VERSION "dbc-export 1 2026.26.6.5"

NS_ :

BS_:

BU_: ADSP APB APP APS APSB BB BMS CC CMP CMPD CP DAS DI DIF DIR DPB EPAS3P EPAS3S EPASTP EPASTS EPBL EPBR ESP EVSE FC GTW HCML HCMR HVP IBST ICR IDB LS OCS1P ODIN PARK PCS PCS2 PLG PM PMF PMR PNCD PTC RADC RCM RCM2 RCM3 RCU SCCM SCM SCS SDCR TAS TCU TCU2 TPMS TRCM UDS UI UIS UMC USM V2G VC VCBATT VCBATT0 VCBATT1 VCBATT2 VCCC VCFRONT VCFRONT1 VCFRONT2 VCLEFT VCRIGHT VCSEAT2L VCSEAT2R VCSEC VEH

BO_ 666 UI_seatControl: 3 UI
 SG_ UI_seatControlIndex M : 0|2@1+ (1,0) [0|3] "" Vector__XXX
 SG_ UI_3RSeatChildLock m0 : 2|2@1+ (1,0) [0|3] "" Vector__XXX
 SG_ UI_2RowLeftSeatTrackBack m0 : 4|1@1+ (1,0) [0|1] "" Vector__XXX
 SG_ UI_2RowLeftSeatTrackForward m0 : 5|1@1+ (1,0) [0|1] "" Vector__XXX
 SG_ UI_2RowRightSeatTrackBack m0 : 6|1@1+ (1,0) [0|1] "" Vector__XXX
 SG_ UI_2RowRightSeatTrackForward m0 : 7|1@1+ (1,0) [0|1] "" Vector__XXX
 SG_ UI_left3RowSeatAdjustmentRequest m0 : 8|3@1+ (1,0) [0|7] "" Vector__XXX
 SG_ UI_right3RowSeatAdjustmentReques m0 : 11|3@1+ (1,0) [0|7] "" Vector__XXX
 SG_ UI_2RLeftSeatFanReq m0 : 14|2@1+ (1,0) [0|3] "" Vector__XXX
 SG_ UI_2RRightSeatFanReq m0 : 16|2@1+ (1,0) [0|3] "" Vector__XXX
 SG_ UI_leftThirdRowSeatRequestFromRe m0 : 18|1@1+ (1,0) [0|1] "" Vector__XXX
 SG_ UI_rightThirdRowSeatRequestFromR m0 : 19|1@1+ (1,0) [0|1] "" Vector__XXX
 SG_ UI_seatChoreographyStopRequest m0 : 20|1@1+ (1,0) [0|1] "" Vector__XXX

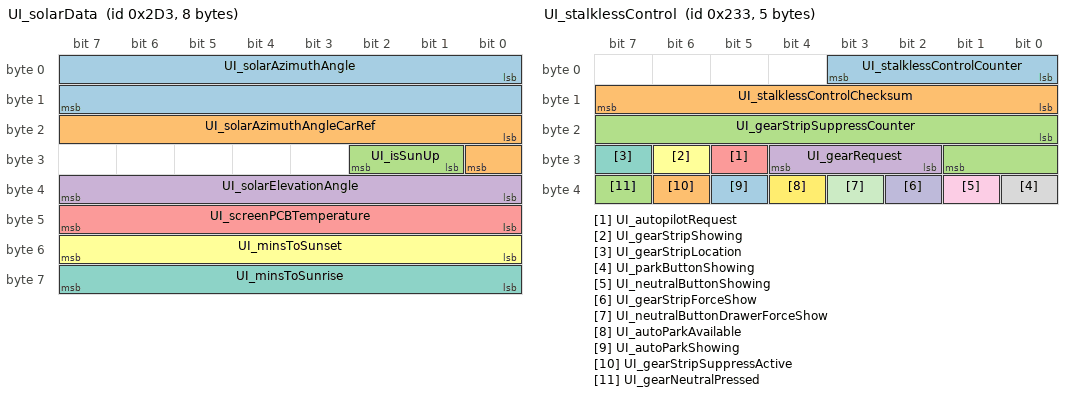
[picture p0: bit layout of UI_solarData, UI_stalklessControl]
BO_ 723 UI_solarData: 8 UI
 SG_ UI_solarAzimuthAngle : 0|16@1- (1,0) [-32768|32767] "degrees" Vector__XXX
 SG_ UI_solarAzimuthAngleCarRef : 16|9@1- (1,0) [-256|254] "degrees" Vector__XXX
 SG_ UI_isSunUp : 25|2@1+ (1,0) [0|2] "" Vector__XXX
 SG_ UI_solarElevationAngle : 32|8@1- (1,0) [-128|126] "degrees" Vector__XXX
 SG_ UI_screenPCBTemperature : 40|8@1- (0.5,40) [-20|100] "degC" Vector__XXX
 SG_ UI_minsToSunset : 48|8@1+ (10,0) [0|2550] "min" Vector__XXX
 SG_ UI_minsToSunrise : 56|8@1+ (10,0) [0|2550] "min" Vector__XXX

BO_ 563 UI_stalklessControl: 5 UI
 SG_ UI_stalklessControlCounter : 0|4@1+ (1,0) [0|15] "" Vector__XXX
 SG_ UI_stalklessControlChecksum : 8|8@1+ (1,0) [0|255] "" Vector__XXX
 SG_ UI_gearStripSuppressCounter : 16|10@1+ (1,0) [0|1023] "" Vector__XXX
 SG_ UI_gearRequest : 26|3@1+ (1,0) [1|7] "" Vector__XXX
 SG_ UI_autopilotRequest : 29|1@1+ (1,0) [0|1] "" Vector__XXX
 SG_ UI_gearStripShowing : 30|1@1+ (1,0) [0|1] "" Vector__XXX
 SG_ UI_gearStripLocation : 31|1@1+ (1,0) [0|1] "" Vector__XXX
 SG_ UI_parkButtonShowing : 32|1@1+ (1,0) [0|1] "" Vector__XXX
 SG_ UI_neutralButtonShowing : 33|1@1+ (1,0) [0|1] "" Vector__XXX
 SG_ UI_gearStripForceShow : 34|1@1+ (1,0) [0|1] "" Vector__XXX
 SG_ UI_neutralButtonDrawerForceShow : 35|1@1+ (1,0) [0|1] "" Vector__XXX
 SG_ UI_autoParkAvailable : 36|1@1+ (1,0) [0|1] "" Vector__XXX
 SG_ UI_autoParkShowing : 37|1@1+ (1,0) [0|1] "" Vector__XXX
 SG_ UI_gearStripSuppressActive : 38|1@1+ (1,0) [0|1] "" Vector__XXX
 SG_ UI_gearNeutralPressed : 39|1@1+ (1,0) [0|1] "" Vector__XXX

BO_ 851 UI_status: 8 UI
 SG_ UI_touchActive : 0|1@1+ (1,0) [0|1] "" Vector__XXX
 SG_ UI_audioActive : 1|1@1+ (1,0) [0|1] "" Vector__XXX
 SG_ UI_bluetoothActive : 2|1@1+ (1,0) [0|1] "" Vector__XXX
 SG_ UI_cellActive : 3|1@1+ (1,0) [0|1] "" Vector__XXX
 SG_ UI_displayReady : 4|1@1+ (1,0) [0|1] "" Vector__XXX
 SG_ UI_displayOn : 5|1@1+ (1,0) [0|1] "" Vector__XXX
 SG_ UI_wifiActive : 6|1@1+ (1,0) [0|1] "" Vector__XXX
 SG_ UI_wifiConnected : 7|1@1+ (1,0) [0|1] "" Vector__XXX
 SG_ UI_systemActive : 8|1@1+ (1,0) [0|1] "" Vector__XXX
 SG_ UI_readyForDrive : 9|1@1+ (1,0) [0|1] "" Vector__XXX
 SG_ UI_cellConnected : 10|1@1+ (1,0) [0|1] "" Vector__XXX
 SG_ UI_vpnActive : 11|1@1+ (1,0) [0|1] "" Vector__XXX
 SG_ UI_autopilotTrial : 12|2@1+ (1,0) [0|3] "" Vector__XXX
 SG_ UI_factoryReset : 14|2@1+ (1,0) [1|3] "" Vector__XXX
 SG_ UI_gpsActive : 16|1@1+ (1,0) [0|1] "" Vector__XXX
 SG_ UI_screenshotActive : 17|1@1+ (1,0) [0|1] "" Vector__XXX
 SG_ UI_radioActive : 18|1@1+ (1,0) [0|1] "" Vector__XXX
 SG_ UI_cellNetworkTechnology : 19|4@1+ (1,0) [0|14] "" Vector__XXX
 SG_ UI_cellReceiverPower : 24|8@1+ (1,-128) [-128|127] "dB" Vector__XXX
 SG_ UI_falseTouchCounter : 32|8@1+ (1,0) [0|255] "1" Vector__XXX
 SG_ UI_developmentCar : 40|1@1+ (1,0) [0|1] "" Vector__XXX
 SG_ UI_cameraActive : 41|1@1+ (1,0) [0|1] "" Vector__XXX
 SG_ UI_cellSignalBars : 42|3@1+ (1,0) [0|6] "" Vector__XXX
 SG_ UI_trailerModeTelltale : 45|2@1+ (1,0) [0|3] "" Vector__XXX
 SG_ UI_pcbTemperature : 48|8@1- (1,40) [-20|100] "degC" Vector__XXX
 SG_ UI_cpuTemperature : 56|8@1- (1,40) [-20|100] "degC" Vector__XXX

BO_ 991 UI_status2: 8 UI
 SG_ UI_mobileAppStepCount : 0|16@1+ (1,0) [0|65535] "" Vector__XXX
 SG_ UI_userRequestSnapshot : 16|1@1+ (1,0) [0|1] "" Vector__XXX
 SG_ UI_touchDetected : 17|1@1+ (1,0) [0|1] "" Vector__XXX
 SG_ UI_validDeviceForEUSummon : 18|1@1+ (1,0) [0|1] "" Vector__XXX
 SG_ UI_locatedAtHome : 19|1@1+ (1,0) [0|1] "" Vector__XXX
 SG_ UI_locatedAtWork : 20|1@1+ (1,0) [0|1] "" Vector__XXX
 SG_ UI_locatedAtFavorite : 21|1@1+ (1,0) [0|1] "" Vector__XXX
 SG_ UI_displayInDarkMode : 22|1@1+ (1,0) [0|1] "" Vector__XXX
 SG_ UI_userActivity : 23|1@1+ (1,0) [0|1] "" Vector__XXX
 SG_ UI_activeTouchPoints : 24|8@1+ (1,0) [0|255] "1" Vector__XXX
 SG_ UI_linkState : 32|2@1+ (1,0) [0|3] "" Vector__XXX
 SG_ UI_sentryModeState : 34|3@1+ (1,0) [0|7] "" Vector__XXX
 SG_ UI_autopilotSentryRequest : 37|1@1+ (1,0) [0|1] "" Vector__XXX
 SG_ UI_mobileAppConnected : 38|1@1+ (1,0) [0|1] "" Vector__XXX
 SG_ UI_phoneLeftInCabin : 39|1@1+ (1,0) [0|1] "" Vector__XXX
 SG_ UI_autoshiftDRState : 40|3@1+ (1,0) [0|7] "" Vector__XXX
 SG_ UI_wifiBtModuleType : 43|3@1+ (1,0) [0|7] "" Vector__XXX
 SG_ UI_sohHealthStatus : 46|2@1+ (1,0) [0|3] "" Vector__XXX
 SG_ UI_selfParkState : 48|8@1+ (1,0) [0|254] "" Vector__XXX
 SG_ UI_summonDeviceIndex : 56|2@1+ (1,0) [0|3] "" Vector__XXX
 SG_ UI_fullScreenMode : 58|1@1+ (1,0) [0|1] "" Vector__XXX
 SG_ UI_sentryModeCameraDetection : 59|1@1+ (1,0) [0|1] "" Vector__XXX
 SG_ UI_wakeOnIPActive : 60|1@1+ (1,0) [0|1] "" Vector__XXX
 SG_ UI_sapActive : 61|1@1+ (1,0) [0|1] "" Vector__XXX
 SG_ UI_sapClients : 62|1@1+ (1,0) [0|1] "" Vector__XXX
 SG_ UI_connectivityStandbyActive : 63|1@1+ (1,0) [0|1] "" Vector__XXX

BO_ 986 UI_status3: 1 UI
 SG_ UI_wifiRegDomain : 0|7@1+ (1,0) [0|127] "" Vector__XXX
 SG_ UI_wifiTethered : 7|1@1+ (1,0) [0|1] "" Vector__XXX

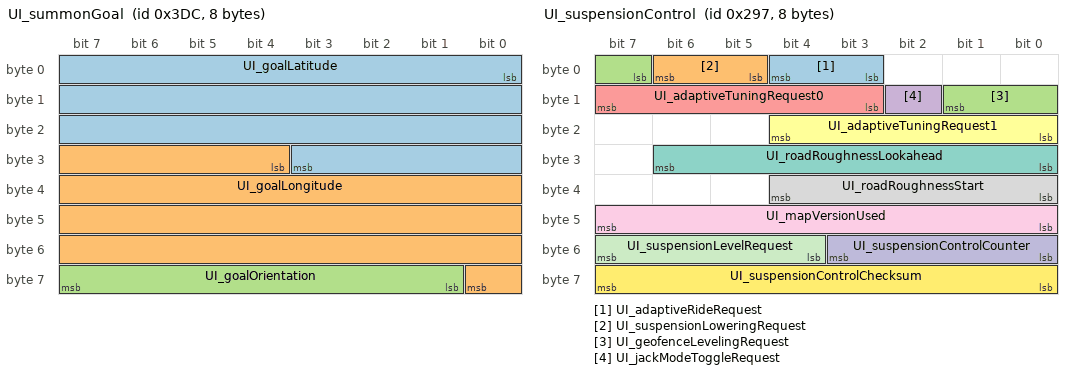
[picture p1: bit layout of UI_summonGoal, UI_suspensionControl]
BO_ 988 UI_summonGoal: 8 UI
 SG_ UI_goalLatitude : 0|28@1- (1.0e-06,0) [-134.217728|134.217727] "deg" Vector__XXX
 SG_ UI_goalLongitude : 28|29@1- (1.0e-06,0) [-268.435456|268.435455] "deg" Vector__XXX
 SG_ UI_goalOrientation : 57|7@1+ (2.8125,0) [0|357.1875] "deg" Vector__XXX

BO_ 663 UI_suspensionControl: 8 UI
 SG_ UI_adaptiveRideRequest : 3|2@1+ (1,0) [0|3] "" Vector__XXX
 SG_ UI_suspensionLoweringRequest : 5|2@1+ (1,0) [0|2] "" Vector__XXX
 SG_ UI_geofenceLevelingRequest : 7|3@1+ (1,0) [0|7] "" Vector__XXX
 SG_ UI_jackModeToggleRequest : 10|1@1+ (1,0) [0|1] "" Vector__XXX
 SG_ UI_adaptiveTuningRequest0 : 11|5@1- (0.1,0) [-1.6|1.5] "-" Vector__XXX
 SG_ UI_adaptiveTuningRequest1 : 16|5@1- (0.1,0) [-1.6|1.5] "-" Vector__XXX
 SG_ UI_roadRoughnessLookahead : 24|7@1+ (0.01,0) [0|1.26] "%" Vector__XXX
 SG_ UI_roadRoughnessStart : 32|5@1+ (10,0) [0|300] "m" Vector__XXX
 SG_ UI_mapVersionUsed : 40|8@1+ (1,0) [0|254] "-" Vector__XXX
 SG_ UI_suspensionControlCounter : 48|4@1+ (1,0) [0|15] "" Vector__XXX
 SG_ UI_suspensionLevelRequest : 52|4@1+ (1,0) [0|15] "" Vector__XXX
 SG_ UI_suspensionControlChecksum : 56|8@1+ (1,0) [0|255] "" Vector__XXX

BO_ 661 UI_systemMonitor: 8 UI
 SG_ UI_systemMonitorIndex M : 0|1@1+ (1,0) [0|1] "" Vector__XXX
 SG_ UI_SystemMemUsage m0 : 8|16@1+ (1,0) [0|65535] "MB" Vector__XXX
 SG_ UI_QtCarMemUsage m0 : 24|16@1+ (1,0) [0|65535] "MB" Vector__XXX
 SG_ UI_QtCarCPUUsage m0 : 40|7@1+ (1,0) [0|127] "%" Vector__XXX
 SG_ UI_emmcStatus m0 : 47|1@1+ (1,0) [0|1] "" Vector__XXX
 SG_ UI_SystemCPUUsage m0 : 48|7@1+ (1,0) [0|127] "%" Vector__XXX
 SG_ UI_HomeHealth m0 : 55|1@1+ (1,0) [0|1] "" Vector__XXX
 SG_ UI_VarHealth m0 : 56|1@1+ (1,0) [0|1] "" Vector__XXX
 SG_ UI_LogHealth m0 : 57|1@1+ (1,0) [0|1] "" Vector__XXX
 SG_ UI_TmpfsHealth m0 : 58|1@1+ (1,0) [0|1] "" Vector__XXX
 SG_ UI_emmcDataWritten m1 : 8|24@1+ (1,0) [0|16777215] "" Vector__XXX
 SG_ UI_emmcTotalErases m1 : 32|16@1+ (1,0) [0|65535] "" Vector__XXX

BO_ 1064 UI_telemetryControl: 8 UI
 SG_ UI_TCR_enable : 0|1@1+ (1,0) [0|1] "" Vector__XXX
 SG_ UI_TCR_moveStateStanding : 1|1@1+ (1,0) [0|1] "" Vector__XXX
 SG_ UI_TCR_moveStateStopped : 2|1@1+ (1,0) [0|1] "" Vector__XXX
 SG_ UI_TCR_moveStateMoving : 3|1@1+ (1,0) [0|1] "" Vector__XXX
 SG_ UI_TCR_moveStateIndeterm : 4|1@1+ (1,0) [0|1] "" Vector__XXX
 SG_ UI_TCR_classConstElem : 5|1@1+ (1,0) [0|1] "" Vector__XXX
 SG_ UI_TCR_classMovingPed : 6|1@1+ (1,0) [0|1] "" Vector__XXX
 SG_ UI_TCR_classMovingTwoWheel : 7|1@1+ (1,0) [0|1] "" Vector__XXX
 SG_ UI_TCR_classMovingFourWheel : 8|1@1+ (1,0) [0|1] "" Vector__XXX
 SG_ UI_TCR_classUnknown : 9|1@1+ (1,0) [0|1] "" Vector__XXX
 SG_ UI_TCR_downSampleFactor : 10|4@1+ (1,0) [0|15] "" Vector__XXX
 SG_ UI_TCR_wExist : 24|5@1+ (1,0) [0|31] "" Vector__XXX
 SG_ UI_TCR_vehSpeed : 32|8@1+ (1,0) [0|255] "" Vector__XXX
 SG_ UI_TCR_minRCS : 40|8@1+ (0.25,-14) [-14|49.75] "dB" Vector__XXX
 SG_ UI_TCR_maxDy : 48|5@1+ (0.5,0) [0|15.5] "m" Vector__XXX
 SG_ UI_TCR_maxObjects : 56|5@1+ (1,0) [0|31] "" Vector__XXX
 SG_ UI_TCR_maxRoadClass : 61|3@1+ (1,0) [0|7] "" Vector__XXX

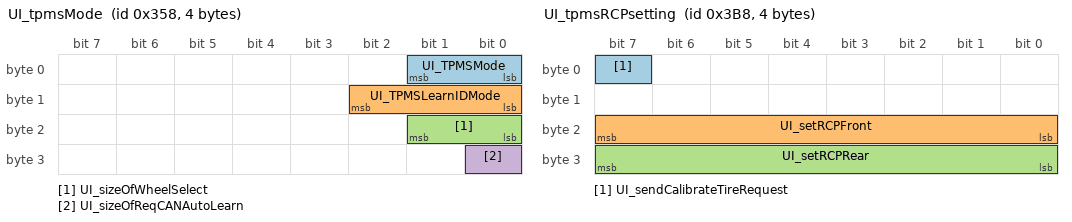
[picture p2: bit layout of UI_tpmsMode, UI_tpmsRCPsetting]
BO_ 856 UI_tpmsMode: 4 UI
 SG_ UI_TPMSMode : 0|2@1+ (1,0) [0|3] "" Vector__XXX
 SG_ UI_TPMSLearnIDMode : 8|3@1+ (1,0) [0|7] "" Vector__XXX
 SG_ UI_sizeOfWheelSelect : 16|2@1+ (1,0) [0|3] "" Vector__XXX
 SG_ UI_sizeOfReqCANAutoLearn : 24|1@1+ (1,0) [0|1] "" Vector__XXX

BO_ 952 UI_tpmsRCPsetting: 4 UI
 SG_ UI_sendCalibrateTireRequest : 7|1@1+ (1,0) [0|1] "" Vector__XXX
 SG_ UI_setRCPFront : 16|8@1+ (0.025,0) [0|6.375] "bar" Vector__XXX
 SG_ UI_setRCPRear : 24|8@1+ (0.025,0) [0|6.375] "bar" Vector__XXX

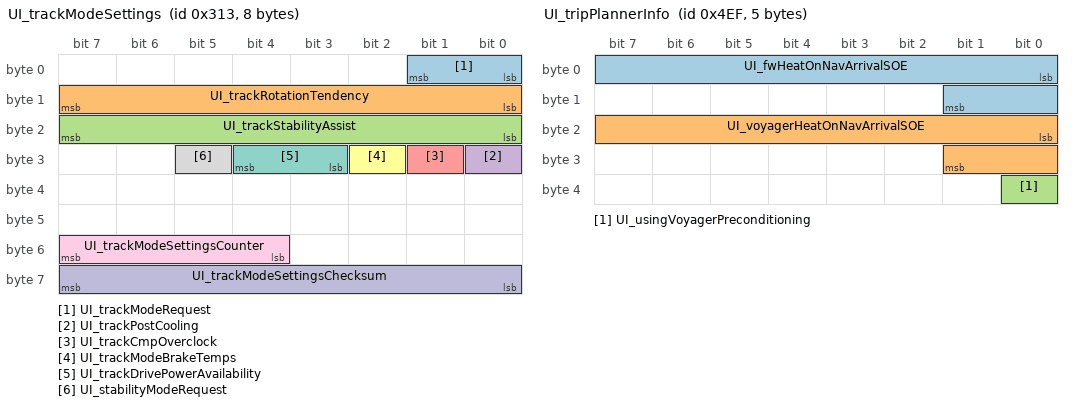
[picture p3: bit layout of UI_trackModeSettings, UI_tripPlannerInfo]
BO_ 787 UI_trackModeSettings: 8 UI
 SG_ UI_trackModeRequest : 0|2@1+ (1,0) [0|3] "" Vector__XXX
 SG_ UI_trackRotationTendency : 8|8@1+ (0.5,0) [0|127.5] "%" Vector__XXX
 SG_ UI_trackStabilityAssist : 16|8@1+ (0.5,0) [0|127.5] "%" Vector__XXX
 SG_ UI_trackPostCooling : 24|1@1+ (1,0) [0|1] "" Vector__XXX
 SG_ UI_trackCmpOverclock : 25|1@1+ (1,0) [0|1] "" Vector__XXX
 SG_ UI_trackModeBrakeTemps : 26|1@1+ (1,0) [0|1] "" Vector__XXX
 SG_ UI_trackDrivePowerAvailability : 27|2@1+ (1,0) [0|3] "" Vector__XXX
 SG_ UI_stabilityModeRequest : 29|1@1+ (1,0) [0|1] "" Vector__XXX
 SG_ UI_trackModeSettingsCounter : 52|4@1+ (1,0) [0|15] "" Vector__XXX
 SG_ UI_trackModeSettingsChecksum : 56|8@1+ (1,0) [0|255] "" Vector__XXX

BO_ 1263 UI_tripPlannerInfo: 5 UI
 SG_ UI_fwHeatOnNavArrivalSOE : 0|10@1+ (0.1,0) [0|100] "%" Vector__XXX
 SG_ UI_voyagerHeatOnNavArrivalSOE : 16|10@1+ (0.1,0) [0|100] "%" Vector__XXX
 SG_ UI_usingVoyagerPreconditioning : 32|1@1+ (1,0) [0|1] "" Vector__XXX

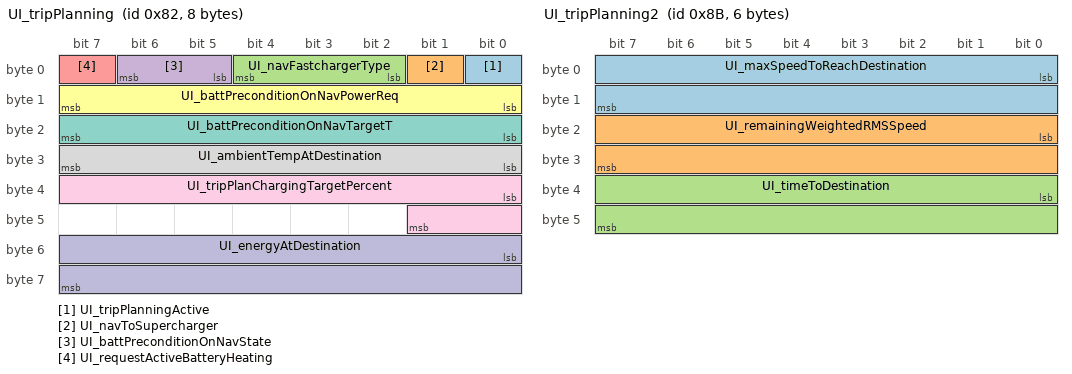
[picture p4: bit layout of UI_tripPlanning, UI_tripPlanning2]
BO_ 130 UI_tripPlanning: 8 UI
 SG_ UI_tripPlanningActive : 0|1@1+ (1,0) [0|1] "" Vector__XXX
 SG_ UI_navToSupercharger : 1|1@1+ (1,0) [0|1] "" Vector__XXX
 SG_ UI_navFastchargerType : 2|3@1+ (1,0) [0|7] "" Vector__XXX
 SG_ UI_battPreconditionOnNavState : 5|2@1+ (1,0) [0|3] "" Vector__XXX
 SG_ UI_requestActiveBatteryHeating : 7|1@1+ (1,0) [0|1] "" Vector__XXX
 SG_ UI_battPreconditionOnNavPowerReq : 8|8@1- (125,0) [-16000|15750] "W" Vector__XXX
 SG_ UI_battPreconditionOnNavTargetT : 16|8@1+ (0.25,0) [0|63.5] "degC" Vector__XXX
 SG_ UI_ambientTempAtDestination : 24|8@1- (0.5,0) [-64|63.5] "degC" Vector__XXX
 SG_ UI_tripPlanChargingTargetPercent : 32|10@1+ (0.1,0) [0|102.2] "%" Vector__XXX
 SG_ UI_energyAtDestination : 48|16@1- (0.01,0) [-327.67|327.67] "kWh" Vector__XXX

BO_ 139 UI_tripPlanning2: 6 UI
 SG_ UI_maxSpeedToReachDestination : 0|16@1+ (0.01,0) [0|655.34] "m/s" Vector__XXX
 SG_ UI_remainingWeightedRMSSpeed : 16|16@1+ (0.01,0) [0|655.34] "m/s" Vector__XXX
 SG_ UI_timeToDestination : 32|16@1+ (1,0) [0|65534] "s" Vector__XXX

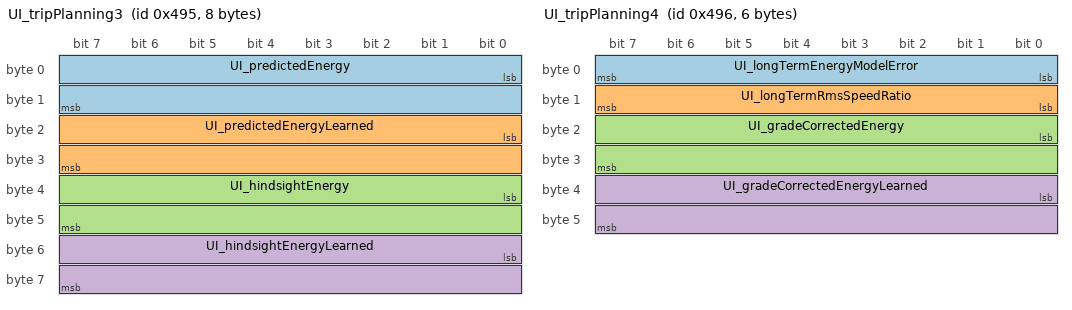
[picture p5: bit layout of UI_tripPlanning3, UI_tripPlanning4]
BO_ 1173 UI_tripPlanning3: 8 UI
 SG_ UI_predictedEnergy : 0|16@1- (0.01,0) [-327.67|327.67] "kWh" Vector__XXX
 SG_ UI_predictedEnergyLearned : 16|16@1- (0.01,0) [-327.68|327.67] "kWh" Vector__XXX
 SG_ UI_hindsightEnergy : 32|16@1- (0.01,0) [-327.67|327.67] "kWh" Vector__XXX
 SG_ UI_hindsightEnergyLearned : 48|16@1- (0.01,0) [-327.68|327.67] "kWh" Vector__XXX

BO_ 1174 UI_tripPlanning4: 6 UI
 SG_ UI_longTermEnergyModelError : 0|8@1- (0.5,0) [-64|63.5] "whpm" Vector__XXX
 SG_ UI_longTermRmsSpeedRatio : 8|8@1+ (0.01,0) [0|2.54] "1" Vector__XXX
 SG_ UI_gradeCorrectedEnergy : 16|16@1- (0.01,0) [-327.68|327.67] "kWh" Vector__XXX
 SG_ UI_gradeCorrectedEnergyLearned : 32|16@1- (0.01,0) [-327.68|327.67] "kWh" Vector__XXX

BO_ 1175 UI_tripPlanning5: 4 UI
 SG_ UI_battPreconditionOnNavTime : 0|16@1+ (1,0) [0|65534] "s" Vector__XXX
 SG_ UI_maxBattPreconditionOnNavTime : 16|16@1+ (1,0) [0|65534] "s" Vector__XXX

BO_ 850 UI_uiHealthStatus: 6 UI
 SG_ UI_centerDisplayRunning : 0|1@1+ (1,0) [0|1] "" Vector__XXX
 SG_ UI_centerDisplaySM : 1|3@1+ (1,0) [0|7] "" Vector__XXX
 SG_ UI_centerDisplayPowerOn : 4|1@1+ (1,0) [0|1] "" Vector__XXX
 SG_ UI_centerDisplayCrtcOk : 5|1@1+ (1,0) [0|1] "" Vector__XXX
 SG_ UI_centerDisplayHardwareOk : 6|1@1+ (1,0) [0|1] "" Vector__XXX
 SG_ UI_centerDisplayWindowManagerOk : 7|1@1+ (1,0) [0|1] "" Vector__XXX
 SG_ UI_centerDisplayCompositorOk : 8|1@1+ (1,0) [0|1] "" Vector__XXX
 SG_ UI_apVisualizationOk : 9|1@1+ (1,0) [0|1] "" Vector__XXX
 SG_ UI_autonomyCenterDispStatus : 10|2@1+ (1,0) [1|3] "" Vector__XXX
 SG_ UI_autonomyRearDispStatus : 12|2@1+ (1,0) [1|3] "" Vector__XXX
 SG_ UI_autonomyConnectivityStatus : 14|2@1+ (1,0) [1|3] "" Vector__XXX
 SG_ UI_autonomyConnectivtyHWOk : 16|1@1+ (1,0) [0|1] "" Vector__XXX
 SG_ UI_autonomyQtCarStatus : 17|2@1+ (1,0) [1|3] "" Vector__XXX
 SG_ UI_autonomyQtCarRearStatus : 19|2@1+ (1,0) [1|3] "" Vector__XXX
 SG_ UI_autonomyDASServerStatus : 21|2@1+ (1,0) [1|3] "" Vector__XXX
 SG_ UI_rearDisplayRunning : 23|1@1+ (1,0) [0|1] "" Vector__XXX
 SG_ UI_rearDisplayPowerOn : 24|1@1+ (1,0) [0|1] "" Vector__XXX
 SG_ UI_rearDisplaySM : 25|3@1+ (1,0) [0|7] "" Vector__XXX
 SG_ UI_rearDisplayCrtcOk : 28|1@1+ (1,0) [0|1] "" Vector__XXX
 SG_ UI_rearDisplayHardwareOk : 29|1@1+ (1,0) [0|1] "" Vector__XXX
 SG_ UI_rearDisplayWindowManagerOk : 30|1@1+ (1,0) [0|1] "" Vector__XXX
 SG_ UI_rearDisplayCompositorOk : 31|1@1+ (1,0) [0|1] "" Vector__XXX

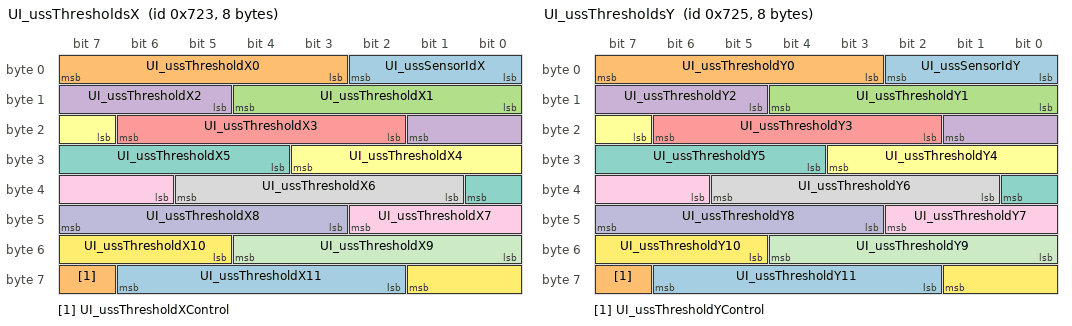
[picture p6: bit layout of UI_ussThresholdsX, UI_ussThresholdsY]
BO_ 1827 UI_ussThresholdsX: 8 UI
 SG_ UI_ussSensorIdX : 0|3@1+ (1,0) [0|7] "" Vector__XXX
 SG_ UI_ussThresholdX0 : 3|5@1+ (1,0) [0|31] "" Vector__XXX
 SG_ UI_ussThresholdX1 : 8|5@1+ (1,0) [0|31] "" Vector__XXX
 SG_ UI_ussThresholdX2 : 13|5@1+ (1,0) [0|31] "" Vector__XXX
 SG_ UI_ussThresholdX3 : 18|5@1+ (1,0) [0|31] "" Vector__XXX
 SG_ UI_ussThresholdX4 : 23|5@1+ (1,0) [0|31] "" Vector__XXX
 SG_ UI_ussThresholdX5 : 28|5@1+ (1,0) [0|31] "" Vector__XXX
 SG_ UI_ussThresholdX6 : 33|5@1+ (1,0) [0|31] "" Vector__XXX
 SG_ UI_ussThresholdX7 : 38|5@1+ (1,0) [0|31] "" Vector__XXX
 SG_ UI_ussThresholdX8 : 43|5@1+ (1,0) [0|31] "" Vector__XXX
 SG_ UI_ussThresholdX9 : 48|5@1+ (1,0) [0|31] "" Vector__XXX
 SG_ UI_ussThresholdX10 : 53|5@1+ (1,0) [0|31] "" Vector__XXX
 SG_ UI_ussThresholdX11 : 58|5@1+ (1,0) [0|31] "" Vector__XXX
 SG_ UI_ussThresholdXControl : 63|1@1+ (1,0) [0|1] "" Vector__XXX

BO_ 1829 UI_ussThresholdsY: 8 UI
 SG_ UI_ussSensorIdY : 0|3@1+ (1,0) [0|7] "" Vector__XXX
 SG_ UI_ussThresholdY0 : 3|5@1+ (1,0) [0|31] "" Vector__XXX
 SG_ UI_ussThresholdY1 : 8|5@1+ (1,0) [0|31] "" Vector__XXX
 SG_ UI_ussThresholdY2 : 13|5@1+ (1,0) [0|31] "" Vector__XXX
 SG_ UI_ussThresholdY3 : 18|5@1+ (1,0) [0|31] "" Vector__XXX
 SG_ UI_ussThresholdY4 : 23|5@1+ (1,0) [0|31] "" Vector__XXX
 SG_ UI_ussThresholdY5 : 28|5@1+ (1,0) [0|31] "" Vector__XXX
 SG_ UI_ussThresholdY6 : 33|5@1+ (1,0) [0|31] "" Vector__XXX
 SG_ UI_ussThresholdY7 : 38|5@1+ (1,0) [0|31] "" Vector__XXX
 SG_ UI_ussThresholdY8 : 43|5@1+ (1,0) [0|31] "" Vector__XXX
 SG_ UI_ussThresholdY9 : 48|5@1+ (1,0) [0|31] "" Vector__XXX
 SG_ UI_ussThresholdY10 : 53|5@1+ (1,0) [0|31] "" Vector__XXX
 SG_ UI_ussThresholdY11 : 58|5@1+ (1,0) [0|31] "" Vector__XXX
 SG_ UI_ussThresholdYControl : 63|1@1+ (1,0) [0|1] "" Vector__XXX

BO_ 627 UI_vehicleControl: 8 UI
 SG_ UI_powerStateRequest : 0|2@1+ (1,0) [0|3] "" Vector__XXX
 SG_ UI_childDoorLockOnRight : 2|1@1+ (1,0) [0|1] "" Vector__XXX
 SG_ UI_frontFogSwitch : 3|1@1+ (1,0) [0|1] "" Vector__XXX
 SG_ UI_summonActive : 4|1@1+ (1,0) [0|1] "" Vector__XXX
 SG_ UI_frunkRequest : 5|1@1+ (1,0) [0|1] "" Vector__XXX
 SG_ UI_wiperMode : 6|2@1+ (1,0) [1|3] "" Vector__XXX
 SG_ UI_steeringBacklightEnabled : 8|1@1+ (1,0) [0|1] "" Vector__XXX
 SG_ UI_steeringButtonMode : 9|3@1+ (1,0) [0|7] "" Vector__XXX
 SG_ UI_walkUpUnlock : 12|1@1+ (1,0) [0|1] "" Vector__XXX
 SG_ UI_walkAwayLock : 13|1@1+ (1,0) [0|1] "" Vector__XXX
 SG_ UI_unlockOnPark : 14|1@1+ (1,0) [0|1] "" Vector__XXX
 SG_ UI_globalUnlockOn : 15|1@1+ (1,0) [0|1] "" Vector__XXX
 SG_ UI_childDoorLockOnLeft : 16|1@1+ (1,0) [0|1] "" Vector__XXX
 SG_ UI_lockRequest : 17|3@1+ (1,0) [0|6] "" Vector__XXX
 SG_ UI_alarmEnabled : 20|1@1+ (1,0) [0|1] "" Vector__XXX
 SG_ UI_intrusionSensorOn : 21|1@1+ (1,0) [0|1] "" Vector__XXX
 SG_ UI_stop12vSupport : 22|1@1+ (1,0) [0|1] "" Vector__XXX
 SG_ UI_rearFogSwitch : 23|1@1+ (1,0) [0|1] "" Vector__XXX
 SG_ UI_mirrorFoldRequest : 24|2@1+ (1,0) [0|2] "" Vector__XXX
 SG_ UI_mirrorHeatRequest : 26|1@1+ (1,0) [0|1] "" Vector__XXX
 SG_ UI_remoteStartRequest : 27|3@1+ (1,0) [0|7] "" Vector__XXX
 SG_ UI_seeYouHomeLightingOn : 30|1@1+ (1,0) [0|1] "" Vector__XXX
 SG_ UI_powerOff : 31|1@1+ (1,0) [0|1] "" Vector__XXX
 SG_ UI_displayBrightnessLevel : 32|8@1+ (0.5,0) [0|127] "%" Vector__XXX
 SG_ UI_ambientLightingEnabled : 40|1@1+ (1,0) [0|1] "" Vector__XXX
 SG_ UI_autoHighBeamEnabled : 41|1@1+ (1,0) [0|1] "" Vector__XXX
 SG_ UI_frontLeftSeatHeatReq : 42|2@1+ (1,0) [0|3] "" Vector__XXX
 SG_ UI_frontRightSeatHeatReq : 44|2@1+ (1,0) [0|3] "" Vector__XXX
 SG_ UI_rearLeftSeatHeatReq : 46|2@1+ (1,0) [0|3] "" Vector__XXX
 SG_ UI_rearCenterSeatHeatReq : 48|2@1+ (1,0) [0|3] "" Vector__XXX
 SG_ UI_rearRightSeatHeatReq : 50|2@1+ (1,0) [0|3] "" Vector__XXX
 SG_ UI_autoFoldMirrorsOn : 52|1@1+ (1,0) [0|1] "" Vector__XXX
 SG_ UI_mirrorDipOnReverse : 53|1@1+ (1,0) [0|1] "" Vector__XXX
 SG_ UI_remoteClosureRequest : 54|2@1+ (1,0) [0|2] "" Vector__XXX
 SG_ UI_wiperRequest : 56|3@1+ (1,0) [1|7] "" Vector__XXX
 SG_ UI_domeLightSwitch : 59|2@1+ (1,0) [0|3] "" Vector__XXX
 SG_ UI_honkHorn : 61|1@1+ (1,0) [0|1] "" Vector__XXX
 SG_ UI_driveStateRequest : 62|1@1+ (1,0) [0|1] "" Vector__XXX
 SG_ UI_rearWindowLockout : 63|1@1+ (1,0) [0|1] "" Vector__XXX

BO_ 947 UI_vehicleControl2: 8 UI
 SG_ UI_gloveboxRequest : 0|1@1+ (1,0) [0|1] "" Vector__XXX
 SG_ UI_trunkRequest : 1|1@1+ (1,0) [0|1] "" Vector__XXX
 SG_ UI_UMCUpdateInhibit : 2|1@1+ (1,0) [0|1] "" Vector__XXX
 SG_ UI_WCUpdateInhibit : 3|1@1+ (1,0) [0|1] "" Vector__XXX
 SG_ UI_soundHornOnLock : 4|1@1+ (1,0) [0|1] "" Vector__XXX
 SG_ UI_locksPanelActive : 5|1@1+ (1,0) [0|1] "" Vector__XXX
 SG_ UI_PINToDriveEnabled : 6|1@1+ (1,0) [0|1] "" Vector__XXX
 SG_ UI_PINToDrivePassed : 7|1@1+ (1,0) [0|1] "" Vector__XXX
 SG_ UI_disableMirrorAutoDim : 8|1@1+ (1,0) [0|1] "" Vector__XXX
 SG_ UI_lightSwitch : 9|3@1+ (1,0) [0|7] "" Vector__XXX
 SG_ UI_readyToAddKey : 12|1@1+ (1,0) [0|1] "" Vector__XXX
 SG_ UI_alarmTriggerRequest : 13|1@1+ (1,0) [0|1] "" Vector__XXX
 SG_ UI_VCSECFeature1 : 14|1@1+ (1,0) [0|1] "" Vector__XXX
 SG_ UI_VCLEFTFeature1 : 15|1@1+ (1,0) [0|1] "" Vector__XXX
 SG_ UI_summonState : 16|2@1+ (1,0) [1|3] "" Vector__XXX
 SG_ UI_displayOnForUser : 18|1@1+ (1,0) [0|1] "" Vector__XXX
 SG_ UI_freeRollModeRequest : 19|1@1+ (1,0) [0|1] "" Vector__XXX
 SG_ UI_BLEPushNotificationRequest : 20|1@1+ (1,0) [0|1] "" Vector__XXX
 SG_ UI_pairKeyQRCodeDisplaying : 21|1@1+ (1,0) [0|1] "" Vector__XXX
 SG_ UI_keepAutopilotAwake : 22|1@1+ (1,0) [0|1] "" Vector__XXX
 SG_ UI_batteryPreconditioningRequest : 23|1@1+ (1,0) [0|1] "" Vector__XXX
 SG_ UI_coastDownMode : 24|1@1+ (1,0) [0|1] "" Vector__XXX
 SG_ UI_autopilotPowerStateRequest : 25|2@1+ (1,0) [0|3] "" Vector__XXX
 SG_ UI_shorted12VCellTestMode : 27|2@1+ (1,0) [0|3] "" Vector__XXX
 SG_ UI_autoRollWindowsOnLockEnable : 29|1@1+ (1,0) [0|1] "" Vector__XXX
 SG_ UI_virtualPitchSensorOverrideOKF : 30|1@1+ (1,0) [0|1] "" Vector__XXX
 SG_ UI_conditionalLoggingEnabledVCSE : 31|1@1+ (1,0) [0|1] "" Vector__XXX
 SG_ UI_WC3UpdateInhibit : 32|1@1+ (1,0) [0|1] "" Vector__XXX
 SG_ UI_steeringWheelHeatReq : 33|1@1+ (1,0) [0|1] "" Vector__XXX
 SG_ UI_disableHorn : 34|1@1+ (1,0) [0|1] "" Vector__XXX
 SG_ UI_frontLeftSeatFanReq : 37|2@1+ (1,0) [0|3] "" Vector__XXX
 SG_ UI_frontRightSeatAutoClimateReq : 39|1@1+ (1,0) [0|1] "" Vector__XXX
 SG_ UI_frontRightSeatFanReq : 40|2@1+ (1,0) [0|3] "" Vector__XXX
 SG_ UI_3RLeftSeatHeatReq : 44|2@1+ (1,0) [0|3] "" Vector__XXX
 SG_ UI_3RRightSeatHeatReq : 46|2@1+ (1,0) [0|3] "" Vector__XXX
 SG_ UI_sleepFeature1 : 51|1@1+ (1,0) [0|1] "" Vector__XXX
 SG_ UI_dcr12VThreshold : 52|4@1+ (1,0) [0|15] "" Vector__XXX
 SG_ UI_frontLeftSeatAutoClimateReq : 56|1@1+ (1,0) [0|1] "" Vector__XXX
 SG_ UI_wiperHeaterReq : 57|1@1+ (1,0) [0|1] "" Vector__XXX
 SG_ UI_tireSeason : 59|1@1+ (1,0) [0|1] "" Vector__XXX
 SG_ UI_saveTireConfigReq : 60|1@1+ (1,0) [0|1] "" Vector__XXX
 SG_ UI_silentAlarm : 61|1@1+ (1,0) [0|1] "" Vector__XXX
 SG_ UI_sleepFeature2 : 63|1@1+ (1,0) [0|1] "" Vector__XXX

BO_ 628 UI_vehicleControl3: 8 UI
 SG_ UI_lightFlashRequest : 0|2@1+ (1,0) [0|3] "" Vector__XXX
 SG_ UI_keylessDrivingEnabled : 2|1@1+ (1,0) [0|1] "" Vector__XXX
 SG_ UI_phoneCallActive : 3|1@1+ (1,0) [0|1] "" Vector__XXX
 SG_ UI_drivingSideVEH : 4|2@1+ (1,0) [0|3] "" Vector__XXX
 SG_ UI_keyPairResponse : 6|2@1+ (1,0) [0|3] "" Vector__XXX
 SG_ UI_lightShowClosuresEnabled : 8|1@1+ (1,0) [0|1] "" Vector__XXX
 SG_ UI_steeringWheelHeatAutoReq : 9|1@1+ (1,0) [0|1] "" Vector__XXX
 SG_ UI_steeringWheelHeatLevelReq : 10|2@1+ (1,0) [0|3] "" Vector__XXX
 SG_ UI_headlightPulseRequest : 12|1@1+ (1,0) [0|1] "" Vector__XXX
 SG_ UI_VCSECFeature2 : 13|1@1+ (1,0) [0|1] "" Vector__XXX
 SG_ UI_VCSECFeature3 : 14|1@1+ (1,0) [0|1] "" Vector__XXX
 SG_ UI_VCSECFeature4 : 15|1@1+ (1,0) [0|1] "" Vector__XXX
 SG_ UI_VCSECFeature5 : 16|1@1+ (1,0) [0|1] "" Vector__XXX
 SG_ UI_shortHornRequest : 17|1@1+ (1,0) [0|1] "" Vector__XXX
 SG_ UI_packTempLoggingRequest : 18|1@1+ (1,0) [0|1] "" Vector__XXX
 SG_ UI_UMC3UpdateInhibit : 22|1@1+ (1,0) [0|1] "" Vector__XXX
 SG_ UI_handsFreeTrunk : 23|1@1+ (1,0) [0|1] "" Vector__XXX
 SG_ UI_displayRedShiftActive : 24|1@1+ (1,0) [0|1] "" Vector__XXX
 SG_ UI_handsFreeFrunk : 25|1@1+ (1,0) [0|1] "" Vector__XXX
 SG_ UI_fasciaCameraWashRequest : 26|1@1+ (1,0) [0|1] "" Vector__XXX
 SG_ UI_autoClosuresExcludeHome : 27|1@1+ (1,0) [0|1] "" Vector__XXX
 SG_ UI_leftRearSeatAdjustmentRequest : 28|3@1+ (1,0) [0|7] "" Vector__XXX
 SG_ UI_rightRearSeatAdjustmentReques : 32|3@1+ (1,0) [0|7] "" Vector__XXX
 SG_ UI_blindSpotIndicatorLightReques : 35|1@1+ (1,0) [0|1] "" Vector__XXX
 SG_ UI_etcBluetoothControl : 36|2@1+ (1,0) [0|3] "" Vector__XXX
 SG_ UI_keepOnAccessoryPortsReq : 38|1@1+ (1,0) [0|1] "" Vector__XXX
 SG_ UI_fasciaCameraShown : 39|1@1+ (1,0) [0|1] "" Vector__XXX
 SG_ UI_rearSeatChildLock : 40|2@1+ (1,0) [0|3] "" Vector__XXX
 SG_ UI_windowPercentageRequest : 42|6@1- (5,0) [-100|100] "%" Vector__XXX
 SG_ UI_windowRequestedFL : 48|1@1+ (1,0) [0|1] "" Vector__XXX
 SG_ UI_windowRequestedFR : 49|1@1+ (1,0) [0|1] "" Vector__XXX
 SG_ UI_windowRequestedRL : 50|1@1+ (1,0) [0|1] "" Vector__XXX
 SG_ UI_windowRequestedRR : 51|1@1+ (1,0) [0|1] "" Vector__XXX
 SG_ UI_windowRequest : 52|3@1+ (1,0) [0|7] "" Vector__XXX
 SG_ UI_closeTrunkRequest : 55|1@1+ (1,0) [0|1] "" Vector__XXX
 SG_ UI_childPresenceDetectionDisable : 56|1@1+ (1,0) [0|1] "" Vector__XXX
 SG_ UI_V2LAUpdateInhibit : 57|1@1+ (1,0) [0|1] "" Vector__XXX
 SG_ UI_userPresenceDetectionEnabled : 58|1@1+ (1,0) [0|1] "" Vector__XXX
 SG_ UI_derivedLoadshedFeature : 59|1@1+ (1,0) [0|1] "" Vector__XXX
 SG_ UI_rearSeatFoldConfirmed : 60|1@1+ (1,0) [0|1] "" Vector__XXX
 SG_ UI_leftRearSeatRequestFromRearDi : 61|1@1+ (1,0) [0|1] "" Vector__XXX
 SG_ UI_selfParkStandingBy : 62|1@1+ (1,0) [0|1] "" Vector__XXX
 SG_ UI_rightRearSeatRequestFromRearD : 63|1@1+ (1,0) [0|1] "" Vector__XXX

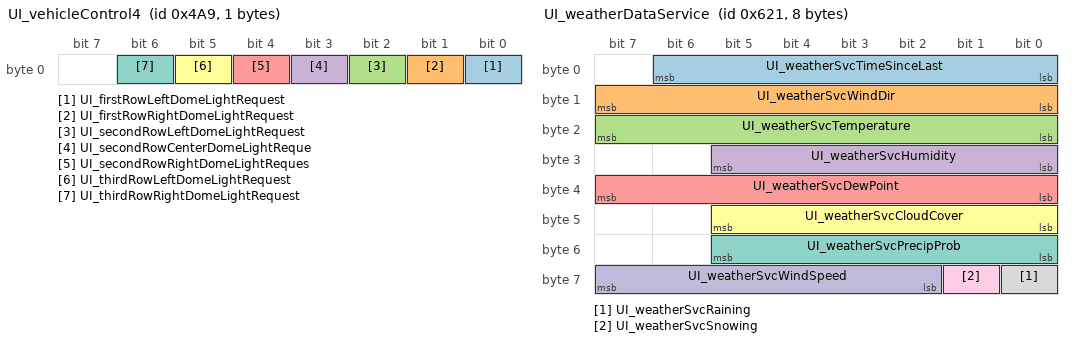
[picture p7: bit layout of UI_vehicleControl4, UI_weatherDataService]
BO_ 1193 UI_vehicleControl4: 1 UI
 SG_ UI_firstRowLeftDomeLightRequest : 0|1@1+ (1,0) [0|1] "" Vector__XXX
 SG_ UI_firstRowRightDomeLightRequest : 1|1@1+ (1,0) [0|1] "" Vector__XXX
 SG_ UI_secondRowLeftDomeLightRequest : 2|1@1+ (1,0) [0|1] "" Vector__XXX
 SG_ UI_secondRowCenterDomeLightReque : 3|1@1+ (1,0) [0|1] "" Vector__XXX
 SG_ UI_secondRowRightDomeLightReques : 4|1@1+ (1,0) [0|1] "" Vector__XXX
 SG_ UI_thirdRowLeftDomeLightRequest : 5|1@1+ (1,0) [0|1] "" Vector__XXX
 SG_ UI_thirdRowRightDomeLightRequest : 6|1@1+ (1,0) [0|1] "" Vector__XXX

BO_ 853 UI_vehicleControlThermal: 7 UI
 SG_ UI_coolantFlowRequest : 0|5@1+ (1,0) [0|25] "LPM" Vector__XXX
 SG_ UI_inletActiveCoolTarget : 5|7@1+ (1,0) [0|127] "degC" Vector__XXX
 SG_ UI_disableHVPTThermalLoads : 12|1@1+ (1,0) [0|1] "" Vector__XXX
 SG_ UI_enableCompLiquidPumpOut : 13|1@1+ (1,0) [0|1] "" Vector__XXX
 SG_ UI_enableCOP1HighSHOperation : 14|1@1+ (1,0) [0|1] "" Vector__XXX
 SG_ UI_enableIncreasedEvapRampRate : 15|1@1+ (1,0) [0|1] "" Vector__XXX
 SG_ UI_enableCOP1BatteryHeating : 16|1@1+ (1,0) [0|1] "" Vector__XXX
 SG_ UI_enableCOP1CabinHeatingBattery : 17|1@1+ (1,0) [0|1] "" Vector__XXX
 SG_ UI_enableLouverAutoDetection : 18|1@1+ (1,0) [0|1] "" Vector__XXX
 SG_ UI_enableUserFacingLowFlowDelive : 19|1@1+ (1,0) [0|1] "" Vector__XXX
 SG_ UI_disableHvacCameraOnlyDefog : 20|1@1+ (1,0) [0|1] "" Vector__XXX
 SG_ UI_enableEXVFastCalibration : 21|1@1+ (1,0) [0|1] "" Vector__XXX
 SG_ UI_enableThermalDriverlessSelfTe : 22|1@1+ (1,0) [0|1] "" Vector__XXX
 SG_ UI_enableCoolantDasTarget : 23|1@1+ (1,0) [0|1] "" Vector__XXX
 SG_ UI_geofencedLiftgateHeight : 24|8@1+ (1,0) [0|254] "cm" Vector__XXX
 SG_ UI_convenienceFeatureLimit : 32|7@1+ (1,0) [0|127] "%" Vector__XXX
 SG_ UI_allowConvenienceFeatures : 39|1@1+ (1,0) [0|1] "" Vector__XXX
 SG_ UI_enableConservativeBatteryHeat : 40|1@1+ (1,0) [0|1] "" Vector__XXX
 SG_ UI_enableDefaultApTempTarget : 41|1@1+ (1,0) [0|1] "" Vector__XXX
 SG_ UI_enableHVACCompressorWasteHeat : 42|1@1+ (1,0) [0|1] "" Vector__XXX
 SG_ UI_disablePhoneChargingPads : 43|1@1+ (1,0) [0|1] "" Vector__XXX
 SG_ UI_isAtTeslaFacility : 45|1@1+ (1,0) [0|1] "" Vector__XXX
 SG_ UI_enableThermalPowerBudget : 46|1@1+ (1,0) [0|1] "" Vector__XXX
 SG_ UI_enableHVACAPFanHeaterControl : 48|1@1+ (1,0) [0|1] "" Vector__XXX
 SG_ UI_enableAutopilotAirPurge : 49|1@1+ (1,0) [0|1] "" Vector__XXX
 SG_ UI_enableForcedAirCameraHeater : 50|1@1+ (1,0) [0|1] "" Vector__XXX
 SG_ UI_enableHvacCOPOnUndeliveredVeh : 51|1@1+ (1,0) [0|1] "" Vector__XXX

BO_ 644 UI_vehicleModes: 8 UI
 SG_ UI_factoryMode : 0|1@1+ (1,0) [0|1] "" Vector__XXX
 SG_ UI_transportMode : 1|1@1+ (1,0) [0|1] "" Vector__XXX
 SG_ UI_showroomMode : 2|1@1+ (1,0) [0|1] "" Vector__XXX
 SG_ UI_serviceMode : 3|1@1+ (1,0) [0|1] "" Vector__XXX
 SG_ UI_isDelivered : 4|1@1+ (1,0) [0|1] "" Vector__XXX
 SG_ UI_hasEverBeenDelivered : 5|1@1+ (1,0) [0|1] "" Vector__XXX
 SG_ UI_homelinkV2Command0 : 8|8@1+ (1,0) [0|255] "" Vector__XXX
 SG_ UI_homelinkV2Command1 : 16|8@1+ (1,0) [0|255] "" Vector__XXX
 SG_ UI_homelinkV2Command2 : 24|8@1+ (1,0) [0|255] "" Vector__XXX
 SG_ UI_carWashMode : 32|1@1+ (1,0) [0|1] "" Vector__XXX
 SG_ UI_valetMode : 33|1@1+ (1,0) [0|1] "" Vector__XXX
 SG_ UI_gameMode : 34|1@1+ (1,0) [0|1] "" Vector__XXX
 SG_ UI_diagnosticsAllowed : 35|1@1+ (1,0) [0|1] "" Vector__XXX
 SG_ UI_serviceModePlus : 36|1@1+ (1,0) [0|1] "" Vector__XXX
 SG_ UI_premiumAmpPowerOff : 37|1@1+ (1,0) [0|1] "" Vector__XXX
 SG_ UI_signedCmdHardLocked : 38|1@1+ (1,0) [0|1] "" Vector__XXX
 SG_ UI_signedCmdServiceMode : 39|1@1+ (1,0) [0|1] "" Vector__XXX
 SG_ UI_closureEasterEggStatus : 40|2@1+ (1,0) [0|3] "" Vector__XXX
 SG_ UI_lightShowType : 42|3@1+ (1,0) [0|7] "" Vector__XXX
 SG_ UI_sohTestRequest : 45|1@1+ (1,0) [0|1] "" Vector__XXX
 SG_ UI_upkeepMode : 46|1@1+ (1,0) [0|1] "" Vector__XXX
 SG_ UI_vehicleModesCounter : 52|4@1+ (1,0) [0|15] "" Vector__XXX
 SG_ UI_vehicleModesChecksum : 56|8@1+ (1,0) [0|255] "" Vector__XXX

BO_ 595 UI_ventPanelControlRequest: 8 UI
 SG_ UI_ventPanelControlRequestIndex M : 0|1@1+ (1,0) [0|1] "" Vector__XXX
 SG_ UI_ventPanelLeftPositionX m0 : 8|8@1+ (0.5,0) [0|100] "%" Vector__XXX
 SG_ UI_ventPanelLeftPositionY m0 : 16|8@1+ (0.5,0) [0|100] "%" Vector__XXX
 SG_ UI_ventPanelLeftLateralSplit m0 : 24|8@1+ (0.5,0) [0|100] "%" Vector__XXX
 SG_ UI_ventPanelRightPositionX m0 : 32|8@1+ (0.5,0) [0|100] "%" Vector__XXX
 SG_ UI_ventPanelRightPositionY m0 : 40|8@1+ (0.5,0) [0|100] "%" Vector__XXX
 SG_ UI_ventPanelRightLateralSplit m0 : 48|8@1+ (0.5,0) [0|100] "%" Vector__XXX
 SG_ UI_ventPanelLeftLateralMode m0 : 56|2@1+ (1,0) [0|3] "" Vector__XXX
 SG_ UI_ventPanelRightLateralMode m0 : 58|2@1+ (1,0) [0|3] "" Vector__XXX
 SG_ UI_hvacReqActiveVents m0 : 60|2@1+ (1,0) [0|3] "" Vector__XXX
 SG_ UI_vent2RLeftPositionX m1 : 8|8@1+ (0.5,0) [0|100] "%" Vector__XXX
 SG_ UI_vent2RLeftPositionY m1 : 16|8@1+ (0.5,0) [0|100] "%" Vector__XXX
 SG_ UI_vent2RRightPositionX m1 : 24|8@1+ (0.5,0) [0|100] "%" Vector__XXX
 SG_ UI_vent2RRightPositionY m1 : 32|8@1+ (0.5,0) [0|100] "%" Vector__XXX
 SG_ UI_hvacReqThirdRowState m1 : 40|2@1+ (1,0) [0|3] "" Vector__XXX

BO_ 1569 UI_weatherDataService: 8 UI
 SG_ UI_weatherSvcTimeSinceLast : 0|7@1+ (1,0) [0|126] "minutes" Vector__XXX
 SG_ UI_weatherSvcWindDir : 8|8@1+ (1.5,0) [0|381] "deg" Vector__XXX
 SG_ UI_weatherSvcTemperature : 16|8@1+ (0.5,-40) [-40|87] "degC" Vector__XXX
 SG_ UI_weatherSvcHumidity : 24|6@1+ (1.62,0) [0|100.44] "%" Vector__XXX
 SG_ UI_weatherSvcDewPoint : 32|8@1+ (0.5,-60) [-60|67] "degC" Vector__XXX
 SG_ UI_weatherSvcCloudCover : 40|6@1+ (1.62,0) [0|100.44] "%" Vector__XXX
 SG_ UI_weatherSvcPrecipProb : 48|6@1+ (1.62,0) [0|100.44] "%" Vector__XXX
 SG_ UI_weatherSvcRaining : 56|1@1+ (1,0) [0|1] "" Vector__XXX
 SG_ UI_weatherSvcSnowing : 57|1@1+ (1,0) [0|1] "" Vector__XXX
 SG_ UI_weatherSvcWindSpeed : 58|6@1+ (2,0) [0|124] "kph" Vector__XXX

BO_ 1969 UI_weatherDataServiceForecast: 8 UI
 SG_ UI_weatherSvcForecastMuxIndex M : 0|3@1+ (1,0) [0|7] "" Vector__XXX
 SG_ UI_weatherSvcForecastTempC_hour1 m0 : 8|8@1+ (0.5,-40) [-40|87] "C" Vector__XXX
 SG_ UI_weatherSvcForecastTempC_hour2 m0 : 16|8@1+ (0.5,-40) [-40|87] "C" Vector__XXX
 SG_ UI_weatherSvcForecastTempC_hour3 m0 : 24|8@1+ (0.5,-40) [-40|87] "C" Vector__XXX
 SG_ UI_weatherSvcForecastTempC_hour4 m0 : 32|8@1+ (0.5,-40) [-40|87] "C" Vector__XXX
 SG_ UI_weatherSvcForecastTempC_hour5 m0 : 40|8@1+ (0.5,-40) [-40|87] "C" Vector__XXX
 SG_ UI_weatherSvcForecastTempC_hour6 m0 : 48|8@1+ (0.5,-40) [-40|87] "C" Vector__XXX
 SG_ UI_weatherSvcForecastTempC_hour7 m0 : 56|8@1+ (0.5,-40) [-40|87] "C" Vector__XXX
 SG_ UI_weatherSvcForecastTempC_hour8 m1 : 8|8@1+ (0.5,-40) [-40|87] "C" Vector__XXX
 SG_ UI_weatherSvcForecastTempC_hour9 m1 : 16|8@1+ (0.5,-40) [-40|87] "C" Vector__XXX
 SG_ UI_weatherSvcForecastTempC__0001 m1 : 24|8@1+ (0.5,-40) [-40|87] "C" Vector__XXX
 SG_ UI_weatherSvcForecastTempC__0002 m1 : 32|8@1+ (0.5,-40) [-40|87] "C" Vector__XXX
 SG_ UI_weatherSvcForecastHumidity_ho m1 : 40|6@1+ (1.62,0) [0|100.44] "%" Vector__XXX
 SG_ UI_weatherSvcForecastHumidi_0003 m1 : 48|6@1+ (1.62,0) [0|100.44] "%" Vector__XXX
 SG_ UI_weatherSvcForecastHumidi_0004 m1 : 56|6@1+ (1.62,0) [0|100.44] "%" Vector__XXX
 SG_ UI_weatherSvcForecastHumidi_0005 m2 : 8|6@1+ (1.62,0) [0|100.44] "%" Vector__XXX
 SG_ UI_weatherSvcForecastHumidi_0006 m2 : 16|6@1+ (1.62,0) [0|100.44] "%" Vector__XXX
 SG_ UI_weatherSvcForecastHumidi_0007 m2 : 24|6@1+ (1.62,0) [0|100.44] "%" Vector__XXX
 SG_ UI_weatherSvcForecastHumidi_0008 m2 : 32|6@1+ (1.62,0) [0|100.44] "%" Vector__XXX
 SG_ UI_weatherSvcForecastHumidi_0009 m2 : 40|6@1+ (1.62,0) [0|100.44] "%" Vector__XXX
 SG_ UI_weatherSvcForecastHumidi_0010 m2 : 48|6@1+ (1.62,0) [0|100.44] "%" Vector__XXX
 SG_ UI_weatherSvcForecastHumidi_0001 m2 : 56|6@1+ (1.62,0) [0|100.44] "%" Vector__XXX
 SG_ UI_weatherSvcForecastHumidi_0002 m3 : 8|6@1+ (1.62,0) [0|100.44] "%" Vector__XXX
 SG_ UI_weatherSvcForecastWindSpeedKp m3 : 16|6@1+ (2,0) [0|124] "kph" Vector__XXX
 SG_ UI_weatherSvcForecastWindSp_0003 m3 : 24|6@1+ (2,0) [0|124] "kph" Vector__XXX
 SG_ UI_weatherSvcForecastWindSp_0004 m3 : 32|6@1+ (2,0) [0|124] "kph" Vector__XXX
 SG_ UI_weatherSvcForecastWindSp_0005 m3 : 40|6@1+ (2,0) [0|124] "kph" Vector__XXX
 SG_ UI_weatherSvcForecastWindSp_0006 m3 : 48|6@1+ (2,0) [0|124] "kph" Vector__XXX
 SG_ UI_weatherSvcForecastWindSp_0007 m3 : 56|6@1+ (2,0) [0|124] "kph" Vector__XXX
 SG_ UI_weatherSvcForecastWindSp_0008 m4 : 8|6@1+ (2,0) [0|124] "kph" Vector__XXX
 SG_ UI_weatherSvcForecastWindSp_0009 m4 : 16|6@1+ (2,0) [0|124] "kph" Vector__XXX
 SG_ UI_weatherSvcForecastWindSp_0010 m4 : 24|6@1+ (2,0) [0|124] "kph" Vector__XXX
 SG_ UI_weatherSvcForecastWindSp_0001 m4 : 32|6@1+ (2,0) [0|124] "kph" Vector__XXX
 SG_ UI_weatherSvcForecastWindSp_0002 m4 : 40|6@1+ (2,0) [0|124] "kph" Vector__XXX

BO_ 1533 UMC_alertLog: 8 UMC
 SG_ UMC_alertID M : 0|15@1+ (1,0) [0|32767] "" Vector__XXX
 SG_ UMC_alertType : 15|1@1+ (1,0) [0|1] "" Vector__XXX
 SG_ UMC_a001_groundImpedance m1 : 32|32@1+ (1,0) [0|4294967295] "Ohm" Vector__XXX
 SG_ UMC_a002_ccidRmsCurrent m2 : 16|12@1+ (0.001,0) [0|4.095] "A" Vector__XXX
 SG_ UMC_a002_ccidRmsCurrentAvg m2 : 28|12@1+ (0.001,0) [0|4.095] "A" Vector__XXX
 SG_ UMC_a002_ccidDCGfciCurrent m2 : 40|10@1- (0.001,0) [-0.512|0.511] "A" Vector__XXX
 SG_ UMC_a002_ccidFaultReason m2 : 50|4@1+ (1,0) [1|15] "" Vector__XXX
 SG_ UMC_a002_ccidFaultBucket m2 : 54|4@1+ (1,0) [0|15] "" Vector__XXX
 SG_ UMC_a003_faultType m3 : 16|8@1+ (1,0) [0|255] "" Vector__XXX
 SG_ UMC_a003_ccidSelfTestDuty m3 : 24|16@1+ (0.0001,50) [50|56.5535] "A" Vector__XXX
 SG_ UMC_a003_ccidSelfTestCurrent m3 : 40|16@1+ (0.0001,0) [0|6.5535] "A" Vector__XXX
 SG_ UMC_a004_lineVoltage m4 : 16|16@1+ (1,0) [0|65535] "Vrms" Vector__XXX
 SG_ UMC_a004_inputVoltage m4 : 32|16@1+ (0.01,0) [0|655.35] "V" Vector__XXX
 SG_ UMC_a004_inputNeutralVoltage m4 : 48|16@1+ (0.01,0) [0|655.35] "V" Vector__XXX
 SG_ UMC_a005_lineVoltage m5 : 16|16@1+ (1,0) [0|65535] "Vrms" Vector__XXX
 SG_ UMC_a005_inputVoltage m5 : 32|16@1+ (0.01,0) [0|655.35] "V" Vector__XXX
 SG_ UMC_a005_inputNeutralVoltage m5 : 48|16@1+ (0.01,0) [0|655.35] "V" Vector__XXX
 SG_ UMC_a006_outputVoltage m6 : 16|16@1+ (1,0) [0|65535] "Vrms" Vector__XXX
 SG_ UMC_a006_faultType m6 : 32|4@1+ (1,0) [0|15] "" Vector__XXX
 SG_ UMC_a006_umcReceptacleVoltage m6 : 36|12@1+ (0.1,0) [0|409.5] "V" Vector__XXX
 SG_ UMC_a006_handleVoltage m6 : 48|12@1+ (0.1,0) [0|409.5] "V" Vector__XXX
 SG_ UMC_a006_line1StuckClosed m6 : 60|1@1+ (1,0) [0|1] "" Vector__XXX
 SG_ UMC_a006_line2StuckClosed m6 : 61|1@1+ (1,0) [0|1] "" Vector__XXX
 SG_ UMC_a007_pcbaTemp m7 : 16|16@1+ (1,0) [0|65535] "degC" Vector__XXX
 SG_ UMC_a008_wallPlugTemp m8 : 16|16@1+ (1,0) [0|65535] "degC" Vector__XXX
 SG_ UMC_a008_SA_region m8 : 32|4@1+ (1,0) [0|15] "" Vector__XXX
 SG_ UMC_a008_SA_current m8 : 40|8@1+ (1,0) [0|255] "A" Vector__XXX
 SG_ UMC_a009_vehConnTemp m9 : 16|16@1+ (1,0) [0|65535] "degC" Vector__XXX
 SG_ UMC_a010_inputTerminalsTemp m10 : 16|16@1+ (1,0) [0|65535] "degC" Vector__XXX
 SG_ UMC_a012_pilotHigh m12 : 16|12@1- (0.01,0) [-20.48|20.47] "V" Vector__XXX
 SG_ UMC_a012_pilotLow m12 : 28|12@1- (0.01,0) [-20.48|20.47] "V" Vector__XXX
 SG_ UMC_a013_SA_region m13 : 16|4@1+ (1,0) [0|15] "" Vector__XXX
 SG_ UMC_a013_SA_current m13 : 24|8@1+ (1,0) [0|255] "A" Vector__XXX
 SG_ UMC_a015_SA_region m15 : 16|4@1+ (1,0) [0|15] "" Vector__XXX
 SG_ UMC_a015_SA_current m15 : 24|8@1+ (1,0) [0|255] "A" Vector__XXX
 SG_ UMC_a016_pcbaTemp m16 : 16|16@1+ (1,0) [0|65535] "degC" Vector__XXX
 SG_ UMC_a017_wallPlugTemp m17 : 16|16@1+ (1,0) [0|65535] "degC" Vector__XXX
 SG_ UMC_a017_SA_region m17 : 32|4@1+ (1,0) [0|15] "" Vector__XXX
 SG_ UMC_a017_SA_current m17 : 40|8@1+ (1,0) [0|255] "A" Vector__XXX
 SG_ UMC_a018_vehConnTemp m18 : 16|16@1+ (1,0) [0|65535] "degC" Vector__XXX
 SG_ UMC_a019_inputTerminalsTemp m19 : 16|16@1+ (1,0) [0|65535] "degC" Vector__XXX
 SG_ UMC_a024_groundImpedance m24 : 32|32@1+ (1,0) [0|4294967295] "Ohm" Vector__XXX
 SG_ UMC_a040_groundImpedance m40 : 32|32@1+ (1,0) [0|4294967295] "Ohm" Vector__XXX

BO_ 824 UMC_alertMatrix1: 8 UMC
 SG_ UMC_a001_gndMonIntrptLineSide : 0|1@1+ (1,0) [0|1] "" Vector__XXX
 SG_ UMC_a002_GFCITripped : 1|1@1+ (1,0) [0|1] "" Vector__XXX
 SG_ UMC_a003_GFCISelfTestFault : 2|1@1+ (1,0) [0|1] "" Vector__XXX
 SG_ UMC_a004_inputOverVoltage : 3|1@1+ (1,0) [0|1] "" Vector__XXX
 SG_ UMC_a005_inputUnderVoltage : 4|1@1+ (1,0) [0|1] "" Vector__XXX
 SG_ UMC_a006_contactorWelded : 5|1@1+ (1,0) [0|1] "" Vector__XXX
 SG_ UMC_a007_pcbaOT : 6|1@1+ (1,0) [0|1] "" Vector__XXX
 SG_ UMC_a008_wallPlugOT : 7|1@1+ (1,0) [0|1] "" Vector__XXX
 SG_ UMC_a009_vehConnOT : 8|1@1+ (1,0) [0|1] "" Vector__XXX
 SG_ UMC_a010_inputOT : 9|1@1+ (1,0) [0|1] "" Vector__XXX
 SG_ UMC_a011_proxDisconnected : 10|1@1+ (1,0) [0|1] "" Vector__XXX
 SG_ UMC_a012_pilotFault : 11|1@1+ (1,0) [0|1] "" Vector__XXX
 SG_ UMC_a013_SA_Temperature : 12|1@1+ (1,0) [0|1] "" Vector__XXX
 SG_ UMC_a014_SA_Genealogy : 13|1@1+ (1,0) [0|1] "" Vector__XXX
 SG_ UMC_a015_SA_Connection : 14|1@1+ (1,0) [0|1] "" Vector__XXX
 SG_ UMC_a016_pcbaOTFoldback : 15|1@1+ (1,0) [0|1] "" Vector__XXX
 SG_ UMC_a017_wallPlugOTFoldback : 16|1@1+ (1,0) [0|1] "" Vector__XXX
 SG_ UMC_a018_vehConnOTFoldback : 17|1@1+ (1,0) [0|1] "" Vector__XXX
 SG_ UMC_a019_inputOTFoldback : 18|1@1+ (1,0) [0|1] "" Vector__XXX
 SG_ UMC_a020_applicationCRC : 19|1@1+ (1,0) [0|1] "" Vector__XXX
 SG_ UMC_a021_dataBus : 20|1@1+ (1,0) [0|1] "" Vector__XXX
 SG_ UMC_a022_criticalRAM : 21|1@1+ (1,0) [0|1] "" Vector__XXX
 SG_ UMC_a023_adcSelfTest : 22|1@1+ (1,0) [0|1] "" Vector__XXX
 SG_ UMC_a024_gndResistanceHigh : 23|1@1+ (1,0) [0|1] "" Vector__XXX
 SG_ UMC_a025_cntrOpenExpectedClose : 24|1@1+ (1,0) [0|1] "" Vector__XXX
 SG_ UMC_a026_vRefOutOfRange : 25|1@1+ (1,0) [0|1] "" Vector__XXX
 SG_ UMC_a027_watchdogExpired : 26|1@1+ (1,0) [0|1] "" Vector__XXX
 SG_ UMC_a028_processorBooted : 27|1@1+ (1,0) [0|1] "" Vector__XXX
 SG_ UMC_a029_acPowerLoss : 28|1@1+ (1,0) [0|1] "" Vector__XXX
 SG_ UMC_a030_acLostPllLock : 29|1@1+ (1,0) [0|1] "" Vector__XXX
 SG_ UMC_a031_relayCoilVIrrational : 30|1@1+ (1,0) [0|1] "" Vector__XXX
 SG_ UMC_a032_chcVitalsRequestFailure : 31|1@1+ (1,0) [0|1] "" Vector__XXX
 SG_ UMC_a033_chcUpdateFault : 32|1@1+ (1,0) [0|1] "" Vector__XXX
 SG_ UMC_a034_v2lSAUnsupported : 33|1@1+ (1,0) [0|1] "" Vector__XXX
 SG_ UMC_a035_v2lHVACDetected : 34|1@1+ (1,0) [0|1] "" Vector__XXX
 SG_ UMC_a037_GFCICalibration : 36|1@1+ (1,0) [0|1] "" Vector__XXX
 SG_ UMC_a038_chcVitalsFault : 37|1@1+ (1,0) [0|1] "" Vector__XXX
 SG_ UMC_a039_inputOverCurrent : 38|1@1+ (1,0) [0|1] "" Vector__XXX
 SG_ UMC_a040_gndDisconnected : 39|1@1+ (1,0) [0|1] "" Vector__XXX
 SG_ UMC_a041_handleTempIrrational : 40|1@1+ (1,0) [0|1] "" Vector__XXX
 SG_ UMC_a042_GFCICalRelayDelta : 41|1@1+ (1,0) [0|1] "" Vector__XXX

BO_ 1285 UMC_smartAdapterInfo: 8 UMC
 SG_ SA_infoIndex M : 0|8@1+ (1,0) [0|255] "" Vector__XXX
 SG_ SA_genealogyVersion m0 : 8|8@1+ (1,0) [0|255] "" Vector__XXX
 SG_ SA_genealogyCrc m0 : 16|32@1+ (1,0) [0|4294967295] "" Vector__XXX
 SG_ SA_region m0 : 48|4@1+ (1,0) [0|15] "" Vector__XXX
 SG_ SA_OverTempThreshold m0 : 56|8@1+ (1,0) [0|255] "" Vector__XXX
 SG_ SA_partNumInt m31 : 8|32@1+ (1,0) [0|4294967295] "" Vector__XXX
 SG_ SA_partNumRev m31 : 40|8@1+ (1,0) [0|255] "" Vector__XXX
 SG_ SA_currentLimit m31 : 48|8@1+ (1,0) [0|255] "" Vector__XXX
 SG_ SA_l1Voltage m31 : 56|8@1+ (1,0) [0|255] "" Vector__XXX

BO_TX_BU_ 666 : UI;
BO_TX_BU_ 723 : UI;
BO_TX_BU_ 563 : UI;
BO_TX_BU_ 851 : UI;
BO_TX_BU_ 991 : UI;
BO_TX_BU_ 986 : UI;
BO_TX_BU_ 988 : UI;
BO_TX_BU_ 663 : UI;
BO_TX_BU_ 661 : UI;
BO_TX_BU_ 1064 : UI;
BO_TX_BU_ 856 : UI;
BO_TX_BU_ 952 : UI;
BO_TX_BU_ 787 : UI;
BO_TX_BU_ 1263 : UI;
BO_TX_BU_ 130 : UI;
BO_TX_BU_ 139 : UI;
BO_TX_BU_ 1173 : UI;
BO_TX_BU_ 1174 : UI;
BO_TX_BU_ 1175 : UI;
BO_TX_BU_ 850 : UI;
BO_TX_BU_ 1827 : UI;
BO_TX_BU_ 1829 : UI;
BO_TX_BU_ 627 : UI;
BO_TX_BU_ 947 : UI;
BO_TX_BU_ 628 : UI;
BO_TX_BU_ 1193 : UI;
BO_TX_BU_ 853 : UI;
BO_TX_BU_ 644 : UI;
BO_TX_BU_ 595 : UI;
BO_TX_BU_ 1569 : UI;
BO_TX_BU_ 1969 : UI;
BO_TX_BU_ 1533 : UMC;
BO_TX_BU_ 824 : UMC;
BO_TX_BU_ 1285 : UMC;
CM_ BO_ 666 "Touchscreen user interface computer message: seat control";
CM_ SG_ 666 UI_seatControlIndex "Touchscreen user interface computer: seat control index";
CM_ SG_ 666 UI_3RSeatChildLock "Reports the state of 3rd row seat fold flat child lock from the UI";
CM_ SG_ 666 UI_2RowLeftSeatTrackBack "Touchscreen user interface computer: 2 row left seat track back";
CM_ SG_ 666 UI_2RowLeftSeatTrackForward "Touchscreen user interface computer: 2 row left seat track forward";
CM_ SG_ 666 UI_2RowRightSeatTrackBack "Touchscreen user interface computer: 2 row right seat track back";
CM_ SG_ 666 UI_2RowRightSeatTrackForward "Touchscreen user interface computer: 2 row right seat track forward";
CM_ SG_ 666 UI_left3RowSeatAdjustmentRequest "Reports request from the touchscreen User Interface (UI) to actuate the left third row seat.";
CM_ SG_ 666 UI_right3RowSeatAdjustmentReques "Reports request from the touchscreen User Interface (UI) to actuate the right third row seat.";
CM_ SG_ 666 UI_2RLeftSeatFanReq "Request for second row left seat ventilation";
CM_ SG_ 666 UI_2RRightSeatFanReq "Request for second row right seat ventilation";
CM_ SG_ 666 UI_leftThirdRowSeatRequestFromRe "Touchscreen user interface computer: left third row seat request from rear display";
CM_ SG_ 666 UI_rightThirdRowSeatRequestFromR "Touchscreen user interface computer: right third row seat request from rear display";
CM_ SG_ 666 UI_seatChoreographyStopRequest "Reports if the UI requests to stop the seat choreography";
CM_ BO_ 723 "Touchscreen user interface computer message: solar data";
CM_ SG_ 723 UI_solarAzimuthAngle "Touchscreen user interface computer: solar azimuth angle; raw 32768 = signal not available (SNA)";
CM_ SG_ 723 UI_solarAzimuthAngleCarRef "Touchscreen user interface computer: solar azimuth angle car ref; raw 255 = signal not available (SNA)";
CM_ SG_ 723 UI_isSunUp "is sun up; raw 3 = signal not available (SNA)";
CM_ SG_ 723 UI_solarElevationAngle "Solar Elevation Angle; raw 127 = signal not available (SNA)";
CM_ SG_ 723 UI_screenPCBTemperature "Temperature of display PCB";
CM_ SG_ 723 UI_minsToSunset "time until to sunset";
CM_ SG_ 723 UI_minsToSunrise "time until to sunrise";
CM_ BO_ 563 "Touchscreen user interface computer message: stalkless control";
CM_ SG_ 563 UI_stalklessControlCounter "Touchscreen user interface computer: stalkless control counter";
CM_ SG_ 563 UI_stalklessControlChecksum "Touchscreen user interface computer: stalkless control checksum";
CM_ SG_ 563 UI_gearStripSuppressCounter "Touchscreen user interface computer: gear strip suppress counter";
CM_ SG_ 563 UI_gearRequest "UI gear request from UI; raw 0 = signal not available (SNA)";
CM_ SG_ 563 UI_autopilotRequest "Touchscreen user interface computer: autopilot request";
CM_ SG_ 563 UI_gearStripShowing "UI communicating to GTW that the gear strip is visible on the screen as part of a handshake";
CM_ SG_ 563 UI_gearStripLocation "Touchscreen user interface computer: gear strip location";
CM_ SG_ 563 UI_parkButtonShowing "Touchscreen user interface computer: park button showing";
CM_ SG_ 563 UI_neutralButtonShowing "Touchscreen user interface computer: neutral button showing";
CM_ SG_ 563 UI_gearStripForceShow "UI request to GTW to show the gear strip";
CM_ SG_ 563 UI_neutralButtonDrawerForceShow "Touchscreen user interface computer: neutral button drawer force show";
CM_ SG_ 563 UI_autoParkAvailable "UI communicating to GTW that the autpark functionality is available";
CM_ SG_ 563 UI_autoParkShowing "Touchscreen user interface computer: auto park showing";
CM_ SG_ 563 UI_gearStripSuppressActive "UI communicating to GTW that the gear strip should not be shown";
CM_ SG_ 563 UI_gearNeutralPressed "Neutral button is being pressed";
CM_ BO_ 851 "Touchscreen user interface computer message: status";
CM_ SG_ 851 UI_touchActive "No touchscreen errors";
CM_ SG_ 851 UI_audioActive "Audio system is ready.";
CM_ SG_ 851 UI_bluetoothActive "Touchscreen user interface computer: bluetooth active";
CM_ SG_ 851 UI_cellActive "Cell is powered";
CM_ SG_ 851 UI_displayReady "UI is ready (GUI_allReady) and display is ok (GUI_displayHardwareOK)";
CM_ SG_ 851 UI_displayOn "UI display on/off status";
CM_ SG_ 851 UI_wifiActive "WiFi active.";
CM_ SG_ 851 UI_wifiConnected "WiFi Connected.";
CM_ SG_ 851 UI_systemActive "Touchscreen user interface computer: system active";
CM_ SG_ 851 UI_readyForDrive "Ready for drive (UI ready or self park request)";
CM_ SG_ 851 UI_cellConnected "Detects if the cell is connected to a network.";
CM_ SG_ 851 UI_vpnActive "VPN connected.";
CM_ SG_ 851 UI_autopilotTrial "Touchscreen user interface computer: autopilot trial";
CM_ SG_ 851 UI_factoryReset "UI request for factory reset; raw 0 = signal not available (SNA)";
CM_ SG_ 851 UI_gpsActive "GPS has valid fix";
CM_ SG_ 851 UI_screenshotActive "Touchscreen user interface computer: screenshot active";
CM_ SG_ 851 UI_radioActive "Touchscreen user interface computer: radio active";
CM_ SG_ 851 UI_cellNetworkTechnology "Describes the type of cellular network to which the car computer is connected: GPRS_2G(114Kbps) < EGDE_2G(368Kbps) < 3G(3Mbps) < HSDPA_3G(14Mbps) < HSPAplus_4Gg(168Mbps) < 4G_LTE(299Mbps); raw 15 = signal not available (SNA)";
CM_ SG_ 851 UI_cellReceiverPower "Touchscreen user interface computer: cell receiver power";
CM_ SG_ 851 UI_falseTouchCounter "Count false touches after display is off.";
CM_ SG_ 851 UI_developmentCar "Touchscreen user interface computer: development car";
CM_ SG_ 851 UI_cameraActive "Touchscreen user interface computer: camera active";
CM_ SG_ 851 UI_cellSignalBars "Number of cellular signal bars displayed on the UI, derived from cellSignalStrength; raw 7 = signal not available (SNA)";
CM_ SG_ 851 UI_trailerModeTelltale "Color of the trailer mode telltale";
CM_ SG_ 851 UI_pcbTemperature "PCB digital temp sensor reading in DegC";
CM_ SG_ 851 UI_cpuTemperature "Apollo Lake SOC temperature in DegC";
CM_ BO_ 991 "Touchscreen user interface computer message: status2";
CM_ SG_ 991 UI_mobileAppStepCount "Touchscreen user interface computer: mobile app step count";
CM_ SG_ 991 UI_userRequestSnapshot "Touchscreen user interface computer: user request snapshot";
CM_ SG_ 991 UI_touchDetected "Touchscreen user interface computer: touch detected";
CM_ SG_ 991 UI_validDeviceForEUSummon "Touchscreen user interface computer: valid device for EU summon";
CM_ SG_ 991 UI_locatedAtHome "Touchscreen user interface computer: located at home";
CM_ SG_ 991 UI_locatedAtWork "Touchscreen user interface computer: located at work";
CM_ SG_ 991 UI_locatedAtFavorite "Touchscreen user interface computer: located at favorite";
CM_ SG_ 991 UI_displayInDarkMode "Touchscreen user interface computer: display in dark mode";
CM_ SG_ 991 UI_userActivity "Indicates user interaction with the center display";
CM_ SG_ 991 UI_activeTouchPoints "Quantity of active touch points on the Center Display";
CM_ SG_ 991 UI_linkState "Connectivity link state";
CM_ SG_ 991 UI_sentryModeState "Touchscreen user interface computer: sentry mode state; raw 6 = signal not available (SNA)";
CM_ SG_ 991 UI_autopilotSentryRequest "whether AP sentry mode should be enabled";
CM_ SG_ 991 UI_mobileAppConnected "Reports if Web Real-Time Communication (WebRTC) connection is connected while summon screen is open on the mobile app.";
CM_ SG_ 991 UI_phoneLeftInCabin "Used for monitoring phone left behind feature";
CM_ SG_ 991 UI_autoshiftDRState "Reports the User Interface (UI) autoshift Drive/Reverse state.";
CM_ SG_ 991 UI_wifiBtModuleType "Reports the type of Wi-Fi and Bluetooth (BT) module.";
CM_ SG_ 991 UI_sohHealthStatus "Touchscreen user interface computer: soh health status";
CM_ SG_ 991 UI_selfParkState "Reports the auto park state changes; raw 255 = signal not available (SNA)";
CM_ SG_ 991 UI_summonDeviceIndex "Reports which device is being used to control summon.";
CM_ SG_ 991 UI_fullScreenMode "Aggregates all situations with which the UI is using the entire screen so stalkless gear controls are not present";
CM_ SG_ 991 UI_sentryModeCameraDetection "Touchscreen user interface computer: sentry mode camera detection";
CM_ SG_ 991 UI_wakeOnIPActive "Touchscreen user interface computer: wake on IP active";
CM_ SG_ 991 UI_sapActive "Touchscreen user interface computer: sap active";
CM_ SG_ 991 UI_sapClients "Touchscreen user interface computer: sap clients";
CM_ SG_ 991 UI_connectivityStandbyActive "Touchscreen user interface computer: connectivity standby active";
CM_ BO_ 986 "Touchscreen user interface computer message: status3";
CM_ SG_ 986 UI_wifiRegDomain "Indicates the Wi-Fi regulatory domain.";
CM_ SG_ 986 UI_wifiTethered "Monitors whether Wi-Fi is connected while driving.";
CM_ BO_ 988 "Touchscreen user interface computer message: summon goal";
CM_ SG_ 988 UI_goalLatitude "Touchscreen user interface computer: goal latitude";
CM_ SG_ 988 UI_goalLongitude "Touchscreen user interface computer: goal longitude";
CM_ SG_ 988 UI_goalOrientation "Touchscreen user interface computer: goal orientation";
CM_ BO_ 663 "Touchscreen user interface computer message: suspension control";
CM_ SG_ 663 UI_adaptiveRideRequest "UI customer adaptive ride request for air suspension.";
CM_ SG_ 663 UI_suspensionLoweringRequest "Touchscreen user interface computer: suspension lowering request; raw 3 = signal not available (SNA)";
CM_ SG_ 663 UI_geofenceLevelingRequest "Geofence level request from customer; raw 5 = signal not available (SNA)";
CM_ SG_ 663 UI_jackModeToggleRequest "Touchscreen user interface computer: jack mode toggle request";
CM_ SG_ 663 UI_adaptiveTuningRequest0 "Touchscreen user interface computer: adaptive tuning request0";
CM_ SG_ 663 UI_adaptiveTuningRequest1 "Touchscreen user interface computer: adaptive tuning request1";
CM_ SG_ 663 UI_roadRoughnessLookahead "Touchscreen user interface computer: road roughness lookahead; raw 127 = signal not available (SNA)";
CM_ SG_ 663 UI_roadRoughnessStart "Touchscreen user interface computer: road roughness start; raw 31 = signal not available (SNA)";
CM_ SG_ 663 UI_mapVersionUsed "Touchscreen user interface computer: map version used; raw 255 = signal not available (SNA)";
CM_ SG_ 663 UI_suspensionControlCounter "Touchscreen user interface computer: suspension control counter";
CM_ SG_ 663 UI_suspensionLevelRequest "Touchscreen user interface computer: suspension level request";
CM_ SG_ 663 UI_suspensionControlChecksum "Touchscreen user interface computer: suspension control checksum";
CM_ BO_ 661 "Touchscreen user interface computer message: system monitor";
CM_ SG_ 661 UI_systemMonitorIndex "Touchscreen user interface computer: system monitor index";
CM_ SG_ 661 UI_SystemMemUsage "Monitors system memory usage";
CM_ SG_ 661 UI_QtCarMemUsage "Monitors memory usage of the primary User Interface application";
CM_ SG_ 661 UI_QtCarCPUUsage "Monitors CPU usage of the primary User Interface application";
CM_ SG_ 661 UI_emmcStatus "Touchscreen user interface computer: emmc status";
CM_ SG_ 661 UI_SystemCPUUsage "Monitors system CPU usage";
CM_ SG_ 661 UI_HomeHealth "Touchscreen user interface computer: home health";
CM_ SG_ 661 UI_VarHealth "Touchscreen user interface computer: var health";
CM_ SG_ 661 UI_LogHealth "Touchscreen user interface computer: log health";
CM_ SG_ 661 UI_TmpfsHealth "Touchscreen user interface computer: tmpfs health";
CM_ SG_ 661 UI_emmcDataWritten "Touchscreen user interface computer: emmc data written";
CM_ SG_ 661 UI_emmcTotalErases "Touchscreen user interface computer: emmc total erases";
CM_ BO_ 1064 "Touchscreen user interface computer message: telemetry control";
CM_ SG_ 1064 UI_TCR_enable "Touchscreen user interface computer: TCR enable";
CM_ SG_ 1064 UI_TCR_moveStateStanding "Touchscreen user interface computer: TCR move state standing";
CM_ SG_ 1064 UI_TCR_moveStateStopped "Touchscreen user interface computer: TCR move state stopped";
CM_ SG_ 1064 UI_TCR_moveStateMoving "Touchscreen user interface computer: TCR move state moving";
CM_ SG_ 1064 UI_TCR_moveStateIndeterm "Touchscreen user interface computer: TCR move state indeterm";
CM_ SG_ 1064 UI_TCR_classConstElem "Touchscreen user interface computer: TCR class const elem";
CM_ SG_ 1064 UI_TCR_classMovingPed "Touchscreen user interface computer: TCR class moving ped";
CM_ SG_ 1064 UI_TCR_classMovingTwoWheel "Touchscreen user interface computer: TCR class moving two wheel";
CM_ SG_ 1064 UI_TCR_classMovingFourWheel "Touchscreen user interface computer: TCR class moving four wheel";
CM_ SG_ 1064 UI_TCR_classUnknown "Touchscreen user interface computer: TCR class unknown";
CM_ SG_ 1064 UI_TCR_downSampleFactor "Touchscreen user interface computer: TCR down sample factor";
CM_ SG_ 1064 UI_TCR_wExist "Touchscreen user interface computer: TCR w exist";
CM_ SG_ 1064 UI_TCR_vehSpeed "Touchscreen user interface computer: TCR veh speed";
CM_ SG_ 1064 UI_TCR_minRCS "Touchscreen user interface computer: TCR min RCS";
CM_ SG_ 1064 UI_TCR_maxDy "Touchscreen user interface computer: TCR max dy";
CM_ SG_ 1064 UI_TCR_maxObjects "Touchscreen user interface computer: TCR max objects";
CM_ SG_ 1064 UI_TCR_maxRoadClass "Touchscreen user interface computer: TCR max road class";
CM_ BO_ 856 "Touchscreen user interface computer message: tpms mode";
CM_ SG_ 856 UI_TPMSMode "Touchscreen user interface computer: TPMS mode";
CM_ SG_ 856 UI_TPMSLearnIDMode "Touchscreen user interface computer: TPMS learn ID mode";
CM_ SG_ 856 UI_sizeOfWheelSelect "Touchscreen user interface computer: size of wheel select";
CM_ SG_ 856 UI_sizeOfReqCANAutoLearn "Touchscreen user interface computer: size of req CAN auto learn";
CM_ BO_ 952 "Touchscreen user interface computer message: tpms RC psetting";
CM_ SG_ 952 UI_sendCalibrateTireRequest "Reports UI requests for PMDI to start the tire pressure calibration routine.";
CM_ SG_ 952 UI_setRCPFront "Touchscreen user interface computer: set RCP front";
CM_ SG_ 952 UI_setRCPRear "Touchscreen user interface computer: set RCP rear";
CM_ BO_ 787 "Touchscreen user interface computer message: track mode settings";
CM_ SG_ 787 UI_trackModeRequest "User selected track mode";
CM_ SG_ 787 UI_trackRotationTendency "Touchscreen user interface computer: track rotation tendency";
CM_ SG_ 787 UI_trackStabilityAssist "Touchscreen user interface computer: track stability assist";
CM_ SG_ 787 UI_trackPostCooling "Touchscreen user interface computer: track post cooling";
CM_ SG_ 787 UI_trackCmpOverclock "Touchscreen user interface computer: track cmp overclock";
CM_ SG_ 787 UI_trackModeBrakeTemps "Touchscreen user interface computer: track mode brake temps";
CM_ SG_ 787 UI_trackDrivePowerAvailability "Reports power deployment strategy for Track Mode. Ranges from endurance limit to maximum power.";
CM_ SG_ 787 UI_stabilityModeRequest "Touchscreen user interface computer: stability mode request";
CM_ SG_ 787 UI_trackModeSettingsCounter "Touchscreen user interface computer: track mode settings counter";
CM_ SG_ 787 UI_trackModeSettingsChecksum "Touchscreen user interface computer: track mode settings checksum";
CM_ BO_ 1263 "Touchscreen user interface computer message: trip planner info";
CM_ SG_ 1263 UI_fwHeatOnNavArrivalSOE "Energy percentages shown in the UI";
CM_ SG_ 1263 UI_voyagerHeatOnNavArrivalSOE "Energy percentages shown in the UI";
CM_ SG_ 1263 UI_usingVoyagerPreconditioning "Touchscreen user interface computer: using voyager preconditioning";
CM_ BO_ 130 "Touchscreen user interface computer message: trip planning";
CM_ SG_ 130 UI_tripPlanningActive "Indicates that there is active route in navigation with a valid energy at destination prediction.";
CM_ SG_ 130 UI_navToSupercharger "Navigation destination is a supercharger";
CM_ SG_ 130 UI_navFastchargerType "when navigation is turned on, this enum identifies the type of fastcharger the car is navigating to based on the rated power from sc_locations";
CM_ SG_ 130 UI_battPreconditionOnNavState "Indicates to battery and thermal systems whether the battery should be actively heated, passively heated, actively cooled, or passively cooled";
CM_ SG_ 130 UI_requestActiveBatteryHeating "Flag to request BMS enable active battery heating";
CM_ SG_ 130 UI_battPreconditionOnNavPowerReq "The preconditioning power that Trip Planner is requesting from the thermal system to use for battery preconditioning (cooling or heating); raw 127 = signal not available (SNA)";
CM_ SG_ 130 UI_battPreconditionOnNavTargetT "The pack temperature that Trip Planner is targeting upon arriving to a fast charger; raw 255 = signal not available (SNA)";
CM_ SG_ 130 UI_ambientTempAtDestination "Touchscreen user interface computer: ambient temp at destination; raw 128 = signal not available (SNA)";
CM_ SG_ 130 UI_tripPlanChargingTargetPercent "Touchscreen user interface computer: trip plan charging target percent; raw 1023 = signal not available (SNA)";
CM_ SG_ 130 UI_energyAtDestination "expected energy at destination in kWh for current navigation route; raw 32768 = signal not available (SNA)";
CM_ BO_ 139 "Touchscreen user interface computer message: trip planning2";
CM_ SG_ 139 UI_maxSpeedToReachDestination "maximum speed to reach destination without significant risk of running out of energy; raw 65535 = signal not available (SNA)";
CM_ SG_ 139 UI_remainingWeightedRMSSpeed "Touchscreen user interface computer: remaining weighted RMS speed; raw 65535 = signal not available (SNA)";
CM_ SG_ 139 UI_timeToDestination "remaining time to reach destination; raw 65535 = signal not available (SNA)";
CM_ BO_ 1173 "Touchscreen user interface computer message: trip planning3";
CM_ SG_ 1173 UI_predictedEnergy "initially predicted energy in kWh for current location along navigation route; raw 32768 = signal not available (SNA)";
CM_ SG_ 1173 UI_predictedEnergyLearned "Touchscreen user interface computer: predicted energy learned; raw 32768 = signal not available (SNA)";
CM_ SG_ 1173 UI_hindsightEnergy "hindsight energy, the model predicted energy based on measured speed and acceleration for the current location along navigation route; raw 32768 = signal not available (SNA)";
CM_ SG_ 1173 UI_hindsightEnergyLearned "Touchscreen user interface computer: hindsight energy learned; raw 32768 = signal not available (SNA)";
CM_ BO_ 1174 "Touchscreen user interface computer message: trip planning4";
CM_ SG_ 1174 UI_longTermEnergyModelError "Touchscreen user interface computer: long term energy model error; raw 128 = signal not available (SNA)";
CM_ SG_ 1174 UI_longTermRmsSpeedRatio "Touchscreen user interface computer: long term rms speed ratio; raw 255 = signal not available (SNA)";
CM_ SG_ 1174 UI_gradeCorrectedEnergy "Touchscreen user interface computer: grade corrected energy; raw 32768 = signal not available (SNA)";
CM_ SG_ 1174 UI_gradeCorrectedEnergyLearned "Touchscreen user interface computer: grade corrected energy learned; raw 32768 = signal not available (SNA)";
CM_ BO_ 1175 "Touchscreen user interface computer message: trip planning5";
CM_ SG_ 1175 UI_battPreconditionOnNavTime "Touchscreen user interface computer: batt precondition on nav time; raw 65535 = signal not available (SNA)";
CM_ SG_ 1175 UI_maxBattPreconditionOnNavTime "Touchscreen user interface computer: max batt precondition on nav time; raw 65535 = signal not available (SNA)";
CM_ BO_ 850 "Touchscreen user interface computer message: ui health status";
CM_ SG_ 850 UI_centerDisplayRunning "is center display running";
CM_ SG_ 850 UI_centerDisplaySM "Touchscreen user interface computer: center display SM";
CM_ SG_ 850 UI_centerDisplayPowerOn "center display power on";
CM_ SG_ 850 UI_centerDisplayCrtcOk "Touchscreen user interface computer: center display crtc ok";
CM_ SG_ 850 UI_centerDisplayHardwareOk "Touchscreen user interface computer: center display hardware ok";
CM_ SG_ 850 UI_centerDisplayWindowManagerOk "Touchscreen user interface computer: center display window manager ok";
CM_ SG_ 850 UI_centerDisplayCompositorOk "Touchscreen user interface computer: center display compositor ok";
CM_ SG_ 850 UI_apVisualizationOk "Touchscreen user interface computer: ap visualization ok";
CM_ SG_ 850 UI_autonomyCenterDispStatus "Touchscreen user interface computer: autonomy center disp status; raw 0 = signal not available (SNA)";
CM_ SG_ 850 UI_autonomyRearDispStatus "Touchscreen user interface computer: autonomy rear disp status; raw 0 = signal not available (SNA)";
CM_ SG_ 850 UI_autonomyConnectivityStatus "Touchscreen user interface computer: autonomy connectivity status; raw 0 = signal not available (SNA)";
CM_ SG_ 850 UI_autonomyConnectivtyHWOk "Touchscreen user interface computer: autonomy connectivty HW ok";
CM_ SG_ 850 UI_autonomyQtCarStatus "Signal reported by Touchscreen user interface computer; raw 0 = signal not available (SNA)";
CM_ SG_ 850 UI_autonomyQtCarRearStatus "Signal reported by Touchscreen user interface computer; raw 0 = signal not available (SNA)";
CM_ SG_ 850 UI_autonomyDASServerStatus "Touchscreen user interface computer: autonomy DAS server status; raw 0 = signal not available (SNA)";
CM_ SG_ 850 UI_rearDisplayRunning "is rear display running";
CM_ SG_ 850 UI_rearDisplayPowerOn "rear display power on";
CM_ SG_ 850 UI_rearDisplaySM "Touchscreen user interface computer: rear display SM";
CM_ SG_ 850 UI_rearDisplayCrtcOk "Touchscreen user interface computer: rear display crtc ok";
CM_ SG_ 850 UI_rearDisplayHardwareOk "Touchscreen user interface computer: rear display hardware ok";
CM_ SG_ 850 UI_rearDisplayWindowManagerOk "Touchscreen user interface computer: rear display window manager ok";
CM_ SG_ 850 UI_rearDisplayCompositorOk "Touchscreen user interface computer: rear display compositor ok";
CM_ BO_ 1827 "Touchscreen user interface computer message: uss thresholds x";
CM_ SG_ 1827 UI_ussSensorIdX "Touchscreen user interface computer: uss sensor id x";
CM_ SG_ 1827 UI_ussThresholdX0 "Touchscreen user interface computer: uss threshold X0";
CM_ SG_ 1827 UI_ussThresholdX1 "Touchscreen user interface computer: uss threshold X1";
CM_ SG_ 1827 UI_ussThresholdX2 "Touchscreen user interface computer: uss threshold X2";
CM_ SG_ 1827 UI_ussThresholdX3 "Touchscreen user interface computer: uss threshold X3";
CM_ SG_ 1827 UI_ussThresholdX4 "Touchscreen user interface computer: uss threshold X4";
CM_ SG_ 1827 UI_ussThresholdX5 "Touchscreen user interface computer: uss threshold X5";
CM_ SG_ 1827 UI_ussThresholdX6 "Touchscreen user interface computer: uss threshold X6";
CM_ SG_ 1827 UI_ussThresholdX7 "Touchscreen user interface computer: uss threshold X7";
CM_ SG_ 1827 UI_ussThresholdX8 "Touchscreen user interface computer: uss threshold X8";
CM_ SG_ 1827 UI_ussThresholdX9 "Touchscreen user interface computer: uss threshold X9";
CM_ SG_ 1827 UI_ussThresholdX10 "Touchscreen user interface computer: uss threshold X10";
CM_ SG_ 1827 UI_ussThresholdX11 "Touchscreen user interface computer: uss threshold X11";
CM_ SG_ 1827 UI_ussThresholdXControl "Touchscreen user interface computer: uss threshold x control";
CM_ BO_ 1829 "Touchscreen user interface computer message: uss thresholds y";
CM_ SG_ 1829 UI_ussSensorIdY "Touchscreen user interface computer: uss sensor id y";
CM_ SG_ 1829 UI_ussThresholdY0 "Touchscreen user interface computer: uss threshold Y0";
CM_ SG_ 1829 UI_ussThresholdY1 "Touchscreen user interface computer: uss threshold Y1";
CM_ SG_ 1829 UI_ussThresholdY2 "Touchscreen user interface computer: uss threshold Y2";
CM_ SG_ 1829 UI_ussThresholdY3 "Touchscreen user interface computer: uss threshold Y3";
CM_ SG_ 1829 UI_ussThresholdY4 "Touchscreen user interface computer: uss threshold Y4";
CM_ SG_ 1829 UI_ussThresholdY5 "Touchscreen user interface computer: uss threshold Y5";
CM_ SG_ 1829 UI_ussThresholdY6 "Touchscreen user interface computer: uss threshold Y6";
CM_ SG_ 1829 UI_ussThresholdY7 "Touchscreen user interface computer: uss threshold Y7";
CM_ SG_ 1829 UI_ussThresholdY8 "Touchscreen user interface computer: uss threshold Y8";
CM_ SG_ 1829 UI_ussThresholdY9 "Touchscreen user interface computer: uss threshold Y9";
CM_ SG_ 1829 UI_ussThresholdY10 "Touchscreen user interface computer: uss threshold Y10";
CM_ SG_ 1829 UI_ussThresholdY11 "Touchscreen user interface computer: uss threshold Y11";
CM_ SG_ 1829 UI_ussThresholdYControl "Touchscreen user interface computer: uss threshold y control";
CM_ BO_ 627 "Touchscreen user interface computer message: vehicle control";
CM_ SG_ 627 UI_powerStateRequest "Request accessory power";
CM_ SG_ 627 UI_childDoorLockOnRight "UI child door lock request status.";
CM_ SG_ 627 UI_frontFogSwitch "Request for front fog lights to be on";
CM_ SG_ 627 UI_summonActive "Summon is active";
CM_ SG_ 627 UI_frunkRequest "Request open frunk";
CM_ SG_ 627 UI_wiperMode "Wiper mode state; raw 0 = signal not available (SNA)";
CM_ SG_ 627 UI_steeringBacklightEnabled "Touchscreen user interface computer: steering backlight enabled";
CM_ SG_ 627 UI_steeringButtonMode "Steering wheel control mode";
CM_ SG_ 627 UI_walkUpUnlock "Walk up unlock request (datavalue defaults to false)";
CM_ SG_ 627 UI_walkAwayLock "Walk away door lock setting.";
CM_ SG_ 627 UI_unlockOnPark "Unlock on park setting";
CM_ SG_ 627 UI_globalUnlockOn "Global Unlock Setting";
CM_ SG_ 627 UI_childDoorLockOnLeft "UI child door lock request status.";
CM_ SG_ 627 UI_lockRequest "Lock or unlock request; raw 7 = signal not available (SNA)";
CM_ SG_ 627 UI_alarmEnabled "UI customer level request to enable alarm.";
CM_ SG_ 627 UI_intrusionSensorOn "Touchscreen user interface computer: intrusion sensor on";
CM_ SG_ 627 UI_stop12vSupport "UI request to stop rails as 12v support";
CM_ SG_ 627 UI_rearFogSwitch "Request for rear fog lights to be on";
CM_ SG_ 627 UI_mirrorFoldRequest "Fold the mirrors; raw 3 = signal not available (SNA)";
CM_ SG_ 627 UI_mirrorHeatRequest "Customer usage of mirror heater and rear defrost";
CM_ SG_ 627 UI_remoteStartRequest "remote start or self park request; raw 4 = signal not available (SNA)";
CM_ SG_ 627 UI_seeYouHomeLightingOn "Headlights after exit";
CM_ SG_ 627 UI_powerOff "power off rails request.";
CM_ SG_ 627 UI_displayBrightnessLevel "UI brightness; raw 255 = signal not available (SNA)";
CM_ SG_ 627 UI_ambientLightingEnabled "Touchscreen user interface computer: ambient lighting enabled";
CM_ SG_ 627 UI_autoHighBeamEnabled "Enable Automatic High/Low Beams";
CM_ SG_ 627 UI_frontLeftSeatHeatReq "Request for front left seat heat";
CM_ SG_ 627 UI_frontRightSeatHeatReq "Request for front left seat heat";
CM_ SG_ 627 UI_rearLeftSeatHeatReq "UI request for second row left seat heater";
CM_ SG_ 627 UI_rearCenterSeatHeatReq "UI request for second row middle seat heater";
CM_ SG_ 627 UI_rearRightSeatHeatReq "UI request for second row right seat heater";
CM_ SG_ 627 UI_autoFoldMirrorsOn "Enable Automatic Mirror Fold/Unfold";
CM_ SG_ 627 UI_mirrorDipOnReverse "Enable Mirror Dip On Reverse";
CM_ SG_ 627 UI_remoteClosureRequest "remote actuate trunk; raw 3 = signal not available (SNA)";
CM_ SG_ 627 UI_wiperRequest "Wiper speed; raw 0 = signal not available (SNA)";
CM_ SG_ 627 UI_domeLightSwitch "Dome light switch";
CM_ SG_ 627 UI_honkHorn "Touchscreen user interface computer: honk horn";
CM_ SG_ 627 UI_driveStateRequest "Touchscreen user interface computer: drive state request";
CM_ SG_ 627 UI_rearWindowLockout "Touchscreen user interface computer: rear window lockout";
CM_ BO_ 947 "Touchscreen user interface computer message: vehicle control2";
CM_ SG_ 947 UI_gloveboxRequest "UI request to open the glovebox";
CM_ SG_ 947 UI_trunkRequest "Rear trunk request";
CM_ SG_ 947 UI_UMCUpdateInhibit "Touchscreen user interface computer: UMC update inhibit";
CM_ SG_ 947 UI_WCUpdateInhibit "Touchscreen user interface computer: WC update inhibit";
CM_ SG_ 947 UI_soundHornOnLock "Touchscreen user interface computer: sound horn on lock";
CM_ SG_ 947 UI_locksPanelActive "Touchscreen user interface computer: locks panel active";
CM_ SG_ 947 UI_PINToDriveEnabled "UI customer level request to pin to drive enabled.";
CM_ SG_ 947 UI_PINToDrivePassed "UI customer level request to enable drive with pin passed.";
CM_ SG_ 947 UI_disableMirrorAutoDim "Request to disable side and rear-view mirror auto dim";
CM_ SG_ 947 UI_lightSwitch "Headlight mode; raw 4 = signal not available (SNA)";
CM_ SG_ 947 UI_readyToAddKey "Ready to add key";
CM_ SG_ 947 UI_alarmTriggerRequest "Alarm activation request from UI";
CM_ SG_ 947 UI_VCSECFeature1 "Touchscreen user interface computer: VCSEC feature1";
CM_ SG_ 947 UI_VCLEFTFeature1 "Touchscreen user interface computer: VCLEFT feature1";
CM_ SG_ 947 UI_summonState "Touchscreen user interface computer: summon state; raw 0 = signal not available (SNA)";
CM_ SG_ 947 UI_displayOnForUser "User is present";
CM_ SG_ 947 UI_freeRollModeRequest "Touchscreen user interface computer: free roll mode request";
CM_ SG_ 947 UI_BLEPushNotificationRequest "Reports that the User Interface (UI) wants to talk to a phone and Vehicle Controller Security (VCSEC) should let all connected phones know.";
CM_ SG_ 947 UI_pairKeyQRCodeDisplaying "Touchscreen user interface computer: pair key QR code displaying";
CM_ SG_ 947 UI_keepAutopilotAwake "Reports the request for Vehicle Controller (VC) to keep autopilot awake.";
CM_ SG_ 947 UI_batteryPreconditioningRequest "Requests battery preconditioning.";
CM_ SG_ 947 UI_coastDownMode "Touchscreen user interface computer: coast down mode";
CM_ SG_ 947 UI_autopilotPowerStateRequest "Requests different power states from autopilot ECU depending on feature usage.";
CM_ SG_ 947 UI_shorted12VCellTestMode "Touchscreen user interface computer: shorted12 v cell test mode";
CM_ SG_ 947 UI_autoRollWindowsOnLockEnable "UI customer level request to enable auto-roll windows on lock";
CM_ SG_ 947 UI_virtualPitchSensorOverrideOKF "Touchscreen user interface computer: virtual pitch sensor override OK for aim";
CM_ SG_ 947 UI_conditionalLoggingEnabledVCSE "Touchscreen user interface computer: conditional logging enabled VCSEC";
CM_ SG_ 947 UI_WC3UpdateInhibit "Touchscreen user interface computer: WC3 update inhibit";
CM_ SG_ 947 UI_steeringWheelHeatReq "Request to enable steering wheel heater";
CM_ SG_ 947 UI_disableHorn "Request to disable horn";
CM_ SG_ 947 UI_frontLeftSeatFanReq "Request for front left seat ventilation";
CM_ SG_ 947 UI_frontRightSeatAutoClimateReq "UI setting to enable auto seat heating and cooling for front right seat";
CM_ SG_ 947 UI_frontRightSeatFanReq "Request for front left seat ventilation";
CM_ SG_ 947 UI_3RLeftSeatHeatReq "UI request for third row left seat heater";
CM_ SG_ 947 UI_3RRightSeatHeatReq "UI request for third row right seat heater";
CM_ SG_ 947 UI_sleepFeature1 "Touchscreen user interface computer: sleep feature1";
CM_ SG_ 947 UI_dcr12VThreshold "Touchscreen user interface computer: dcr12 v threshold";
CM_ SG_ 947 UI_frontLeftSeatAutoClimateReq "UI setting to enable auto seat heating and cooling for front left seat";
CM_ SG_ 947 UI_wiperHeaterReq "UI request to enable the wiper heater";
CM_ SG_ 947 UI_tireSeason "Touchscreen user interface computer: tire season";
CM_ SG_ 947 UI_saveTireConfigReq "Touchscreen user interface computer: save tire config req";
CM_ SG_ 947 UI_silentAlarm "Signal indicating alarms should be silenced";
CM_ SG_ 947 UI_sleepFeature2 "Touchscreen user interface computer: sleep feature2";
CM_ BO_ 628 "Touchscreen user interface computer message: vehicle control3";
CM_ SG_ 628 UI_lightFlashRequest "UI flash lights request";
CM_ SG_ 628 UI_keylessDrivingEnabled "Touchscreen user interface computer: keyless driving enabled";
CM_ SG_ 628 UI_phoneCallActive "On phone call via Bluetooth if active";
CM_ SG_ 628 UI_drivingSideVEH "Touchscreen user interface computer: driving side VEH";
CM_ SG_ 628 UI_keyPairResponse "Touchscreen user interface computer: key pair response";
CM_ SG_ 628 UI_lightShowClosuresEnabled "Closure movements enabled during light show";
CM_ SG_ 628 UI_steeringWheelHeatAutoReq "UI setting to request auto steering wheel heat";
CM_ SG_ 628 UI_steeringWheelHeatLevelReq "Request for steering wheel heat";
CM_ SG_ 628 UI_headlightPulseRequest "Request headlights to pulse";
CM_ SG_ 628 UI_VCSECFeature2 "Touchscreen user interface computer: VCSEC feature2";
CM_ SG_ 628 UI_VCSECFeature3 "Touchscreen user interface computer: VCSEC feature3";
CM_ SG_ 628 UI_VCSECFeature4 "Touchscreen user interface computer: VCSEC feature4";
CM_ SG_ 628 UI_VCSECFeature5 "Touchscreen user interface computer: VCSEC feature5";
CM_ SG_ 628 UI_shortHornRequest "Touchscreen user interface computer: short horn request";
CM_ SG_ 628 UI_packTempLoggingRequest "Touchscreen user interface computer: pack temp logging request";
CM_ SG_ 628 UI_UMC3UpdateInhibit "Touchscreen user interface computer: UMC3 update inhibit";
CM_ SG_ 628 UI_handsFreeTrunk "Touchscreen user interface computer: hands free trunk";
CM_ SG_ 628 UI_displayRedShiftActive "UI's reduce blue light setting is active";
CM_ SG_ 628 UI_handsFreeFrunk "Touchscreen user interface computer: hands free frunk";
CM_ SG_ 628 UI_fasciaCameraWashRequest "User request to activate fascia camera wash";
CM_ SG_ 628 UI_autoClosuresExcludeHome "Touchscreen user interface computer: auto closures exclude home";
CM_ SG_ 628 UI_leftRearSeatAdjustmentRequest "Reports request from UI to actuate the left rear seat";
CM_ SG_ 628 UI_rightRearSeatAdjustmentReques "Reports request from UI to actuate the right rear seat";
CM_ SG_ 628 UI_blindSpotIndicatorLightReques "Request for blind spot indicator light";
CM_ SG_ 628 UI_etcBluetoothControl "Touchscreen user interface computer: etc bluetooth control";
CM_ SG_ 628 UI_keepOnAccessoryPortsReq "User setting to keep 12V outlets, USB ports, and phone chargers powered in CONDITIONING";
CM_ SG_ 628 UI_fasciaCameraShown "Whether the UI is currently showing the fascia camera view";
CM_ SG_ 628 UI_rearSeatChildLock "Reports the state of second row seat fold flat child lock from the UI";
CM_ SG_ 628 UI_windowPercentageRequest "Reports the window percentage value when window request is WINDOW_REQUEST_GOTO_PERCENT.";
CM_ SG_ 628 UI_windowRequestedFL "Reports that the front left window is requested.";
CM_ SG_ 628 UI_windowRequestedFR "Reports that the front right window is requested.";
CM_ SG_ 628 UI_windowRequestedRL "Reports that the rear left window is requested.";
CM_ SG_ 628 UI_windowRequestedRR "Reports that the rear right window is requested.";
CM_ SG_ 628 UI_windowRequest "Window operation request from the mobile app.";
CM_ SG_ 628 UI_closeTrunkRequest "Explicity request for the rear trunk to close";
CM_ SG_ 628 UI_childPresenceDetectionDisable "User request to disable child presence detection behaviors until the next drive cycle";
CM_ SG_ 628 UI_V2LAUpdateInhibit "Touchscreen user interface computer: V2 LA update inhibit";
CM_ SG_ 628 UI_userPresenceDetectionEnabled "Touchscreen user interface computer: user presence detection enabled";
CM_ SG_ 628 UI_derivedLoadshedFeature "Reports whether vehicle controllers should enable derived loadshed feature.";
CM_ SG_ 628 UI_rearSeatFoldConfirmed "Touchscreen user interface computer: rear seat fold confirmed";
CM_ SG_ 628 UI_leftRearSeatRequestFromRearDi "Touchscreen user interface computer: left rear seat request from rear display";
CM_ SG_ 628 UI_selfParkStandingBy "Reports that summon is in standby.";
CM_ SG_ 628 UI_rightRearSeatRequestFromRearD "Touchscreen user interface computer: right rear seat request from rear display";
CM_ BO_ 1193 "Touchscreen user interface computer message: vehicle control4";
CM_ SG_ 1193 UI_firstRowLeftDomeLightRequest "Monitors the dome light switch for first row left side";
CM_ SG_ 1193 UI_firstRowRightDomeLightRequest "Monitors the dome light switch for first row right side";
CM_ SG_ 1193 UI_secondRowLeftDomeLightRequest "Monitors the dome light switch for second row left side";
CM_ SG_ 1193 UI_secondRowCenterDomeLightReque "Monitors the dome light switch for second row center side";
CM_ SG_ 1193 UI_secondRowRightDomeLightReques "Monitors the dome light switch for second row right side";
CM_ SG_ 1193 UI_thirdRowLeftDomeLightRequest "Monitors the dome light switch for third row left side";
CM_ SG_ 1193 UI_thirdRowRightDomeLightRequest "Monitors the dome light switch for third row right side";
CM_ BO_ 853 "Touchscreen user interface computer message: vehicle control thermal";
CM_ SG_ 853 UI_coolantFlowRequest "request for coolant flow to MCU in LPM";
CM_ SG_ 853 UI_inletActiveCoolTarget "request for coolant temperature at Car Computer inlet";
CM_ SG_ 853 UI_disableHVPTThermalLoads "Request thermal system to disable active battery heating";
CM_ SG_ 853 UI_enableCompLiquidPumpOut "Touchscreen user interface computer: enable comp liquid pump out";
CM_ SG_ 853 UI_enableCOP1HighSHOperation "Touchscreen user interface computer: enable COP1 high SH operation";
CM_ SG_ 853 UI_enableIncreasedEvapRampRate "Touchscreen user interface computer: enable increased evap ramp rate";
CM_ SG_ 853 UI_enableCOP1BatteryHeating "Touchscreen user interface computer: enable COP1 battery heating";
CM_ SG_ 853 UI_enableCOP1CabinHeatingBattery "Touchscreen user interface computer: enable COP1 cabin heating battery heating";
CM_ SG_ 853 UI_enableLouverAutoDetection "Touchscreen user interface computer: enable louver auto detection";
CM_ SG_ 853 UI_enableUserFacingLowFlowDelive "Touchscreen user interface computer: enable user facing low flow delivery alert";
CM_ SG_ 853 UI_disableHvacCameraOnlyDefog "Touchscreen user interface computer: disable hvac camera only defog";
CM_ SG_ 853 UI_enableEXVFastCalibration "Touchscreen user interface computer: enable EXV fast calibration";
CM_ SG_ 853 UI_enableThermalDriverlessSelfTe "Touchscreen user interface computer: enable thermal driverless self test";
CM_ SG_ 853 UI_enableCoolantDasTarget "Touchscreen user interface computer: enable coolant das target";
CM_ SG_ 853 UI_geofencedLiftgateHeight "Touchscreen user interface computer: geofenced liftgate height; raw 255 = signal not available (SNA)";
CM_ SG_ 853 UI_convenienceFeatureLimit "UI limit request in SOE (UI Gauge) for convenience features";
CM_ SG_ 853 UI_allowConvenienceFeatures "Whether UI allows convenenience features";
CM_ SG_ 853 UI_enableConservativeBatteryHeat "Touchscreen user interface computer: enable conservative battery heating";
CM_ SG_ 853 UI_enableDefaultApTempTarget "Touchscreen user interface computer: enable default ap temp target";
CM_ SG_ 853 UI_enableHVACCompressorWasteHeat "Touchscreen user interface computer: enable HVAC compressor waste heat";
CM_ SG_ 853 UI_disablePhoneChargingPads "Reports requests from the User Interface (UI) to disable wireless phone charging.";
CM_ SG_ 853 UI_isAtTeslaFacility "Touchscreen user interface computer: is at tesla facility";
CM_ SG_ 853 UI_enableThermalPowerBudget "Touchscreen user interface computer: enable thermal power budget";
CM_ SG_ 853 UI_enableHVACAPFanHeaterControl "Touchscreen user interface computer: enable HVACAP fan heater control";
CM_ SG_ 853 UI_enableAutopilotAirPurge "Touchscreen user interface computer: enable autopilot air purge";
CM_ SG_ 853 UI_enableForcedAirCameraHeater "Touchscreen user interface computer: enable forced air camera heater";
CM_ SG_ 853 UI_enableHvacCOPOnUndeliveredVeh "Touchscreen user interface computer: enable hvac COP on undelivered veh";
CM_ BO_ 644 "Touchscreen user interface computer message: vehicle modes";
CM_ SG_ 644 UI_factoryMode "Touchscreen user interface computer: factory mode";
CM_ SG_ 644 UI_transportMode "Reports UI Transport mode. Distinct from GTW transport mode.";
CM_ SG_ 644 UI_showroomMode "Reports UI showroom mode.";
CM_ SG_ 644 UI_serviceMode "Service diagnostics mode active";
CM_ SG_ 644 UI_isDelivered "Touchscreen user interface computer: is delivered";
CM_ SG_ 644 UI_hasEverBeenDelivered "Touchscreen user interface computer: has ever been delivered";
CM_ SG_ 644 UI_homelinkV2Command0 "Touchscreen user interface computer: homelink V2 command0";
CM_ SG_ 644 UI_homelinkV2Command1 "Touchscreen user interface computer: homelink V2 command1";
CM_ SG_ 644 UI_homelinkV2Command2 "Touchscreen user interface computer: homelink V2 command2";
CM_ SG_ 644 UI_carWashMode "Car Wash Mode";
CM_ SG_ 644 UI_valetMode "Touchscreen user interface computer: valet mode";
CM_ SG_ 644 UI_gameMode "Game mode";
CM_ SG_ 644 UI_diagnosticsAllowed "Touchscreen user interface computer: diagnostics allowed";
CM_ SG_ 644 UI_serviceModePlus "Extended service diagnostics mode active";
CM_ SG_ 644 UI_premiumAmpPowerOff "Premium amplifier power off request";
CM_ SG_ 644 UI_signedCmdHardLocked "Touchscreen user interface computer: signed cmd hard locked";
CM_ SG_ 644 UI_signedCmdServiceMode "Signal reported by Touchscreen user interface computer";
CM_ SG_ 644 UI_closureEasterEggStatus "Touchscreen user interface computer: closure easter egg status";
CM_ SG_ 644 UI_lightShowType "Type of the light show to be run";
CM_ SG_ 644 UI_sohTestRequest "Touchscreen user interface computer: soh test request";
CM_ SG_ 644 UI_upkeepMode "Reports UI Upkeep Mode state.";
CM_ SG_ 644 UI_vehicleModesCounter "Touchscreen user interface computer: vehicle modes counter";
CM_ SG_ 644 UI_vehicleModesChecksum "Touchscreen user interface computer: vehicle modes checksum";
CM_ BO_ 595 "Touchscreen user interface computer message: vent panel control request";
CM_ SG_ 595 UI_ventPanelControlRequestIndex "Touchscreen user interface computer: vent panel control request index";
CM_ SG_ 595 UI_ventPanelLeftPositionX "Airwave left X position.";
CM_ SG_ 595 UI_ventPanelLeftPositionY "Airwave left Y position.";
CM_ SG_ 595 UI_ventPanelLeftLateralSplit "Airwave left split amount.";
CM_ SG_ 595 UI_ventPanelRightPositionX "Airwave right X position.";
CM_ SG_ 595 UI_ventPanelRightPositionY "Airwave right Y position.";
CM_ SG_ 595 UI_ventPanelRightLateralSplit "Airwave right split amount.";
CM_ SG_ 595 UI_ventPanelLeftLateralMode "Airwave left focus or split.";
CM_ SG_ 595 UI_ventPanelRightLateralMode "Airwave right focus or split.";
CM_ SG_ 595 UI_hvacReqActiveVents "Active airwave sides - left/right/both";
CM_ SG_ 595 UI_vent2RLeftPositionX "Airwave left X position.";
CM_ SG_ 595 UI_vent2RLeftPositionY "Airwave left Y position.";
CM_ SG_ 595 UI_vent2RRightPositionX "Airwave left X position.";
CM_ SG_ 595 UI_vent2RRightPositionY "Airwave left Y position.";
CM_ SG_ 595 UI_hvacReqThirdRowState "Detects HVAC third row fan speed request.";
CM_ BO_ 1569 "Touchscreen user interface computer message: weather data service";
CM_ SG_ 1569 UI_weatherSvcTimeSinceLast "Touchscreen user interface computer: weather svc time since last; raw 127 = signal not available (SNA)";
CM_ SG_ 1569 UI_weatherSvcWindDir "Touchscreen user interface computer: weather svc wind dir; raw 255 = signal not available (SNA)";
CM_ SG_ 1569 UI_weatherSvcTemperature "Touchscreen user interface computer: weather svc temperature; raw 255 = signal not available (SNA)";
CM_ SG_ 1569 UI_weatherSvcHumidity "Touchscreen user interface computer: weather svc humidity; raw 63 = signal not available (SNA)";
CM_ SG_ 1569 UI_weatherSvcDewPoint "Touchscreen user interface computer: weather svc dew point; raw 255 = signal not available (SNA)";
CM_ SG_ 1569 UI_weatherSvcCloudCover "Touchscreen user interface computer: weather svc cloud cover; raw 63 = signal not available (SNA)";
CM_ SG_ 1569 UI_weatherSvcPrecipProb "Touchscreen user interface computer: weather svc precip prob; raw 63 = signal not available (SNA)";
CM_ SG_ 1569 UI_weatherSvcRaining "Touchscreen user interface computer: weather svc raining";
CM_ SG_ 1569 UI_weatherSvcSnowing "Touchscreen user interface computer: weather svc snowing";
CM_ SG_ 1569 UI_weatherSvcWindSpeed "Touchscreen user interface computer: weather svc wind speed; raw 63 = signal not available (SNA)";
CM_ BO_ 1969 "Touchscreen user interface computer message: weather data service forecast";
CM_ SG_ 1969 UI_weatherSvcForecastMuxIndex "Touchscreen user interface computer: weather svc forecast mux index";
CM_ SG_ 1969 UI_weatherSvcForecastTempC_hour1 "Touchscreen user interface computer: weather svc forecast temp c hour1; raw 255 = signal not available (SNA)";
CM_ SG_ 1969 UI_weatherSvcForecastTempC_hour2 "Touchscreen user interface computer: weather svc forecast temp c hour2; raw 255 = signal not available (SNA)";
CM_ SG_ 1969 UI_weatherSvcForecastTempC_hour3 "Touchscreen user interface computer: weather svc forecast temp c hour3; raw 255 = signal not available (SNA)";
CM_ SG_ 1969 UI_weatherSvcForecastTempC_hour4 "Touchscreen user interface computer: weather svc forecast temp c hour4; raw 255 = signal not available (SNA)";
CM_ SG_ 1969 UI_weatherSvcForecastTempC_hour5 "Touchscreen user interface computer: weather svc forecast temp c hour5; raw 255 = signal not available (SNA)";
CM_ SG_ 1969 UI_weatherSvcForecastTempC_hour6 "Touchscreen user interface computer: weather svc forecast temp c hour6; raw 255 = signal not available (SNA)";
CM_ SG_ 1969 UI_weatherSvcForecastTempC_hour7 "Touchscreen user interface computer: weather svc forecast temp c hour7; raw 255 = signal not available (SNA)";
CM_ SG_ 1969 UI_weatherSvcForecastTempC_hour8 "Touchscreen user interface computer: weather svc forecast temp c hour8; raw 255 = signal not available (SNA)";
CM_ SG_ 1969 UI_weatherSvcForecastTempC_hour9 "Touchscreen user interface computer: weather svc forecast temp c hour9; raw 255 = signal not available (SNA)";
CM_ SG_ 1969 UI_weatherSvcForecastTempC__0001 "Touchscreen user interface computer: weather svc forecast temp c hour10; raw 255 = signal not available (SNA)";
CM_ SG_ 1969 UI_weatherSvcForecastTempC__0002 "Touchscreen user interface computer: weather svc forecast temp c hour11; raw 255 = signal not available (SNA)";
CM_ SG_ 1969 UI_weatherSvcForecastHumidity_ho "Touchscreen user interface computer: weather svc forecast humidity hour1; raw 63 = signal not available (SNA)";
CM_ SG_ 1969 UI_weatherSvcForecastHumidi_0003 "Touchscreen user interface computer: weather svc forecast humidity hour2; raw 63 = signal not available (SNA)";
CM_ SG_ 1969 UI_weatherSvcForecastHumidi_0004 "Touchscreen user interface computer: weather svc forecast humidity hour3; raw 63 = signal not available (SNA)";
CM_ SG_ 1969 UI_weatherSvcForecastHumidi_0005 "Touchscreen user interface computer: weather svc forecast humidity hour4; raw 63 = signal not available (SNA)";
CM_ SG_ 1969 UI_weatherSvcForecastHumidi_0006 "Touchscreen user interface computer: weather svc forecast humidity hour5; raw 63 = signal not available (SNA)";
CM_ SG_ 1969 UI_weatherSvcForecastHumidi_0007 "Touchscreen user interface computer: weather svc forecast humidity hour6; raw 63 = signal not available (SNA)";
CM_ SG_ 1969 UI_weatherSvcForecastHumidi_0008 "Touchscreen user interface computer: weather svc forecast humidity hour7; raw 63 = signal not available (SNA)";
CM_ SG_ 1969 UI_weatherSvcForecastHumidi_0009 "Touchscreen user interface computer: weather svc forecast humidity hour8; raw 63 = signal not available (SNA)";
CM_ SG_ 1969 UI_weatherSvcForecastHumidi_0010 "Touchscreen user interface computer: weather svc forecast humidity hour9; raw 63 = signal not available (SNA)";
CM_ SG_ 1969 UI_weatherSvcForecastHumidi_0001 "Touchscreen user interface computer: weather svc forecast humidity hour10; raw 63 = signal not available (SNA)";
CM_ SG_ 1969 UI_weatherSvcForecastHumidi_0002 "Touchscreen user interface computer: weather svc forecast humidity hour11; raw 63 = signal not available (SNA)";
CM_ SG_ 1969 UI_weatherSvcForecastWindSpeedKp "Touchscreen user interface computer: weather svc forecast wind speed kph hour1; raw 63 = signal not available (SNA)";
CM_ SG_ 1969 UI_weatherSvcForecastWindSp_0003 "Touchscreen user interface computer: weather svc forecast wind speed kph hour2; raw 63 = signal not available (SNA)";
CM_ SG_ 1969 UI_weatherSvcForecastWindSp_0004 "Touchscreen user interface computer: weather svc forecast wind speed kph hour3; raw 63 = signal not available (SNA)";
CM_ SG_ 1969 UI_weatherSvcForecastWindSp_0005 "Touchscreen user interface computer: weather svc forecast wind speed kph hour4; raw 63 = signal not available (SNA)";
CM_ SG_ 1969 UI_weatherSvcForecastWindSp_0006 "Touchscreen user interface computer: weather svc forecast wind speed kph hour5; raw 63 = signal not available (SNA)";
CM_ SG_ 1969 UI_weatherSvcForecastWindSp_0007 "Touchscreen user interface computer: weather svc forecast wind speed kph hour6; raw 63 = signal not available (SNA)";
CM_ SG_ 1969 UI_weatherSvcForecastWindSp_0008 "Touchscreen user interface computer: weather svc forecast wind speed kph hour7; raw 63 = signal not available (SNA)";
CM_ SG_ 1969 UI_weatherSvcForecastWindSp_0009 "Touchscreen user interface computer: weather svc forecast wind speed kph hour8; raw 63 = signal not available (SNA)";
CM_ SG_ 1969 UI_weatherSvcForecastWindSp_0010 "Touchscreen user interface computer: weather svc forecast wind speed kph hour9; raw 63 = signal not available (SNA)";
CM_ SG_ 1969 UI_weatherSvcForecastWindSp_0001 "Touchscreen user interface computer: weather svc forecast wind speed kph hour10; raw 63 = signal not available (SNA)";
CM_ SG_ 1969 UI_weatherSvcForecastWindSp_0002 "Touchscreen user interface computer: weather svc forecast wind speed kph hour11; raw 63 = signal not available (SNA)";
CM_ BO_ 1533 "UMC ECU message: alert log";
CM_ SG_ 1533 UMC_alertID "UMC ECU: alert ID";
CM_ SG_ 1533 UMC_alertType "UMC ECU: alert type";
CM_ SG_ 1533 UMC_a001_groundImpedance "UMC ECU: a001 ground impedance";
CM_ SG_ 1533 UMC_a002_ccidRmsCurrent "UMC ECU: a002 ccid rms current";
CM_ SG_ 1533 UMC_a002_ccidRmsCurrentAvg "UMC ECU: a002 ccid rms current avg";
CM_ SG_ 1533 UMC_a002_ccidDCGfciCurrent "UMC ECU: a002 ccid DC gfci current";
CM_ SG_ 1533 UMC_a002_ccidFaultReason "UMC ECU: a002 ccid fault reason; raw 0 = signal not available (SNA)";
CM_ SG_ 1533 UMC_a002_ccidFaultBucket "UMC ECU: a002 ccid fault bucket";
CM_ SG_ 1533 UMC_a003_faultType "UMC ECU: a003 fault type";
CM_ SG_ 1533 UMC_a003_ccidSelfTestDuty "UMC ECU: a003 ccid self test duty";
CM_ SG_ 1533 UMC_a003_ccidSelfTestCurrent "UMC ECU: a003 ccid self test current";
CM_ SG_ 1533 UMC_a004_lineVoltage "UMC ECU: a004 line voltage";
CM_ SG_ 1533 UMC_a004_inputVoltage "UMC ECU: a004 input voltage";
CM_ SG_ 1533 UMC_a004_inputNeutralVoltage "UMC ECU: a004 input neutral voltage";
CM_ SG_ 1533 UMC_a005_lineVoltage "UMC ECU: a005 line voltage";
CM_ SG_ 1533 UMC_a005_inputVoltage "UMC ECU: a005 input voltage";
CM_ SG_ 1533 UMC_a005_inputNeutralVoltage "UMC ECU: a005 input neutral voltage";
CM_ SG_ 1533 UMC_a006_outputVoltage "UMC ECU: a006 output voltage";
CM_ SG_ 1533 UMC_a006_faultType "UMC ECU: a006 fault type";
CM_ SG_ 1533 UMC_a006_umcReceptacleVoltage "UMC ECU: a006 umc receptacle voltage";
CM_ SG_ 1533 UMC_a006_handleVoltage "UMC ECU: a006 handle voltage";
CM_ SG_ 1533 UMC_a006_line1StuckClosed "UMC ECU: a006 line1 stuck closed";
CM_ SG_ 1533 UMC_a006_line2StuckClosed "UMC ECU: a006 line2 stuck closed";
CM_ SG_ 1533 UMC_a007_pcbaTemp "UMC ECU: a007 pcba temp";
CM_ SG_ 1533 UMC_a008_wallPlugTemp "UMC ECU: a008 wall plug temp";
CM_ SG_ 1533 UMC_a008_SA_region "UMC ECU: a008 SA region";
CM_ SG_ 1533 UMC_a008_SA_current "UMC ECU: a008 SA current";
CM_ SG_ 1533 UMC_a009_vehConnTemp "UMC ECU: a009 veh conn temp";
CM_ SG_ 1533 UMC_a010_inputTerminalsTemp "UMC ECU: a010 input terminals temp";
CM_ SG_ 1533 UMC_a012_pilotHigh "UMC ECU: a012 pilot high";
CM_ SG_ 1533 UMC_a012_pilotLow "UMC ECU: a012 pilot low";
CM_ SG_ 1533 UMC_a013_SA_region "UMC ECU: a013 SA region";
CM_ SG_ 1533 UMC_a013_SA_current "UMC ECU: a013 SA current";
CM_ SG_ 1533 UMC_a015_SA_region "UMC ECU: a015 SA region";
CM_ SG_ 1533 UMC_a015_SA_current "UMC ECU: a015 SA current";
CM_ SG_ 1533 UMC_a016_pcbaTemp "UMC ECU: a016 pcba temp";
CM_ SG_ 1533 UMC_a017_wallPlugTemp "UMC ECU: a017 wall plug temp";
CM_ SG_ 1533 UMC_a017_SA_region "UMC ECU: a017 SA region";
CM_ SG_ 1533 UMC_a017_SA_current "UMC ECU: a017 SA current";
CM_ SG_ 1533 UMC_a018_vehConnTemp "UMC ECU: a018 veh conn temp";
CM_ SG_ 1533 UMC_a019_inputTerminalsTemp "UMC ECU: a019 input terminals temp";
CM_ SG_ 1533 UMC_a024_groundImpedance "UMC ECU: a024 ground impedance";
CM_ SG_ 1533 UMC_a040_groundImpedance "UMC ECU: a040 ground impedance";
CM_ BO_ 824 "UMC ECU message: alert matrix1";
CM_ SG_ 824 UMC_a001_gndMonIntrptLineSide "UMC ECU: a001 gnd mon intrpt line side";
CM_ SG_ 824 UMC_a002_GFCITripped "UMC ECU: a002 GFCI tripped";
CM_ SG_ 824 UMC_a003_GFCISelfTestFault "UMC ECU: a003 GFCI self test fault";
CM_ SG_ 824 UMC_a004_inputOverVoltage "UMC ECU: a004 input over voltage";
CM_ SG_ 824 UMC_a005_inputUnderVoltage "UMC ECU: a005 input under voltage";
CM_ SG_ 824 UMC_a006_contactorWelded "UMC ECU: a006 contactor welded";
CM_ SG_ 824 UMC_a007_pcbaOT "UMC ECU: a007 pcba OT";
CM_ SG_ 824 UMC_a008_wallPlugOT "UMC ECU: a008 wall plug OT";
CM_ SG_ 824 UMC_a009_vehConnOT "UMC ECU: a009 veh conn OT";
CM_ SG_ 824 UMC_a010_inputOT "UMC ECU: a010 input OT";
CM_ SG_ 824 UMC_a011_proxDisconnected "UMC ECU: a011 prox disconnected";
CM_ SG_ 824 UMC_a012_pilotFault "UMC ECU: a012 pilot fault";
CM_ SG_ 824 UMC_a013_SA_Temperature "UMC ECU: a013 SA temperature";
CM_ SG_ 824 UMC_a014_SA_Genealogy "UMC ECU: a014 SA genealogy";
CM_ SG_ 824 UMC_a015_SA_Connection "UMC ECU: a015 SA connection";
CM_ SG_ 824 UMC_a016_pcbaOTFoldback "UMC ECU: a016 pcba OT foldback";
CM_ SG_ 824 UMC_a017_wallPlugOTFoldback "UMC ECU: a017 wall plug OT foldback";
CM_ SG_ 824 UMC_a018_vehConnOTFoldback "UMC ECU: a018 veh conn OT foldback";
CM_ SG_ 824 UMC_a019_inputOTFoldback "UMC ECU: a019 input OT foldback";
CM_ SG_ 824 UMC_a020_applicationCRC "UMC ECU: a020 application CRC";
CM_ SG_ 824 UMC_a021_dataBus "UMC ECU: a021 data bus";
CM_ SG_ 824 UMC_a022_criticalRAM "UMC ECU: a022 critical RAM";
CM_ SG_ 824 UMC_a023_adcSelfTest "UMC ECU: a023 adc self test";
CM_ SG_ 824 UMC_a024_gndResistanceHigh "UMC ECU: a024 gnd resistance high";
CM_ SG_ 824 UMC_a025_cntrOpenExpectedClose "UMC ECU: a025 cntr open expected close";
CM_ SG_ 824 UMC_a026_vRefOutOfRange "UMC ECU: a026 v ref out of range";
CM_ SG_ 824 UMC_a027_watchdogExpired "UMC ECU: a027 watchdog expired";
CM_ SG_ 824 UMC_a028_processorBooted "UMC ECU: a028 processor booted";
CM_ SG_ 824 UMC_a029_acPowerLoss "UMC ECU: a029 ac power loss";
CM_ SG_ 824 UMC_a030_acLostPllLock "UMC ECU: a030 ac lost pll lock";
CM_ SG_ 824 UMC_a031_relayCoilVIrrational "UMC ECU: a031 relay coil v irrational";
CM_ SG_ 824 UMC_a032_chcVitalsRequestFailure "UMC ECU: a032 chc vitals request failure";
CM_ SG_ 824 UMC_a033_chcUpdateFault "UMC ECU: a033 chc update fault";
CM_ SG_ 824 UMC_a034_v2lSAUnsupported "UMC ECU: a034 v2l SA unsupported";
CM_ SG_ 824 UMC_a035_v2lHVACDetected "UMC ECU: a035 v2l HVAC detected";
CM_ SG_ 824 UMC_a037_GFCICalibration "UMC ECU: a037 GFCI calibration";
CM_ SG_ 824 UMC_a038_chcVitalsFault "UMC ECU: a038 chc vitals fault";
CM_ SG_ 824 UMC_a039_inputOverCurrent "UMC ECU: a039 input over current";
CM_ SG_ 824 UMC_a040_gndDisconnected "UMC ECU: a040 gnd disconnected";
CM_ SG_ 824 UMC_a041_handleTempIrrational "UMC ECU: a041 handle temp irrational";
CM_ SG_ 824 UMC_a042_GFCICalRelayDelta "UMC ECU: a042 GFCI cal relay delta";
CM_ BO_ 1285 "UMC ECU message: smart adapter info";
CM_ SG_ 1285 SA_infoIndex "UMC ECU: info index";
CM_ SG_ 1285 SA_genealogyVersion "UMC ECU: genealogy version";
CM_ SG_ 1285 SA_genealogyCrc "UMC ECU: genealogy crc";
CM_ SG_ 1285 SA_region "Reports the smart adapter region from Electrically Erasable Programmable Read-Only Memory (EEPROM).";
CM_ SG_ 1285 SA_OverTempThreshold "Reports the smart adapter overtemperature threshold from Electrically Erasable Programmable Read-Only Memory (EEPROM).";
CM_ SG_ 1285 SA_partNumInt "Reports the smart adapter part number integer representation.";
CM_ SG_ 1285 SA_partNumRev "Reports the smart adapter part number revision.";
CM_ SG_ 1285 SA_currentLimit "Reports the smart adapter current limit from Electrically Erasable Programmable Read-Only Memory (EEPROM).";
CM_ SG_ 1285 SA_l1Voltage "Reports the smart adapter nominal voltage request from Electrically Erasable Programmable Read-Only Memory (EEPROM).";
BA_DEF_ BO_ "GenMsgCycleTime" INT 0 3600000;
BA_DEF_ BO_ "GenMsgSendType" ENUM "Cyclic","NotUsed","NotUsed","NotUsed","NotUsed","NotUsed","NotUsed","IfActive","NoMsgSendType","NotUsed";
BA_DEF_ BO_ "VFrameFormat" ENUM "StandardCAN","ExtendedCAN","reserved","J1939PG","reserved","reserved","reserved","reserved","reserved","reserved","reserved","reserved","reserved","reserved","StandardCAN_FD","ExtendedCAN_FD";
BA_DEF_ BO_ "CANFD_BRS" ENUM "0","1";
BA_DEF_ SG_ "GenSigSNA" STRING;
BA_DEF_ SG_ "SystemSignalLongSymbol" STRING;
BA_DEF_ SG_ "Confidence" ENUM "validated","plausible","layout-only","contradicted";
BA_DEF_DEF_ "GenMsgCycleTime" 0;
BA_DEF_DEF_ "GenMsgSendType" "NoMsgSendType";
BA_DEF_DEF_ "VFrameFormat" "StandardCAN";
BA_DEF_DEF_ "CANFD_BRS" "1";
BA_DEF_DEF_ "GenSigSNA" "";
BA_DEF_DEF_ "SystemSignalLongSymbol" "";
BA_DEF_DEF_ "Confidence" "layout-only";
BA_ "GenMsgCycleTime" BO_ 666 500;
BA_ "GenMsgSendType" BO_ 666 0;
BA_ "GenMsgCycleTime" BO_ 723 1000;
BA_ "GenMsgSendType" BO_ 723 0;
BA_ "GenMsgCycleTime" BO_ 563 500;
BA_ "GenMsgSendType" BO_ 563 0;
BA_ "GenMsgCycleTime" BO_ 851 500;
BA_ "GenMsgSendType" BO_ 851 0;
BA_ "GenMsgCycleTime" BO_ 991 500;
BA_ "GenMsgSendType" BO_ 991 0;
BA_ "GenMsgCycleTime" BO_ 986 1000;
BA_ "GenMsgSendType" BO_ 986 0;
BA_ "GenMsgCycleTime" BO_ 988 1000;
BA_ "GenMsgSendType" BO_ 988 0;
BA_ "GenMsgCycleTime" BO_ 663 500;
BA_ "GenMsgSendType" BO_ 663 0;
BA_ "GenMsgCycleTime" BO_ 661 15000;
BA_ "GenMsgSendType" BO_ 661 0;
BA_ "GenMsgCycleTime" BO_ 1064 1000;
BA_ "GenMsgSendType" BO_ 1064 0;
BA_ "GenMsgCycleTime" BO_ 952 1000;
BA_ "GenMsgSendType" BO_ 952 0;
BA_ "GenMsgCycleTime" BO_ 787 500;
BA_ "GenMsgSendType" BO_ 787 0;
BA_ "GenMsgCycleTime" BO_ 1263 1000;
BA_ "GenMsgSendType" BO_ 1263 0;
BA_ "GenMsgCycleTime" BO_ 130 1000;
BA_ "GenMsgSendType" BO_ 130 0;
BA_ "GenMsgCycleTime" BO_ 139 1000;
BA_ "GenMsgSendType" BO_ 139 0;
BA_ "GenMsgCycleTime" BO_ 1173 1000;
BA_ "GenMsgSendType" BO_ 1173 0;
BA_ "GenMsgCycleTime" BO_ 1174 1000;
BA_ "GenMsgSendType" BO_ 1174 0;
BA_ "GenMsgCycleTime" BO_ 1175 1000;
BA_ "GenMsgSendType" BO_ 1175 0;
BA_ "GenMsgCycleTime" BO_ 850 500;
BA_ "GenMsgSendType" BO_ 850 0;
BA_ "GenMsgCycleTime" BO_ 627 500;
BA_ "GenMsgSendType" BO_ 627 0;
BA_ "GenMsgCycleTime" BO_ 947 500;
BA_ "GenMsgSendType" BO_ 947 0;
BA_ "GenMsgCycleTime" BO_ 628 500;
BA_ "GenMsgSendType" BO_ 628 0;
BA_ "GenMsgCycleTime" BO_ 1193 500;
BA_ "GenMsgSendType" BO_ 1193 0;
BA_ "GenMsgCycleTime" BO_ 853 1000;
BA_ "GenMsgSendType" BO_ 853 0;
BA_ "GenMsgCycleTime" BO_ 644 500;
BA_ "GenMsgSendType" BO_ 644 0;
BA_ "GenMsgCycleTime" BO_ 595 500;
BA_ "GenMsgSendType" BO_ 595 0;
BA_ "GenMsgCycleTime" BO_ 1569 500;
BA_ "GenMsgSendType" BO_ 1569 0;
BA_ "GenMsgCycleTime" BO_ 1969 10000;
BA_ "GenMsgSendType" BO_ 1969 0;
BA_ "GenMsgCycleTime" BO_ 824 1000;
BA_ "GenMsgSendType" BO_ 824 0;
BA_ "GenMsgCycleTime" BO_ 1285 100;
BA_ "GenMsgSendType" BO_ 1285 0;
BA_ "Confidence" SG_ 666 UI_seatControlIndex 1;
BA_ "Confidence" SG_ 666 UI_3RSeatChildLock 0;
BA_ "Confidence" SG_ 666 UI_left3RowSeatAdjustmentRequest 0;
BA_ "Confidence" SG_ 666 UI_right3RowSeatAdjustmentReques 0;
BA_ "SystemSignalLongSymbol" SG_ 666 UI_right3RowSeatAdjustmentReques "UI_right3RowSeatAdjustmentRequest";
BA_ "Confidence" SG_ 666 UI_2RLeftSeatFanReq 0;
BA_ "Confidence" SG_ 666 UI_2RRightSeatFanReq 0;
BA_ "SystemSignalLongSymbol" SG_ 666 UI_leftThirdRowSeatRequestFromRe "UI_leftThirdRowSeatRequestFromRearDisplay";
BA_ "SystemSignalLongSymbol" SG_ 666 UI_rightThirdRowSeatRequestFromR "UI_rightThirdRowSeatRequestFromRearDisplay";
BA_ "Confidence" SG_ 666 UI_seatChoreographyStopRequest 0;
BA_ "Confidence" SG_ 723 UI_solarAzimuthAngle 1;
BA_ "GenSigSNA" SG_ 723 UI_solarAzimuthAngle "32768";
BA_ "Confidence" SG_ 723 UI_solarAzimuthAngleCarRef 1;
BA_ "GenSigSNA" SG_ 723 UI_solarAzimuthAngleCarRef "255";
BA_ "Confidence" SG_ 723 UI_isSunUp 0;
BA_ "GenSigSNA" SG_ 723 UI_isSunUp "3";
BA_ "Confidence" SG_ 723 UI_solarElevationAngle 0;
BA_ "GenSigSNA" SG_ 723 UI_solarElevationAngle "127";
BA_ "Confidence" SG_ 723 UI_screenPCBTemperature 0;
BA_ "Confidence" SG_ 723 UI_minsToSunset 0;
BA_ "Confidence" SG_ 723 UI_minsToSunrise 0;
BA_ "Confidence" SG_ 563 UI_gearRequest 0;
BA_ "GenSigSNA" SG_ 563 UI_gearRequest "0";
BA_ "Confidence" SG_ 563 UI_autopilotRequest 1;
BA_ "Confidence" SG_ 563 UI_gearStripShowing 0;
BA_ "Confidence" SG_ 563 UI_gearStripLocation 1;
BA_ "Confidence" SG_ 563 UI_gearStripForceShow 0;
BA_ "Confidence" SG_ 563 UI_autoParkAvailable 0;
BA_ "Confidence" SG_ 563 UI_gearStripSuppressActive 0;
BA_ "Confidence" SG_ 563 UI_gearNeutralPressed 0;
BA_ "Confidence" SG_ 851 UI_touchActive 0;
BA_ "Confidence" SG_ 851 UI_audioActive 0;
BA_ "Confidence" SG_ 851 UI_bluetoothActive 1;
BA_ "Confidence" SG_ 851 UI_cellActive 0;
BA_ "Confidence" SG_ 851 UI_displayReady 0;
BA_ "Confidence" SG_ 851 UI_displayOn 0;
BA_ "Confidence" SG_ 851 UI_wifiActive 0;
BA_ "Confidence" SG_ 851 UI_wifiConnected 0;
BA_ "Confidence" SG_ 851 UI_systemActive 1;
BA_ "Confidence" SG_ 851 UI_readyForDrive 0;
BA_ "Confidence" SG_ 851 UI_cellConnected 0;
BA_ "Confidence" SG_ 851 UI_vpnActive 0;
BA_ "Confidence" SG_ 851 UI_autopilotTrial 1;
BA_ "Confidence" SG_ 851 UI_factoryReset 0;
BA_ "GenSigSNA" SG_ 851 UI_factoryReset "0";
BA_ "Confidence" SG_ 851 UI_gpsActive 0;
BA_ "Confidence" SG_ 851 UI_screenshotActive 1;
BA_ "Confidence" SG_ 851 UI_radioActive 1;
BA_ "Confidence" SG_ 851 UI_cellNetworkTechnology 0;
BA_ "GenSigSNA" SG_ 851 UI_cellNetworkTechnology "15";
BA_ "Confidence" SG_ 851 UI_cellReceiverPower 1;
BA_ "Confidence" SG_ 851 UI_falseTouchCounter 0;
BA_ "Confidence" SG_ 851 UI_developmentCar 1;
BA_ "Confidence" SG_ 851 UI_cameraActive 1;
BA_ "Confidence" SG_ 851 UI_cellSignalBars 0;
BA_ "GenSigSNA" SG_ 851 UI_cellSignalBars "7";
BA_ "Confidence" SG_ 851 UI_trailerModeTelltale 0;
BA_ "Confidence" SG_ 851 UI_pcbTemperature 0;
BA_ "Confidence" SG_ 851 UI_cpuTemperature 0;
BA_ "Confidence" SG_ 991 UI_mobileAppStepCount 1;
BA_ "Confidence" SG_ 991 UI_userRequestSnapshot 1;
BA_ "Confidence" SG_ 991 UI_touchDetected 1;
BA_ "Confidence" SG_ 991 UI_validDeviceForEUSummon 1;
BA_ "Confidence" SG_ 991 UI_locatedAtHome 1;
BA_ "Confidence" SG_ 991 UI_locatedAtWork 1;
BA_ "Confidence" SG_ 991 UI_locatedAtFavorite 1;
BA_ "Confidence" SG_ 991 UI_displayInDarkMode 1;
BA_ "Confidence" SG_ 991 UI_userActivity 0;
BA_ "Confidence" SG_ 991 UI_activeTouchPoints 0;
BA_ "Confidence" SG_ 991 UI_linkState 0;
BA_ "Confidence" SG_ 991 UI_sentryModeState 1;
BA_ "GenSigSNA" SG_ 991 UI_sentryModeState "6";
BA_ "Confidence" SG_ 991 UI_autopilotSentryRequest 0;
BA_ "Confidence" SG_ 991 UI_mobileAppConnected 0;
BA_ "Confidence" SG_ 991 UI_phoneLeftInCabin 0;
BA_ "Confidence" SG_ 991 UI_autoshiftDRState 0;
BA_ "Confidence" SG_ 991 UI_wifiBtModuleType 0;
BA_ "Confidence" SG_ 991 UI_sohHealthStatus 1;
BA_ "Confidence" SG_ 991 UI_selfParkState 0;
BA_ "GenSigSNA" SG_ 991 UI_selfParkState "255";
BA_ "Confidence" SG_ 991 UI_summonDeviceIndex 0;
BA_ "Confidence" SG_ 991 UI_fullScreenMode 0;
BA_ "Confidence" SG_ 991 UI_sentryModeCameraDetection 1;
BA_ "Confidence" SG_ 991 UI_wakeOnIPActive 1;
BA_ "Confidence" SG_ 991 UI_sapActive 1;
BA_ "Confidence" SG_ 991 UI_sapClients 1;
BA_ "Confidence" SG_ 991 UI_connectivityStandbyActive 1;
BA_ "Confidence" SG_ 986 UI_wifiRegDomain 0;
BA_ "Confidence" SG_ 986 UI_wifiTethered 0;
BA_ "Confidence" SG_ 988 UI_goalLatitude 1;
BA_ "Confidence" SG_ 988 UI_goalLongitude 1;
BA_ "Confidence" SG_ 988 UI_goalOrientation 1;
BA_ "Confidence" SG_ 663 UI_adaptiveRideRequest 0;
BA_ "Confidence" SG_ 663 UI_suspensionLoweringRequest 1;
BA_ "GenSigSNA" SG_ 663 UI_suspensionLoweringRequest "3";
BA_ "Confidence" SG_ 663 UI_geofenceLevelingRequest 0;
BA_ "GenSigSNA" SG_ 663 UI_geofenceLevelingRequest "5";
BA_ "Confidence" SG_ 663 UI_jackModeToggleRequest 1;
BA_ "Confidence" SG_ 663 UI_adaptiveTuningRequest0 1;
BA_ "Confidence" SG_ 663 UI_adaptiveTuningRequest1 1;
BA_ "Confidence" SG_ 663 UI_roadRoughnessLookahead 1;
BA_ "GenSigSNA" SG_ 663 UI_roadRoughnessLookahead "127";
BA_ "Confidence" SG_ 663 UI_roadRoughnessStart 1;
BA_ "GenSigSNA" SG_ 663 UI_roadRoughnessStart "31";
BA_ "Confidence" SG_ 663 UI_mapVersionUsed 1;
BA_ "GenSigSNA" SG_ 663 UI_mapVersionUsed "255";
BA_ "Confidence" SG_ 663 UI_suspensionLevelRequest 1;
BA_ "Confidence" SG_ 661 UI_systemMonitorIndex 1;
BA_ "Confidence" SG_ 661 UI_SystemMemUsage 0;
BA_ "Confidence" SG_ 661 UI_QtCarMemUsage 0;
BA_ "Confidence" SG_ 661 UI_QtCarCPUUsage 0;
BA_ "Confidence" SG_ 661 UI_SystemCPUUsage 0;
BA_ "Confidence" SG_ 1064 UI_TCR_minRCS 1;
BA_ "Confidence" SG_ 1064 UI_TCR_maxDy 1;
BA_ "Confidence" SG_ 856 UI_TPMSMode 1;
BA_ "Confidence" SG_ 856 UI_TPMSLearnIDMode 1;
BA_ "Confidence" SG_ 856 UI_sizeOfWheelSelect 1;
BA_ "Confidence" SG_ 952 UI_sendCalibrateTireRequest 0;
BA_ "Confidence" SG_ 952 UI_setRCPFront 1;
BA_ "Confidence" SG_ 952 UI_setRCPRear 1;
BA_ "Confidence" SG_ 787 UI_trackModeRequest 0;
BA_ "Confidence" SG_ 787 UI_trackRotationTendency 1;
BA_ "Confidence" SG_ 787 UI_trackStabilityAssist 1;
BA_ "Confidence" SG_ 787 UI_trackPostCooling 1;
BA_ "Confidence" SG_ 787 UI_trackCmpOverclock 1;
BA_ "Confidence" SG_ 787 UI_trackModeBrakeTemps 1;
BA_ "Confidence" SG_ 787 UI_trackDrivePowerAvailability 0;
BA_ "Confidence" SG_ 787 UI_stabilityModeRequest 1;
BA_ "Confidence" SG_ 787 UI_trackModeSettingsCounter 1;
BA_ "Confidence" SG_ 787 UI_trackModeSettingsChecksum 0;
BA_ "Confidence" SG_ 1263 UI_fwHeatOnNavArrivalSOE 0;
BA_ "Confidence" SG_ 1263 UI_voyagerHeatOnNavArrivalSOE 0;
BA_ "Confidence" SG_ 130 UI_tripPlanningActive 0;
BA_ "Confidence" SG_ 130 UI_navToSupercharger 0;
BA_ "Confidence" SG_ 130 UI_navFastchargerType 0;
BA_ "Confidence" SG_ 130 UI_battPreconditionOnNavState 0;
BA_ "Confidence" SG_ 130 UI_requestActiveBatteryHeating 0;
BA_ "Confidence" SG_ 130 UI_battPreconditionOnNavPowerReq 0;
BA_ "GenSigSNA" SG_ 130 UI_battPreconditionOnNavPowerReq "127";
BA_ "Confidence" SG_ 130 UI_battPreconditionOnNavTargetT 0;
BA_ "GenSigSNA" SG_ 130 UI_battPreconditionOnNavTargetT "255";
BA_ "Confidence" SG_ 130 UI_ambientTempAtDestination 1;
BA_ "GenSigSNA" SG_ 130 UI_ambientTempAtDestination "128";
BA_ "Confidence" SG_ 130 UI_tripPlanChargingTargetPercent 1;
BA_ "GenSigSNA" SG_ 130 UI_tripPlanChargingTargetPercent "1023";
BA_ "Confidence" SG_ 130 UI_energyAtDestination 0;
BA_ "GenSigSNA" SG_ 130 UI_energyAtDestination "32768";
BA_ "Confidence" SG_ 139 UI_maxSpeedToReachDestination 0;
BA_ "GenSigSNA" SG_ 139 UI_maxSpeedToReachDestination "65535";
BA_ "Confidence" SG_ 139 UI_remainingWeightedRMSSpeed 1;
BA_ "GenSigSNA" SG_ 139 UI_remainingWeightedRMSSpeed "65535";
BA_ "Confidence" SG_ 139 UI_timeToDestination 0;
BA_ "GenSigSNA" SG_ 139 UI_timeToDestination "65535";
BA_ "Confidence" SG_ 1173 UI_predictedEnergy 0;
BA_ "GenSigSNA" SG_ 1173 UI_predictedEnergy "32768";
BA_ "Confidence" SG_ 1173 UI_predictedEnergyLearned 1;
BA_ "GenSigSNA" SG_ 1173 UI_predictedEnergyLearned "32768";
BA_ "Confidence" SG_ 1173 UI_hindsightEnergy 0;
BA_ "GenSigSNA" SG_ 1173 UI_hindsightEnergy "32768";
BA_ "Confidence" SG_ 1173 UI_hindsightEnergyLearned 1;
BA_ "GenSigSNA" SG_ 1173 UI_hindsightEnergyLearned "32768";
BA_ "Confidence" SG_ 1174 UI_longTermEnergyModelError 1;
BA_ "GenSigSNA" SG_ 1174 UI_longTermEnergyModelError "128";
BA_ "Confidence" SG_ 1174 UI_longTermRmsSpeedRatio 1;
BA_ "GenSigSNA" SG_ 1174 UI_longTermRmsSpeedRatio "255";
BA_ "Confidence" SG_ 1174 UI_gradeCorrectedEnergy 1;
BA_ "GenSigSNA" SG_ 1174 UI_gradeCorrectedEnergy "32768";
BA_ "Confidence" SG_ 1174 UI_gradeCorrectedEnergyLearned 1;
BA_ "GenSigSNA" SG_ 1174 UI_gradeCorrectedEnergyLearned "32768";
BA_ "Confidence" SG_ 1175 UI_battPreconditionOnNavTime 1;
BA_ "GenSigSNA" SG_ 1175 UI_battPreconditionOnNavTime "65535";
BA_ "Confidence" SG_ 1175 UI_maxBattPreconditionOnNavTime 1;
BA_ "GenSigSNA" SG_ 1175 UI_maxBattPreconditionOnNavTime "65535";
BA_ "Confidence" SG_ 850 UI_centerDisplayRunning 0;
BA_ "Confidence" SG_ 850 UI_centerDisplaySM 1;
BA_ "Confidence" SG_ 850 UI_centerDisplayPowerOn 0;
BA_ "Confidence" SG_ 850 UI_autonomyCenterDispStatus 1;
BA_ "GenSigSNA" SG_ 850 UI_autonomyCenterDispStatus "0";
BA_ "Confidence" SG_ 850 UI_autonomyRearDispStatus 1;
BA_ "GenSigSNA" SG_ 850 UI_autonomyRearDispStatus "0";
BA_ "Confidence" SG_ 850 UI_autonomyConnectivityStatus 1;
BA_ "GenSigSNA" SG_ 850 UI_autonomyConnectivityStatus "0";
BA_ "Confidence" SG_ 850 UI_autonomyQtCarStatus 1;
BA_ "GenSigSNA" SG_ 850 UI_autonomyQtCarStatus "0";
BA_ "Confidence" SG_ 850 UI_autonomyQtCarRearStatus 1;
BA_ "GenSigSNA" SG_ 850 UI_autonomyQtCarRearStatus "0";
BA_ "Confidence" SG_ 850 UI_autonomyDASServerStatus 1;
BA_ "GenSigSNA" SG_ 850 UI_autonomyDASServerStatus "0";
BA_ "Confidence" SG_ 850 UI_rearDisplayRunning 0;
BA_ "Confidence" SG_ 850 UI_rearDisplayPowerOn 0;
BA_ "Confidence" SG_ 850 UI_rearDisplaySM 1;
BA_ "Confidence" SG_ 1827 UI_ussSensorIdX 1;
BA_ "Confidence" SG_ 1829 UI_ussSensorIdY 1;
BA_ "Confidence" SG_ 627 UI_powerStateRequest 0;
BA_ "Confidence" SG_ 627 UI_childDoorLockOnRight 0;
BA_ "Confidence" SG_ 627 UI_frontFogSwitch 0;
BA_ "Confidence" SG_ 627 UI_summonActive 0;
BA_ "Confidence" SG_ 627 UI_frunkRequest 0;
BA_ "Confidence" SG_ 627 UI_wiperMode 0;
BA_ "GenSigSNA" SG_ 627 UI_wiperMode "0";
BA_ "Confidence" SG_ 627 UI_steeringBacklightEnabled 1;
BA_ "Confidence" SG_ 627 UI_steeringButtonMode 0;
BA_ "Confidence" SG_ 627 UI_walkUpUnlock 0;
BA_ "Confidence" SG_ 627 UI_walkAwayLock 0;
BA_ "Confidence" SG_ 627 UI_unlockOnPark 0;
BA_ "Confidence" SG_ 627 UI_globalUnlockOn 0;
BA_ "Confidence" SG_ 627 UI_childDoorLockOnLeft 0;
BA_ "Confidence" SG_ 627 UI_lockRequest 0;
BA_ "GenSigSNA" SG_ 627 UI_lockRequest "7";
BA_ "Confidence" SG_ 627 UI_alarmEnabled 0;
BA_ "Confidence" SG_ 627 UI_intrusionSensorOn 1;
BA_ "Confidence" SG_ 627 UI_stop12vSupport 0;
BA_ "Confidence" SG_ 627 UI_rearFogSwitch 0;
BA_ "Confidence" SG_ 627 UI_mirrorFoldRequest 0;
BA_ "GenSigSNA" SG_ 627 UI_mirrorFoldRequest "3";
BA_ "Confidence" SG_ 627 UI_mirrorHeatRequest 0;
BA_ "Confidence" SG_ 627 UI_remoteStartRequest 0;
BA_ "GenSigSNA" SG_ 627 UI_remoteStartRequest "4";
BA_ "Confidence" SG_ 627 UI_seeYouHomeLightingOn 0;
BA_ "Confidence" SG_ 627 UI_powerOff 0;
BA_ "Confidence" SG_ 627 UI_displayBrightnessLevel 0;
BA_ "GenSigSNA" SG_ 627 UI_displayBrightnessLevel "255";
BA_ "Confidence" SG_ 627 UI_ambientLightingEnabled 1;
BA_ "Confidence" SG_ 627 UI_autoHighBeamEnabled 0;
BA_ "Confidence" SG_ 627 UI_frontLeftSeatHeatReq 0;
BA_ "Confidence" SG_ 627 UI_frontRightSeatHeatReq 0;
BA_ "Confidence" SG_ 627 UI_rearLeftSeatHeatReq 0;
BA_ "Confidence" SG_ 627 UI_rearCenterSeatHeatReq 0;
BA_ "Confidence" SG_ 627 UI_rearRightSeatHeatReq 0;
BA_ "Confidence" SG_ 627 UI_autoFoldMirrorsOn 0;
BA_ "Confidence" SG_ 627 UI_mirrorDipOnReverse 0;
BA_ "Confidence" SG_ 627 UI_remoteClosureRequest 0;
BA_ "GenSigSNA" SG_ 627 UI_remoteClosureRequest "3";
BA_ "Confidence" SG_ 627 UI_wiperRequest 0;
BA_ "GenSigSNA" SG_ 627 UI_wiperRequest "0";
BA_ "Confidence" SG_ 627 UI_domeLightSwitch 0;
BA_ "Confidence" SG_ 627 UI_honkHorn 1;
BA_ "Confidence" SG_ 627 UI_driveStateRequest 1;
BA_ "Confidence" SG_ 627 UI_rearWindowLockout 1;
BA_ "Confidence" SG_ 947 UI_gloveboxRequest 0;
BA_ "Confidence" SG_ 947 UI_trunkRequest 0;
BA_ "Confidence" SG_ 947 UI_UMCUpdateInhibit 1;
BA_ "Confidence" SG_ 947 UI_WCUpdateInhibit 1;
BA_ "Confidence" SG_ 947 UI_soundHornOnLock 1;
BA_ "Confidence" SG_ 947 UI_locksPanelActive 1;
BA_ "Confidence" SG_ 947 UI_PINToDriveEnabled 0;
BA_ "Confidence" SG_ 947 UI_PINToDrivePassed 0;
BA_ "Confidence" SG_ 947 UI_disableMirrorAutoDim 0;
BA_ "Confidence" SG_ 947 UI_lightSwitch 0;
BA_ "GenSigSNA" SG_ 947 UI_lightSwitch "4";
BA_ "Confidence" SG_ 947 UI_readyToAddKey 0;
BA_ "Confidence" SG_ 947 UI_alarmTriggerRequest 0;
BA_ "Confidence" SG_ 947 UI_VCSECFeature1 1;
BA_ "Confidence" SG_ 947 UI_VCLEFTFeature1 1;
BA_ "Confidence" SG_ 947 UI_summonState 1;
BA_ "GenSigSNA" SG_ 947 UI_summonState "0";
BA_ "Confidence" SG_ 947 UI_displayOnForUser 0;
BA_ "Confidence" SG_ 947 UI_freeRollModeRequest 1;
BA_ "Confidence" SG_ 947 UI_BLEPushNotificationRequest 0;
BA_ "Confidence" SG_ 947 UI_pairKeyQRCodeDisplaying 1;
BA_ "Confidence" SG_ 947 UI_keepAutopilotAwake 0;
BA_ "Confidence" SG_ 947 UI_batteryPreconditioningRequest 0;
BA_ "Confidence" SG_ 947 UI_coastDownMode 1;
BA_ "Confidence" SG_ 947 UI_autopilotPowerStateRequest 0;
BA_ "Confidence" SG_ 947 UI_shorted12VCellTestMode 1;
BA_ "Confidence" SG_ 947 UI_autoRollWindowsOnLockEnable 0;
BA_ "Confidence" SG_ 947 UI_virtualPitchSensorOverrideOKF 1;
BA_ "SystemSignalLongSymbol" SG_ 947 UI_virtualPitchSensorOverrideOKF "UI_virtualPitchSensorOverrideOKForAim";
BA_ "Confidence" SG_ 947 UI_conditionalLoggingEnabledVCSE 1;
BA_ "SystemSignalLongSymbol" SG_ 947 UI_conditionalLoggingEnabledVCSE "UI_conditionalLoggingEnabledVCSEC";
BA_ "Confidence" SG_ 947 UI_WC3UpdateInhibit 1;
BA_ "Confidence" SG_ 947 UI_steeringWheelHeatReq 0;
BA_ "Confidence" SG_ 947 UI_disableHorn 0;
BA_ "Confidence" SG_ 947 UI_frontLeftSeatFanReq 0;
BA_ "Confidence" SG_ 947 UI_frontRightSeatAutoClimateReq 0;
BA_ "Confidence" SG_ 947 UI_frontRightSeatFanReq 0;
BA_ "Confidence" SG_ 947 UI_3RLeftSeatHeatReq 0;
BA_ "Confidence" SG_ 947 UI_3RRightSeatHeatReq 0;
BA_ "Confidence" SG_ 947 UI_sleepFeature1 1;
BA_ "Confidence" SG_ 947 UI_dcr12VThreshold 1;
BA_ "Confidence" SG_ 947 UI_frontLeftSeatAutoClimateReq 0;
BA_ "Confidence" SG_ 947 UI_wiperHeaterReq 0;
BA_ "Confidence" SG_ 947 UI_tireSeason 1;
BA_ "Confidence" SG_ 947 UI_saveTireConfigReq 1;
BA_ "Confidence" SG_ 947 UI_silentAlarm 0;
BA_ "Confidence" SG_ 947 UI_sleepFeature2 1;
BA_ "Confidence" SG_ 628 UI_lightFlashRequest 0;
BA_ "Confidence" SG_ 628 UI_keylessDrivingEnabled 1;
BA_ "Confidence" SG_ 628 UI_phoneCallActive 0;
BA_ "Confidence" SG_ 628 UI_drivingSideVEH 1;
BA_ "Confidence" SG_ 628 UI_keyPairResponse 1;
BA_ "Confidence" SG_ 628 UI_lightShowClosuresEnabled 0;
BA_ "Confidence" SG_ 628 UI_steeringWheelHeatAutoReq 0;
BA_ "Confidence" SG_ 628 UI_steeringWheelHeatLevelReq 0;
BA_ "Confidence" SG_ 628 UI_headlightPulseRequest 0;
BA_ "Confidence" SG_ 628 UI_VCSECFeature2 1;
BA_ "Confidence" SG_ 628 UI_VCSECFeature3 1;
BA_ "Confidence" SG_ 628 UI_VCSECFeature4 1;
BA_ "Confidence" SG_ 628 UI_VCSECFeature5 1;
BA_ "Confidence" SG_ 628 UI_shortHornRequest 1;
BA_ "Confidence" SG_ 628 UI_packTempLoggingRequest 1;
BA_ "Confidence" SG_ 628 UI_UMC3UpdateInhibit 1;
BA_ "Confidence" SG_ 628 UI_handsFreeTrunk 1;
BA_ "Confidence" SG_ 628 UI_displayRedShiftActive 0;
BA_ "Confidence" SG_ 628 UI_handsFreeFrunk 1;
BA_ "Confidence" SG_ 628 UI_fasciaCameraWashRequest 0;
BA_ "Confidence" SG_ 628 UI_autoClosuresExcludeHome 1;
BA_ "Confidence" SG_ 628 UI_leftRearSeatAdjustmentRequest 0;
BA_ "Confidence" SG_ 628 UI_rightRearSeatAdjustmentReques 0;
BA_ "SystemSignalLongSymbol" SG_ 628 UI_rightRearSeatAdjustmentReques "UI_rightRearSeatAdjustmentRequest";
BA_ "Confidence" SG_ 628 UI_blindSpotIndicatorLightReques 0;
BA_ "SystemSignalLongSymbol" SG_ 628 UI_blindSpotIndicatorLightReques "UI_blindSpotIndicatorLightRequest";
BA_ "Confidence" SG_ 628 UI_etcBluetoothControl 1;
BA_ "Confidence" SG_ 628 UI_keepOnAccessoryPortsReq 0;
BA_ "Confidence" SG_ 628 UI_fasciaCameraShown 0;
BA_ "Confidence" SG_ 628 UI_rearSeatChildLock 0;
BA_ "Confidence" SG_ 628 UI_windowPercentageRequest 0;
BA_ "Confidence" SG_ 628 UI_windowRequestedFL 0;
BA_ "Confidence" SG_ 628 UI_windowRequestedFR 0;
BA_ "Confidence" SG_ 628 UI_windowRequestedRL 0;
BA_ "Confidence" SG_ 628 UI_windowRequestedRR 0;
BA_ "Confidence" SG_ 628 UI_windowRequest 0;
BA_ "Confidence" SG_ 628 UI_closeTrunkRequest 0;
BA_ "Confidence" SG_ 628 UI_childPresenceDetectionDisable 0;
BA_ "SystemSignalLongSymbol" SG_ 628 UI_childPresenceDetectionDisable "UI_childPresenceDetectionDisableRequest";
BA_ "Confidence" SG_ 628 UI_V2LAUpdateInhibit 1;
BA_ "Confidence" SG_ 628 UI_userPresenceDetectionEnabled 1;
BA_ "Confidence" SG_ 628 UI_derivedLoadshedFeature 0;
BA_ "Confidence" SG_ 628 UI_rearSeatFoldConfirmed 1;
BA_ "Confidence" SG_ 628 UI_leftRearSeatRequestFromRearDi 1;
BA_ "SystemSignalLongSymbol" SG_ 628 UI_leftRearSeatRequestFromRearDi "UI_leftRearSeatRequestFromRearDisplay";
BA_ "Confidence" SG_ 628 UI_selfParkStandingBy 0;
BA_ "Confidence" SG_ 628 UI_rightRearSeatRequestFromRearD 1;
BA_ "SystemSignalLongSymbol" SG_ 628 UI_rightRearSeatRequestFromRearD "UI_rightRearSeatRequestFromRearDisplay";
BA_ "Confidence" SG_ 1193 UI_firstRowLeftDomeLightRequest 0;
BA_ "Confidence" SG_ 1193 UI_firstRowRightDomeLightRequest 0;
BA_ "Confidence" SG_ 1193 UI_secondRowLeftDomeLightRequest 0;
BA_ "Confidence" SG_ 1193 UI_secondRowCenterDomeLightReque 0;
BA_ "SystemSignalLongSymbol" SG_ 1193 UI_secondRowCenterDomeLightReque "UI_secondRowCenterDomeLightRequest";
BA_ "Confidence" SG_ 1193 UI_secondRowRightDomeLightReques 0;
BA_ "SystemSignalLongSymbol" SG_ 1193 UI_secondRowRightDomeLightReques "UI_secondRowRightDomeLightRequest";
BA_ "Confidence" SG_ 1193 UI_thirdRowLeftDomeLightRequest 0;
BA_ "Confidence" SG_ 1193 UI_thirdRowRightDomeLightRequest 0;
BA_ "Confidence" SG_ 853 UI_coolantFlowRequest 0;
BA_ "Confidence" SG_ 853 UI_inletActiveCoolTarget 3;
BA_ "Confidence" SG_ 853 UI_disableHVPTThermalLoads 0;
BA_ "Confidence" SG_ 853 UI_enableCompLiquidPumpOut 1;
BA_ "Confidence" SG_ 853 UI_enableCOP1HighSHOperation 1;
BA_ "Confidence" SG_ 853 UI_enableIncreasedEvapRampRate 1;
BA_ "Confidence" SG_ 853 UI_enableCOP1BatteryHeating 1;
BA_ "Confidence" SG_ 853 UI_enableCOP1CabinHeatingBattery 1;
BA_ "SystemSignalLongSymbol" SG_ 853 UI_enableCOP1CabinHeatingBattery "UI_enableCOP1CabinHeatingBatteryHeating";
BA_ "Confidence" SG_ 853 UI_enableLouverAutoDetection 1;
BA_ "Confidence" SG_ 853 UI_enableUserFacingLowFlowDelive 1;
BA_ "SystemSignalLongSymbol" SG_ 853 UI_enableUserFacingLowFlowDelive "UI_enableUserFacingLowFlowDeliveryAlert";
BA_ "Confidence" SG_ 853 UI_disableHvacCameraOnlyDefog 1;
BA_ "Confidence" SG_ 853 UI_enableEXVFastCalibration 1;
BA_ "Confidence" SG_ 853 UI_enableThermalDriverlessSelfTe 1;
BA_ "SystemSignalLongSymbol" SG_ 853 UI_enableThermalDriverlessSelfTe "UI_enableThermalDriverlessSelfTest";
BA_ "Confidence" SG_ 853 UI_enableCoolantDasTarget 1;
BA_ "Confidence" SG_ 853 UI_geofencedLiftgateHeight 1;
BA_ "GenSigSNA" SG_ 853 UI_geofencedLiftgateHeight "255";
BA_ "Confidence" SG_ 853 UI_convenienceFeatureLimit 0;
BA_ "Confidence" SG_ 853 UI_allowConvenienceFeatures 0;
BA_ "Confidence" SG_ 853 UI_enableConservativeBatteryHeat 1;
BA_ "SystemSignalLongSymbol" SG_ 853 UI_enableConservativeBatteryHeat "UI_enableConservativeBatteryHeating";
BA_ "Confidence" SG_ 853 UI_enableDefaultApTempTarget 1;
BA_ "Confidence" SG_ 853 UI_enableHVACCompressorWasteHeat 1;
BA_ "Confidence" SG_ 853 UI_disablePhoneChargingPads 0;
BA_ "Confidence" SG_ 853 UI_isAtTeslaFacility 1;
BA_ "Confidence" SG_ 853 UI_enableThermalPowerBudget 1;
BA_ "Confidence" SG_ 853 UI_enableHVACAPFanHeaterControl 1;
BA_ "Confidence" SG_ 853 UI_enableAutopilotAirPurge 1;
BA_ "Confidence" SG_ 853 UI_enableForcedAirCameraHeater 1;
BA_ "Confidence" SG_ 853 UI_enableHvacCOPOnUndeliveredVeh 1;
BA_ "Confidence" SG_ 644 UI_factoryMode 1;
BA_ "Confidence" SG_ 644 UI_transportMode 0;
BA_ "Confidence" SG_ 644 UI_showroomMode 0;
BA_ "Confidence" SG_ 644 UI_serviceMode 0;
BA_ "Confidence" SG_ 644 UI_isDelivered 1;
BA_ "Confidence" SG_ 644 UI_hasEverBeenDelivered 1;
BA_ "Confidence" SG_ 644 UI_homelinkV2Command0 1;
BA_ "Confidence" SG_ 644 UI_homelinkV2Command1 1;
BA_ "Confidence" SG_ 644 UI_homelinkV2Command2 1;
BA_ "Confidence" SG_ 644 UI_carWashMode 0;
BA_ "Confidence" SG_ 644 UI_valetMode 1;
BA_ "Confidence" SG_ 644 UI_gameMode 0;
BA_ "Confidence" SG_ 644 UI_diagnosticsAllowed 1;
BA_ "Confidence" SG_ 644 UI_serviceModePlus 0;
BA_ "Confidence" SG_ 644 UI_premiumAmpPowerOff 0;
BA_ "Confidence" SG_ 644 UI_signedCmdHardLocked 1;
BA_ "Confidence" SG_ 644 UI_signedCmdServiceMode 1;
BA_ "Confidence" SG_ 644 UI_closureEasterEggStatus 1;
BA_ "Confidence" SG_ 644 UI_lightShowType 0;
BA_ "Confidence" SG_ 644 UI_sohTestRequest 1;
BA_ "Confidence" SG_ 644 UI_upkeepMode 0;
BA_ "Confidence" SG_ 644 UI_vehicleModesCounter 1;
BA_ "Confidence" SG_ 644 UI_vehicleModesChecksum 0;
BA_ "Confidence" SG_ 595 UI_ventPanelControlRequestIndex 1;
BA_ "Confidence" SG_ 595 UI_ventPanelLeftPositionX 0;
BA_ "Confidence" SG_ 595 UI_ventPanelLeftPositionY 0;
BA_ "Confidence" SG_ 595 UI_ventPanelLeftLateralSplit 0;
BA_ "Confidence" SG_ 595 UI_ventPanelRightPositionX 0;
BA_ "Confidence" SG_ 595 UI_ventPanelRightPositionY 0;
BA_ "Confidence" SG_ 595 UI_ventPanelRightLateralSplit 0;
BA_ "Confidence" SG_ 595 UI_ventPanelLeftLateralMode 0;
BA_ "Confidence" SG_ 595 UI_ventPanelRightLateralMode 0;
BA_ "Confidence" SG_ 595 UI_hvacReqActiveVents 0;
BA_ "Confidence" SG_ 595 UI_vent2RLeftPositionX 0;
BA_ "Confidence" SG_ 595 UI_vent2RLeftPositionY 0;
BA_ "Confidence" SG_ 595 UI_vent2RRightPositionX 0;
BA_ "Confidence" SG_ 595 UI_vent2RRightPositionY 0;
BA_ "Confidence" SG_ 595 UI_hvacReqThirdRowState 0;
BA_ "Confidence" SG_ 1569 UI_weatherSvcTimeSinceLast 1;
BA_ "GenSigSNA" SG_ 1569 UI_weatherSvcTimeSinceLast "127";
BA_ "Confidence" SG_ 1569 UI_weatherSvcWindDir 1;
BA_ "GenSigSNA" SG_ 1569 UI_weatherSvcWindDir "255";
BA_ "Confidence" SG_ 1569 UI_weatherSvcTemperature 1;
BA_ "GenSigSNA" SG_ 1569 UI_weatherSvcTemperature "255";
BA_ "Confidence" SG_ 1569 UI_weatherSvcHumidity 1;
BA_ "GenSigSNA" SG_ 1569 UI_weatherSvcHumidity "63";
BA_ "Confidence" SG_ 1569 UI_weatherSvcDewPoint 1;
BA_ "GenSigSNA" SG_ 1569 UI_weatherSvcDewPoint "255";
BA_ "Confidence" SG_ 1569 UI_weatherSvcCloudCover 1;
BA_ "GenSigSNA" SG_ 1569 UI_weatherSvcCloudCover "63";
BA_ "Confidence" SG_ 1569 UI_weatherSvcPrecipProb 1;
BA_ "GenSigSNA" SG_ 1569 UI_weatherSvcPrecipProb "63";
BA_ "Confidence" SG_ 1569 UI_weatherSvcRaining 1;
BA_ "Confidence" SG_ 1569 UI_weatherSvcSnowing 1;
BA_ "Confidence" SG_ 1569 UI_weatherSvcWindSpeed 1;
BA_ "GenSigSNA" SG_ 1569 UI_weatherSvcWindSpeed "63";
BA_ "Confidence" SG_ 1969 UI_weatherSvcForecastMuxIndex 1;
BA_ "Confidence" SG_ 1969 UI_weatherSvcForecastTempC_hour1 1;
BA_ "GenSigSNA" SG_ 1969 UI_weatherSvcForecastTempC_hour1 "255";
BA_ "Confidence" SG_ 1969 UI_weatherSvcForecastTempC_hour2 1;
BA_ "GenSigSNA" SG_ 1969 UI_weatherSvcForecastTempC_hour2 "255";
BA_ "Confidence" SG_ 1969 UI_weatherSvcForecastTempC_hour3 1;
BA_ "GenSigSNA" SG_ 1969 UI_weatherSvcForecastTempC_hour3 "255";
BA_ "Confidence" SG_ 1969 UI_weatherSvcForecastTempC_hour4 1;
BA_ "GenSigSNA" SG_ 1969 UI_weatherSvcForecastTempC_hour4 "255";
BA_ "Confidence" SG_ 1969 UI_weatherSvcForecastTempC_hour5 1;
BA_ "GenSigSNA" SG_ 1969 UI_weatherSvcForecastTempC_hour5 "255";
BA_ "Confidence" SG_ 1969 UI_weatherSvcForecastTempC_hour6 1;
BA_ "GenSigSNA" SG_ 1969 UI_weatherSvcForecastTempC_hour6 "255";
BA_ "Confidence" SG_ 1969 UI_weatherSvcForecastTempC_hour7 1;
BA_ "GenSigSNA" SG_ 1969 UI_weatherSvcForecastTempC_hour7 "255";
BA_ "Confidence" SG_ 1969 UI_weatherSvcForecastTempC_hour8 1;
BA_ "GenSigSNA" SG_ 1969 UI_weatherSvcForecastTempC_hour8 "255";
BA_ "Confidence" SG_ 1969 UI_weatherSvcForecastTempC_hour9 1;
BA_ "GenSigSNA" SG_ 1969 UI_weatherSvcForecastTempC_hour9 "255";
BA_ "Confidence" SG_ 1969 UI_weatherSvcForecastTempC__0001 1;
BA_ "GenSigSNA" SG_ 1969 UI_weatherSvcForecastTempC__0001 "255";
BA_ "SystemSignalLongSymbol" SG_ 1969 UI_weatherSvcForecastTempC__0001 "UI_weatherSvcForecastTempC_hour10";
BA_ "Confidence" SG_ 1969 UI_weatherSvcForecastTempC__0002 1;
BA_ "GenSigSNA" SG_ 1969 UI_weatherSvcForecastTempC__0002 "255";
BA_ "SystemSignalLongSymbol" SG_ 1969 UI_weatherSvcForecastTempC__0002 "UI_weatherSvcForecastTempC_hour11";
BA_ "Confidence" SG_ 1969 UI_weatherSvcForecastHumidity_ho 1;
BA_ "GenSigSNA" SG_ 1969 UI_weatherSvcForecastHumidity_ho "63";
BA_ "SystemSignalLongSymbol" SG_ 1969 UI_weatherSvcForecastHumidity_ho "UI_weatherSvcForecastHumidity_hour1";
BA_ "Confidence" SG_ 1969 UI_weatherSvcForecastHumidi_0003 1;
BA_ "GenSigSNA" SG_ 1969 UI_weatherSvcForecastHumidi_0003 "63";
BA_ "SystemSignalLongSymbol" SG_ 1969 UI_weatherSvcForecastHumidi_0003 "UI_weatherSvcForecastHumidity_hour2";
BA_ "Confidence" SG_ 1969 UI_weatherSvcForecastHumidi_0004 1;
BA_ "GenSigSNA" SG_ 1969 UI_weatherSvcForecastHumidi_0004 "63";
BA_ "SystemSignalLongSymbol" SG_ 1969 UI_weatherSvcForecastHumidi_0004 "UI_weatherSvcForecastHumidity_hour3";
BA_ "Confidence" SG_ 1969 UI_weatherSvcForecastHumidi_0005 1;
BA_ "GenSigSNA" SG_ 1969 UI_weatherSvcForecastHumidi_0005 "63";
BA_ "SystemSignalLongSymbol" SG_ 1969 UI_weatherSvcForecastHumidi_0005 "UI_weatherSvcForecastHumidity_hour4";
BA_ "Confidence" SG_ 1969 UI_weatherSvcForecastHumidi_0006 1;
BA_ "GenSigSNA" SG_ 1969 UI_weatherSvcForecastHumidi_0006 "63";
BA_ "SystemSignalLongSymbol" SG_ 1969 UI_weatherSvcForecastHumidi_0006 "UI_weatherSvcForecastHumidity_hour5";
BA_ "Confidence" SG_ 1969 UI_weatherSvcForecastHumidi_0007 1;
BA_ "GenSigSNA" SG_ 1969 UI_weatherSvcForecastHumidi_0007 "63";
BA_ "SystemSignalLongSymbol" SG_ 1969 UI_weatherSvcForecastHumidi_0007 "UI_weatherSvcForecastHumidity_hour6";
BA_ "Confidence" SG_ 1969 UI_weatherSvcForecastHumidi_0008 1;
BA_ "GenSigSNA" SG_ 1969 UI_weatherSvcForecastHumidi_0008 "63";
BA_ "SystemSignalLongSymbol" SG_ 1969 UI_weatherSvcForecastHumidi_0008 "UI_weatherSvcForecastHumidity_hour7";
BA_ "Confidence" SG_ 1969 UI_weatherSvcForecastHumidi_0009 1;
BA_ "GenSigSNA" SG_ 1969 UI_weatherSvcForecastHumidi_0009 "63";
BA_ "SystemSignalLongSymbol" SG_ 1969 UI_weatherSvcForecastHumidi_0009 "UI_weatherSvcForecastHumidity_hour8";
BA_ "Confidence" SG_ 1969 UI_weatherSvcForecastHumidi_0010 1;
BA_ "GenSigSNA" SG_ 1969 UI_weatherSvcForecastHumidi_0010 "63";
BA_ "SystemSignalLongSymbol" SG_ 1969 UI_weatherSvcForecastHumidi_0010 "UI_weatherSvcForecastHumidity_hour9";
BA_ "Confidence" SG_ 1969 UI_weatherSvcForecastHumidi_0001 1;
BA_ "GenSigSNA" SG_ 1969 UI_weatherSvcForecastHumidi_0001 "63";
BA_ "SystemSignalLongSymbol" SG_ 1969 UI_weatherSvcForecastHumidi_0001 "UI_weatherSvcForecastHumidity_hour10";
BA_ "Confidence" SG_ 1969 UI_weatherSvcForecastHumidi_0002 1;
BA_ "GenSigSNA" SG_ 1969 UI_weatherSvcForecastHumidi_0002 "63";
BA_ "SystemSignalLongSymbol" SG_ 1969 UI_weatherSvcForecastHumidi_0002 "UI_weatherSvcForecastHumidity_hour11";
BA_ "Confidence" SG_ 1969 UI_weatherSvcForecastWindSpeedKp 1;
BA_ "GenSigSNA" SG_ 1969 UI_weatherSvcForecastWindSpeedKp "63";
BA_ "SystemSignalLongSymbol" SG_ 1969 UI_weatherSvcForecastWindSpeedKp "UI_weatherSvcForecastWindSpeedKph_hour1";
BA_ "Confidence" SG_ 1969 UI_weatherSvcForecastWindSp_0003 1;
BA_ "GenSigSNA" SG_ 1969 UI_weatherSvcForecastWindSp_0003 "63";
BA_ "SystemSignalLongSymbol" SG_ 1969 UI_weatherSvcForecastWindSp_0003 "UI_weatherSvcForecastWindSpeedKph_hour2";
BA_ "Confidence" SG_ 1969 UI_weatherSvcForecastWindSp_0004 1;
BA_ "GenSigSNA" SG_ 1969 UI_weatherSvcForecastWindSp_0004 "63";
BA_ "SystemSignalLongSymbol" SG_ 1969 UI_weatherSvcForecastWindSp_0004 "UI_weatherSvcForecastWindSpeedKph_hour3";
BA_ "Confidence" SG_ 1969 UI_weatherSvcForecastWindSp_0005 1;
BA_ "GenSigSNA" SG_ 1969 UI_weatherSvcForecastWindSp_0005 "63";
BA_ "SystemSignalLongSymbol" SG_ 1969 UI_weatherSvcForecastWindSp_0005 "UI_weatherSvcForecastWindSpeedKph_hour4";
BA_ "Confidence" SG_ 1969 UI_weatherSvcForecastWindSp_0006 1;
BA_ "GenSigSNA" SG_ 1969 UI_weatherSvcForecastWindSp_0006 "63";
BA_ "SystemSignalLongSymbol" SG_ 1969 UI_weatherSvcForecastWindSp_0006 "UI_weatherSvcForecastWindSpeedKph_hour5";
BA_ "Confidence" SG_ 1969 UI_weatherSvcForecastWindSp_0007 1;
BA_ "GenSigSNA" SG_ 1969 UI_weatherSvcForecastWindSp_0007 "63";
BA_ "SystemSignalLongSymbol" SG_ 1969 UI_weatherSvcForecastWindSp_0007 "UI_weatherSvcForecastWindSpeedKph_hour6";
BA_ "Confidence" SG_ 1969 UI_weatherSvcForecastWindSp_0008 1;
BA_ "GenSigSNA" SG_ 1969 UI_weatherSvcForecastWindSp_0008 "63";
BA_ "SystemSignalLongSymbol" SG_ 1969 UI_weatherSvcForecastWindSp_0008 "UI_weatherSvcForecastWindSpeedKph_hour7";
BA_ "Confidence" SG_ 1969 UI_weatherSvcForecastWindSp_0009 1;
BA_ "GenSigSNA" SG_ 1969 UI_weatherSvcForecastWindSp_0009 "63";
BA_ "SystemSignalLongSymbol" SG_ 1969 UI_weatherSvcForecastWindSp_0009 "UI_weatherSvcForecastWindSpeedKph_hour8";
BA_ "Confidence" SG_ 1969 UI_weatherSvcForecastWindSp_0010 1;
BA_ "GenSigSNA" SG_ 1969 UI_weatherSvcForecastWindSp_0010 "63";
BA_ "SystemSignalLongSymbol" SG_ 1969 UI_weatherSvcForecastWindSp_0010 "UI_weatherSvcForecastWindSpeedKph_hour9";
BA_ "Confidence" SG_ 1969 UI_weatherSvcForecastWindSp_0001 1;
BA_ "GenSigSNA" SG_ 1969 UI_weatherSvcForecastWindSp_0001 "63";
BA_ "SystemSignalLongSymbol" SG_ 1969 UI_weatherSvcForecastWindSp_0001 "UI_weatherSvcForecastWindSpeedKph_hour10";
BA_ "Confidence" SG_ 1969 UI_weatherSvcForecastWindSp_0002 1;
BA_ "GenSigSNA" SG_ 1969 UI_weatherSvcForecastWindSp_0002 "63";
BA_ "SystemSignalLongSymbol" SG_ 1969 UI_weatherSvcForecastWindSp_0002 "UI_weatherSvcForecastWindSpeedKph_hour11";
BA_ "Confidence" SG_ 1533 UMC_alertID 1;
BA_ "Confidence" SG_ 1533 UMC_alertType 1;
BA_ "Confidence" SG_ 1533 UMC_a001_groundImpedance 1;
BA_ "Confidence" SG_ 1533 UMC_a002_ccidRmsCurrent 1;
BA_ "Confidence" SG_ 1533 UMC_a002_ccidRmsCurrentAvg 1;
BA_ "Confidence" SG_ 1533 UMC_a002_ccidDCGfciCurrent 1;
BA_ "Confidence" SG_ 1533 UMC_a002_ccidFaultReason 1;
BA_ "GenSigSNA" SG_ 1533 UMC_a002_ccidFaultReason "0";
BA_ "Confidence" SG_ 1533 UMC_a003_faultType 1;
BA_ "Confidence" SG_ 1533 UMC_a003_ccidSelfTestDuty 1;
BA_ "Confidence" SG_ 1533 UMC_a003_ccidSelfTestCurrent 1;
BA_ "Confidence" SG_ 1533 UMC_a004_lineVoltage 1;
BA_ "Confidence" SG_ 1533 UMC_a004_inputVoltage 1;
BA_ "Confidence" SG_ 1533 UMC_a004_inputNeutralVoltage 1;
BA_ "Confidence" SG_ 1533 UMC_a005_lineVoltage 1;
BA_ "Confidence" SG_ 1533 UMC_a005_inputVoltage 1;
BA_ "Confidence" SG_ 1533 UMC_a005_inputNeutralVoltage 1;
BA_ "Confidence" SG_ 1533 UMC_a006_outputVoltage 1;
BA_ "Confidence" SG_ 1533 UMC_a006_faultType 1;
BA_ "Confidence" SG_ 1533 UMC_a006_umcReceptacleVoltage 1;
BA_ "Confidence" SG_ 1533 UMC_a006_handleVoltage 1;
BA_ "Confidence" SG_ 1533 UMC_a007_pcbaTemp 1;
BA_ "Confidence" SG_ 1533 UMC_a008_wallPlugTemp 1;
BA_ "Confidence" SG_ 1533 UMC_a008_SA_current 1;
BA_ "Confidence" SG_ 1533 UMC_a009_vehConnTemp 1;
BA_ "Confidence" SG_ 1533 UMC_a010_inputTerminalsTemp 1;
BA_ "Confidence" SG_ 1533 UMC_a012_pilotHigh 1;
BA_ "Confidence" SG_ 1533 UMC_a012_pilotLow 1;
BA_ "Confidence" SG_ 1533 UMC_a013_SA_current 1;
BA_ "Confidence" SG_ 1533 UMC_a015_SA_current 1;
BA_ "Confidence" SG_ 1533 UMC_a016_pcbaTemp 1;
BA_ "Confidence" SG_ 1533 UMC_a017_wallPlugTemp 1;
BA_ "Confidence" SG_ 1533 UMC_a017_SA_current 1;
BA_ "Confidence" SG_ 1533 UMC_a018_vehConnTemp 1;
BA_ "Confidence" SG_ 1533 UMC_a019_inputTerminalsTemp 1;
BA_ "Confidence" SG_ 1533 UMC_a024_groundImpedance 1;
BA_ "Confidence" SG_ 1533 UMC_a040_groundImpedance 1;
BA_ "Confidence" SG_ 1285 SA_infoIndex 1;
BA_ "Confidence" SG_ 1285 SA_genealogyVersion 0;
BA_ "Confidence" SG_ 1285 SA_genealogyCrc 0;
BA_ "Confidence" SG_ 1285 SA_region 0;
BA_ "Confidence" SG_ 1285 SA_OverTempThreshold 0;
BA_ "Confidence" SG_ 1285 SA_partNumInt 0;
BA_ "Confidence" SG_ 1285 SA_partNumRev 0;
BA_ "Confidence" SG_ 1285 SA_currentLimit 0;
BA_ "Confidence" SG_ 1285 SA_l1Voltage 0;
VAL_ 666 UI_seatControlIndex 3 "3" 2 "2" 1 "1" 0 "0" ;
VAL_ 666 UI_3RSeatChildLock 3 "UI_ADJUSTABLE_FOLD_FLAT_CHILD_LOCK_BOTH" 2 "UI_ADJUSTABLE_FOLD_FLAT_CHILD_LOCK_RIGHT" 1 "UI_ADJUSTABLE_FOLD_FLAT_CHILD_LOCK_LEFT" 0 "UI_ADJUSTABLE_FOLD_FLAT_CHILD_LOCK_NONE" ;
VAL_ 666 UI_left3RowSeatAdjustmentRequest 6 "UI_ADJUSTABLE_FOLD_FLAT_REQUEST_STOP" 5 "UI_ADJUSTABLE_FOLD_FLAT_REQUEST_TOGGLE_FOLD" 4 "UI_ADJUSTABLE_FOLD_FLAT_REQUEST_REARWARD_FAST" 3 "UI_ADJUSTABLE_FOLD_FLAT_REQUEST_REARWARD_COMFORT" 2 "UI_ADJUSTABLE_FOLD_FLAT_REQUEST_FORWARD_FAST" 1 "UI_ADJUSTABLE_FOLD_FLAT_REQUEST_FORWARD_COMFORT" 0 "UI_ADJUSTABLE_FOLD_FLAT_REQUEST_NONE" ;
VAL_ 666 UI_right3RowSeatAdjustmentReques 6 "UI_ADJUSTABLE_FOLD_FLAT_REQUEST_STOP" 5 "UI_ADJUSTABLE_FOLD_FLAT_REQUEST_TOGGLE_FOLD" 4 "UI_ADJUSTABLE_FOLD_FLAT_REQUEST_REARWARD_FAST" 3 "UI_ADJUSTABLE_FOLD_FLAT_REQUEST_REARWARD_COMFORT" 2 "UI_ADJUSTABLE_FOLD_FLAT_REQUEST_FORWARD_FAST" 1 "UI_ADJUSTABLE_FOLD_FLAT_REQUEST_FORWARD_COMFORT" 0 "UI_ADJUSTABLE_FOLD_FLAT_REQUEST_NONE" ;
VAL_ 666 UI_2RLeftSeatFanReq 3 "FAN_REQUEST_LEVEL3" 2 "FAN_REQUEST_LEVEL2" 1 "FAN_REQUEST_LEVEL1" 0 "FAN_REQUEST_OFF" ;
VAL_ 666 UI_2RRightSeatFanReq 3 "FAN_REQUEST_LEVEL3" 2 "FAN_REQUEST_LEVEL2" 1 "FAN_REQUEST_LEVEL1" 0 "FAN_REQUEST_OFF" ;
VAL_ 723 UI_solarAzimuthAngle -32768 "SNA" ;
VAL_ 723 UI_solarAzimuthAngleCarRef 255 "SNA" ;
VAL_ 723 UI_isSunUp 3 "SUN_SNA" 1 "SUN_UP" 0 "SUN_DOWN" ;
VAL_ 723 UI_solarElevationAngle 127 "SNA" ;
VAL_ 563 UI_gearRequest 4 "GEAR_REQUEST_DRIVE" 3 "GEAR_REQUEST_NEUTRAL" 2 "GEAR_REQUEST_REVERSE" 1 "GEAR_REQUEST_PARK" 0 "GEAR_REQUEST_IDLE_SNA" ;
VAL_ 563 UI_autopilotRequest 1 "PRESSED" 0 "IDLE" ;
VAL_ 563 UI_gearStripLocation 1 "RIGHT" 0 "LEFT" ;
VAL_ 851 UI_autopilotTrial 3 "ACTIVE" 2 "STOP" 1 "START" 0 "NONE" ;
VAL_ 851 UI_factoryReset 3 "CUSTOMER" 2 "DIAGNOSTIC" 1 "DEVELOPER" 0 "NONE_SNA" ;
VAL_ 851 UI_cellNetworkTechnology 15 "CELL_NETWORK_SNA" 14 "CELL_NETWORK_NGRAN" 13 "CELL_NETWORK_5GSA" 12 "CELL_NETWORK_5GNSA" 11 "CELL_NETWORK_LTE5GCN" 10 "CELL_NETWORK_WCDMA" 9 "CELL_NETWORK_CDMA" 8 "CELL_NETWORK_GSM" 7 "CELL_NETWORK_LTE" 6 "CELL_NETWORK_HSPA" 5 "CELL_NETWORK_HSUPA" 4 "CELL_NETWORK_HSDPA" 3 "CELL_NETWORK_UMTS" 2 "CELL_NETWORK_EDGE" 1 "CELL_NETWORK_GPRS" 0 "CELL_NETWORK_NONE" ;
VAL_ 851 UI_cellSignalBars 7 "SNA" 5 "FIVE" 4 "FOUR" 3 "THREE" 2 "TWO" 1 "ONE" 0 "ZERO" ;
VAL_ 851 UI_trailerModeTelltale 3 "TRAILER_MODE_TELLTALE_RED" 2 "TRAILER_MODE_TELLTALE_YELLOW" 1 "TRAILER_MODE_TELLTALE_BLUE" 0 "TRAILER_MODE_TELLTALE_OFF" ;
VAL_ 991 UI_userActivity 1 "USER_ACTIVE" 0 "USER_IDLE" ;
VAL_ 991 UI_linkState 2 "LINK_STATE_WIFI" 1 "LINK_STATE_CELL" 0 "LINK_STATE_NONE" ;
VAL_ 991 UI_sentryModeState 6 "SNA" 5 "QUIET" 4 "PANIC" 3 "AWARE" 2 "ARMED" 1 "IDLE" 0 "OFF" ;
VAL_ 991 UI_mobileAppConnected 1 "CONNECTED" 0 "NOT_CONNECTED" ;
VAL_ 991 UI_autoshiftDRState 6 "AUTOSHIFT_DR_STATE_BRAKE_GEAR_SHIFT_CONFIRMED_D" 5 "AUTOSHIFT_DR_STATE_BRAKE_GEAR_SHIFT_CONFIRMED_R" 4 "AUTOSHIFT_DR_STATE_BRAKE_STEERING_AND_BRAKE_CONFIRMED" 3 "AUTOSHIFT_DR_STATE_ONLY_STEERING_CONFIRMED" 2 "AUTOSHIFT_DR_STATE_ONLY_BRAKE_CONFIRMED" 1 "AUTOSHIFT_DR_STATE_PROMPT_SHOWING_UNCONFIRMED" 0 "AUTOSHIFT_DR_STATE_INACTIVE" ;
VAL_ 991 UI_wifiBtModuleType 4 "ELEKTRA" 3 "TCU4G" 2 "BCM4359" 1 "QCA6595" 0 "UNKNOWN" ;
VAL_ 991 UI_sohHealthStatus 3 "OK" 2 "REDUCED" 1 "NO_INTERNET" 0 "UNKNOWN" ;
VAL_ 991 UI_selfParkState 255 "SNA" 52 "SELF_PARK_USER_PAUSED" 51 "SELF_PARK_REMOTE_PRE_ABORT" 50 "SELF_PARK_RESUME" 49 "SELF_PARK_PAUSE" 48 "SELF_PARK_DV_MISMATCH" 47 "SELF_PARK_DI_PANIC" 46 "SELF_PARK_POST_ACTIVE_FAILURE" 45 "SELF_PARK_POST_ACTIVE_SUCCESS" 44 "SELF_PARK_CANCEL_AUTO_SUMMON" 43 "SELF_PARK_REMOTE_ABORT" 42 "SELF_PARK_OBSTACLE_NOT_CLEARED" 41 "SELF_PARK_OBSTACLE_CLEARED" 40 "SELF_PARK_OPEN_GATE" 39 "SELF_PARK_ACTIVE" 38 "SELF_PARK_STARTED_REVERSE" 37 "SELF_PARK_STARTED_FORWARD" 36 "SELF_PARK_NOT_STARTED_TIMEOUT" 35 "SELF_PARK_PRIMED" 34 "SELF_PARK_PREPRIMED" 33 "SELF_PARK_TURN_ON_DRIVE_RAIL" 32 "SELF_PARK_DETECT_KEY_FOB" 31 "SELF_PARK_WAKE_UP_BUSES" 30 "SELF_PARK_CONNECTING_BLUETOOTH" 29 "SELF_PARK_UNAVAILABLE_CAR_WASH_MODE" 28 "SELF_PARK_UNAVAILABLE_CAR_ALARM" 27 "SELF_PARK_UNAVAILABLE_CRASH_STATE" 26 "SELF_PARK_UNAVAILABLE_DRAG_STRIP_MODE" 25 "SELF_PARK_UNAVAILABLE_TRACK_MODE" 24 "SELF_PARK_UNAVAILABLE_SERVICE_MODE" 23 "SELF_PARK_UNAVAILABLE_DOG_MODE" 22 "SELF_PARK_UNAVAILABLE_GAME_MODE" 21 "SELF_PARK_UNAVAILABLE_BLUETOOTH_CONNECT_TIMEOUT" 20 "SELF_PARK_UNAVAILABLE_WAKEUP_TIMEOUT" 19 "SELF_PARK_UNAVAILABLE_NO_BLUETOOTH_DEVICES_PAIRED" 18 "SELF_PARK_UNAVAILABLE_BRAKE_PRESSED" 17 "SELF_PARK_UNAVAILABLE_ROAD_GRADE" 16 "SELF_PARK_UNAVAILABLE_TRAILER_MODE" 15 "SELF_PARK_UNAVAILABLE_KEY_FOB_BATTERY_LOW" 14 "SELF_PARK_UNAVAILABLE_KEY_FOB_NOT_DETECTED" 13 "SELF_PARK_UNAVAILABLE_PARK_SENSOR_ISSUE" 12 "SELF_PARK_UNAVAILABLE_AUTOSTEER_NOT_ENABLED" 11 "SELF_PARK_UNAVAILABLE_LV_BUS_SUPPORT_ISSUE" 10 "SELF_PARK_UNAVAILABLE_ON_PUBLIC_ROAD" 9 "SELF_PARK_UNAVAILABLE_PARKED_TOO_LONG" 8 "SELF_PARK_UNAVAILABLE_DOOR_OPEN" 7 "SELF_PARK_UNAVAILABLE_TRUNK_OPEN" 6 "SELF_PARK_UNAVAILABLE_FRUNK_OPEN" 5 "SELF_PARK_UNAVAILABLE_PLUGGED_IN" 4 "SELF_PARK_UNAVAILABLE_NOT_PARKED" 3 "SELF_PARK_UNAVAILABLE" 2 "SELF_PARK_IDLE" 1 "SELF_PARK_DRIVING" 0 "SELF_PARK_DISABLED" ;
VAL_ 991 UI_summonDeviceIndex 3 "UNKNOWN" 2 "DEVICE_2" 1 "DEVICE_1" 0 "DEVICE_0" ;
VAL_ 986 UI_wifiRegDomain 67 "AZ" 66 "SR" 65 "SM" 64 "MS" 63 "MT" 62 "LV" 61 "LT" 60 "LI" 59 "GI" 58 "CY" 57 "AD" 56 "PT" 55 "MU" 54 "LU" 53 "EE" 52 "BG" 51 "BR" 50 "IN" 49 "IE" 48 "IS" 47 "AE" 46 "TR" 45 "ES" 44 "SI" 43 "SK" 42 "RO" 41 "PR" 40 "PL" 39 "HU" 38 "GR" 37 "FI" 36 "HR" 35 "CZ" 34 "NZ" 33 "MO" 32 "SA" 31 "PH" 30 "CO" 29 "QA" 28 "CL" 27 "MY" 26 "TH" 25 "SG" 24 "JO" 23 "MX" 22 "TW" 21 "KR" 20 "RU" 19 "GB" 18 "IL" 17 "AU" 16 "JP" 15 "HK" 14 "CN" 13 "UK" 12 "SE" 11 "CH" 10 "NO" 9 "DK" 8 "BE" 7 "AT" 6 "NL" 5 "IT" 4 "FR" 3 "DE" 2 "CA" 1 "US" 0 "UNKNOWN" ;
VAL_ 663 UI_adaptiveRideRequest 3 "ADAPTIVE_RIDE_REQUEST_ADVANCED" 2 "ADAPTIVE_RIDE_REQUEST_SPORT" 1 "ADAPTIVE_RIDE_REQUEST_AUTO" 0 "ADAPTIVE_RIDE_REQUEST_COMFORT" ;
VAL_ 663 UI_suspensionLoweringRequest 3 "SNA" 2 "AUTO" 1 "ALWAYS" 0 "NEVER" ;
VAL_ 663 UI_geofenceLevelingRequest 5 "GEOFENCE_LEVELING_REQUEST_SNA" 4 "GEOFENCE_LEVELING_REQUEST_VERY_HIGH_PERSIST" 3 "GEOFENCE_LEVELING_REQUEST_HIGH_PERSIST" 2 "GEOFENCE_LEVELING_REQUEST_VERY_HIGH_TEMPORARY" 1 "GEOFENCE_LEVELING_REQUEST_HIGH_TEMPORARY" 0 "GEOFENCE_LEVELING_REQUEST_NONE" ;
VAL_ 663 UI_jackModeToggleRequest 1 "ACTIVE" 0 "NONE" ;
VAL_ 663 UI_roadRoughnessLookahead 127 "SNA" ;
VAL_ 663 UI_roadRoughnessStart 31 "SNA" ;
VAL_ 663 UI_mapVersionUsed 255 "SNA" ;
VAL_ 663 UI_suspensionLevelRequest 7 "VERY_HIGH_LEVEL_PERSIST" 6 "HIGH_LEVEL_PERSIST" 5 "VERY_HIGH_LEVEL_TEMPORARY" 4 "HIGH_LEVEL_TEMPORARY" 3 "STANDARD_LEVEL" 2 "LOW_LEVEL" 1 "VERY_LOW_LEVEL" 0 "NONE" ;
VAL_ 661 UI_systemMonitorIndex 1 "1" 0 "0" ;
VAL_ 856 UI_TPMSMode 2 "PERFORMANCE_MODE" 1 "NORMAL_MODE" 0 "UNUSED_MODE" ;
VAL_ 856 UI_TPMSLearnIDMode 4 "AUTO_LOCATION_ACTIVE_AFTER_PWR" 3 "AUTO_LEARN_ACTIVE_AFTER_PWR" 2 "AUTO_LOCATION_ACTIVE_BY_MANUAL" 1 "AUTO_LEARN_ACTIVE_BY_MANUAL" 0 "NO_ID_LEARN_FUNCTION" ;
VAL_ 856 UI_sizeOfWheelSelect 2 "19_INCH_WHEEL" 1 "18_INCH_WHEEL" 0 "UNUSED" ;
VAL_ 787 UI_trackModeRequest 2 "TRACK_MODE_REQUEST_OFF" 1 "TRACK_MODE_REQUEST_ON" 0 "TRACK_MODE_REQUEST_IDLE" ;
VAL_ 787 UI_trackPostCooling 1 "ON" 0 "OFF" ;
VAL_ 787 UI_trackCmpOverclock 1 "ON" 0 "OFF" ;
VAL_ 787 UI_trackModeBrakeTemps 1 "ON" 0 "OFF" ;
VAL_ 787 UI_trackDrivePowerAvailability 2 "TRACK_MODE_POWER_MAX" 1 "TRACK_MODE_POWER_MIDDLE" 0 "TRACK_MODE_POWER_ENDURANCE" ;
VAL_ 787 UI_stabilityModeRequest 1 "REDUCED_REQUEST" 0 "NORMAL_REQUEST" ;
VAL_ 130 UI_navFastchargerType 4 "V4" 3 "V3" 2 "V2" 1 "LOW_POWER" 0 "NONE" ;
VAL_ 130 UI_battPreconditionOnNavState 3 "ACTIVE_COOL" 2 "PASSIVE_COOL" 1 "ACTIVE_HEAT" 0 "PASSIVE_HEAT" ;
VAL_ 130 UI_battPreconditionOnNavPowerReq 127 "SNA" 126 "MAX" -126 "MIN" ;
VAL_ 130 UI_battPreconditionOnNavTargetT 255 "SNA" 254 "MAX" 0 "MIN" ;
VAL_ 130 UI_ambientTempAtDestination -128 "SNA" ;
VAL_ 130 UI_tripPlanChargingTargetPercent 1023 "SNA" ;
VAL_ 130 UI_energyAtDestination -32767 "TRIP_TOO_LONG" -32768 "SNA" ;
VAL_ 139 UI_maxSpeedToReachDestination 65535 "SNA" 65534 "UNREACHABLE" 65533 "MAXVAL" ;
VAL_ 139 UI_remainingWeightedRMSSpeed 65535 "SNA" 65534 "MAXVAL" ;
VAL_ 139 UI_timeToDestination 65535 "SNA" 65534 "MAXVAL" ;
VAL_ 1173 UI_predictedEnergy -32767 "TRIP_TOO_LONG" -32768 "SNA" ;
VAL_ 1173 UI_predictedEnergyLearned -32767 "TRIP_TOO_LONG" -32768 "SNA" ;
VAL_ 1173 UI_hindsightEnergy -32767 "TRIP_TOO_LONG" -32768 "SNA" ;
VAL_ 1173 UI_hindsightEnergyLearned -32767 "TRIP_TOO_LONG" -32768 "SNA" ;
VAL_ 1174 UI_longTermEnergyModelError 127 "MAXVAL" -128 "SNA" ;
VAL_ 1174 UI_longTermRmsSpeedRatio 255 "SNA" 254 "MAXVAL" ;
VAL_ 1174 UI_gradeCorrectedEnergy -32767 "TRIP_TOO_LONG" -32768 "SNA" ;
VAL_ 1174 UI_gradeCorrectedEnergyLearned -32767 "TRIP_TOO_LONG" -32768 "SNA" ;
VAL_ 1175 UI_battPreconditionOnNavTime 65535 "SNA" 65534 "MAXVAL" ;
VAL_ 1175 UI_maxBattPreconditionOnNavTime 65535 "SNA" 65534 "MAXVAL" ;
VAL_ 850 UI_centerDisplaySM 4 "DOWN" 3 "TIMING_OUT" 2 "STALLING" 1 "UP" 0 "START" ;
VAL_ 850 UI_autonomyCenterDispStatus 2 "UNAVAILABLE" 1 "AVAILABLE" 0 "SNA" ;
VAL_ 850 UI_autonomyRearDispStatus 2 "UNAVAILABLE" 1 "AVAILABLE" 0 "SNA" ;
VAL_ 850 UI_autonomyConnectivityStatus 2 "OFFLINE" 1 "ONLINE" 0 "SNA" ;
VAL_ 850 UI_autonomyQtCarStatus 2 "UNAVAILABLE" 1 "AVAILABLE" 0 "SNA" ;
VAL_ 850 UI_autonomyQtCarRearStatus 2 "UNAVAILABLE" 1 "AVAILABLE" 0 "SNA" ;
VAL_ 850 UI_autonomyDASServerStatus 2 "UNAVAILABLE" 1 "AVAILABLE" 0 "SNA" ;
VAL_ 850 UI_rearDisplaySM 4 "DOWN" 3 "TIMING_OUT" 2 "STALLING" 1 "UP" 0 "START" ;
VAL_ 1827 UI_ussSensorIdX 5 "FRONT_SIDE" 4 "FRONT_CORNER" 3 "FRONT_INNER" 2 "REAR_SIDE" 1 "REAR_CORNER" 0 "REAR_INNER" ;
VAL_ 1829 UI_ussSensorIdY 5 "FRONT_SIDE" 4 "FRONT_CORNER" 3 "FRONT_INNER" 2 "REAR_SIDE" 1 "REAR_CORNER" 0 "REAR_INNER" ;
VAL_ 627 UI_powerStateRequest 3 "DRIVE_SUMMON" 2 "ACCESSORY_PLUS" 1 "ACCESSORY" 0 "IDLE" ;
VAL_ 627 UI_wiperMode 3 "WIPER_MODE_PARK" 2 "WIPER_MODE_NORMAL" 1 "WIPER_MODE_SERVICE" 0 "WIPER_MODE_SNA" ;
VAL_ 627 UI_steeringBacklightEnabled 1 "ENABLED" 0 "DISABLED" ;
VAL_ 627 UI_steeringButtonMode 7 "STEERING_BUTTON_MODE_SEATS" 6 "STEERING_BUTTON_MODE_WIPERS" 5 "STEERING_BUTTON_MODE_HEADLIGHT_RIGHT" 4 "STEERING_BUTTON_MODE_HEADLIGHT_LEFT" 3 "STEERING_BUTTON_MODE_MIRROR_RIGHT" 2 "STEERING_BUTTON_MODE_MIRROR_LEFT" 1 "STEERING_BUTTON_MODE_STEERING_COLUMN_ADJ" 0 "STEERING_BUTTON_MODE_OFF" ;
VAL_ 627 UI_lockRequest 7 "UI_LOCK_REQUEST_SNA" 4 "UI_LOCK_REQUEST_REMOTE_LOCK" 3 "UI_LOCK_REQUEST_REMOTE_UNLOCK" 2 "UI_LOCK_REQUEST_UNLOCK" 1 "UI_LOCK_REQUEST_LOCK" 0 "UI_LOCK_REQUEST_IDLE" ;
VAL_ 627 UI_mirrorFoldRequest 3 "MIRROR_FOLD_REQUEST_SNA" 2 "MIRROR_FOLD_REQUEST_PRESENT" 1 "MIRROR_FOLD_REQUEST_RETRACT" 0 "MIRROR_FOLD_REQUEST_IDLE" ;
VAL_ 627 UI_remoteStartRequest 4 "UI_REMOTE_START_REQUEST_SNA" 1 "UI_REMOTE_START_REQUEST_START" 0 "UI_REMOTE_START_REQUEST_IDLE" ;
VAL_ 627 UI_displayBrightnessLevel 255 "SNA" ;
VAL_ 627 UI_frontLeftSeatHeatReq 3 "HEATER_REQUEST_LEVEL3" 2 "HEATER_REQUEST_LEVEL2" 1 "HEATER_REQUEST_LEVEL1" 0 "HEATER_REQUEST_OFF" ;
VAL_ 627 UI_frontRightSeatHeatReq 3 "HEATER_REQUEST_LEVEL3" 2 "HEATER_REQUEST_LEVEL2" 1 "HEATER_REQUEST_LEVEL1" 0 "HEATER_REQUEST_OFF" ;
VAL_ 627 UI_rearLeftSeatHeatReq 3 "HEATER_REQUEST_LEVEL3" 2 "HEATER_REQUEST_LEVEL2" 1 "HEATER_REQUEST_LEVEL1" 0 "HEATER_REQUEST_OFF" ;
VAL_ 627 UI_rearCenterSeatHeatReq 3 "HEATER_REQUEST_LEVEL3" 2 "HEATER_REQUEST_LEVEL2" 1 "HEATER_REQUEST_LEVEL1" 0 "HEATER_REQUEST_OFF" ;
VAL_ 627 UI_rearRightSeatHeatReq 3 "HEATER_REQUEST_LEVEL3" 2 "HEATER_REQUEST_LEVEL2" 1 "HEATER_REQUEST_LEVEL1" 0 "HEATER_REQUEST_OFF" ;
VAL_ 627 UI_remoteClosureRequest 3 "UI_REMOTE_CLOSURE_REQUEST_SNA" 2 "UI_REMOTE_CLOSURE_REQUEST_FRONT_TRUNK_MOVE" 1 "UI_REMOTE_CLOSURE_REQUEST_REAR_TRUNK_MOVE" 0 "UI_REMOTE_CLOSURE_REQUEST_IDLE" ;
VAL_ 627 UI_wiperRequest 6 "WIPER_REQUEST_FAST_CONTINUOUS" 5 "WIPER_REQUEST_SLOW_CONTINUOUS" 4 "WIPER_REQUEST_FAST_INTERMITTENT" 3 "WIPER_REQUEST_SLOW_INTERMITTENT" 2 "WIPER_REQUEST_AUTO" 1 "WIPER_REQUEST_OFF" 0 "WIPER_REQUEST_SNA" ;
VAL_ 627 UI_domeLightSwitch 2 "DOME_LIGHT_SWITCH_AUTO" 1 "DOME_LIGHT_SWITCH_ON" 0 "DOME_LIGHT_SWITCH_OFF" ;
VAL_ 627 UI_driveStateRequest 1 "START" 0 "IDLE" ;
VAL_ 947 UI_lightSwitch 4 "LIGHT_SWITCH_SNA" 3 "LIGHT_SWITCH_OFF" 2 "LIGHT_SWITCH_PARKING" 1 "LIGHT_SWITCH_ON" 0 "LIGHT_SWITCH_AUTO" ;
VAL_ 947 UI_summonState 3 "ACTIVE" 2 "PRE_PRIMED" 1 "IDLE" 0 "SNA" ;
VAL_ 947 UI_autopilotPowerStateRequest 2 "AUTOPILOT_SUSPEND" 1 "AUTOPILOT_SENTRY" 0 "AUTOPILOT_NOMINAL" ;
VAL_ 947 UI_shorted12VCellTestMode 2 "ACTIVE" 1 "SHADOW" 0 "DISABLED" ;
VAL_ 947 UI_frontLeftSeatFanReq 3 "FAN_REQUEST_LEVEL3" 2 "FAN_REQUEST_LEVEL2" 1 "FAN_REQUEST_LEVEL1" 0 "FAN_REQUEST_OFF" ;
VAL_ 947 UI_frontRightSeatFanReq 3 "FAN_REQUEST_LEVEL3" 2 "FAN_REQUEST_LEVEL2" 1 "FAN_REQUEST_LEVEL1" 0 "FAN_REQUEST_OFF" ;
VAL_ 947 UI_3RLeftSeatHeatReq 3 "HEATER_REQUEST_LEVEL3" 2 "HEATER_REQUEST_LEVEL2" 1 "HEATER_REQUEST_LEVEL1" 0 "HEATER_REQUEST_OFF" ;
VAL_ 947 UI_3RRightSeatHeatReq 3 "HEATER_REQUEST_LEVEL3" 2 "HEATER_REQUEST_LEVEL2" 1 "HEATER_REQUEST_LEVEL1" 0 "HEATER_REQUEST_OFF" ;
VAL_ 947 UI_dcr12VThreshold 12 "15_MILLIOHMS" 11 "16_MILLIOHMS" 10 "17_MILLIOHMS" 9 "18_MILLIOHMS" 8 "19_MILLIOHMS" 7 "20_MILLIOHMS" 6 "22_MILLIOHMS" 5 "24_MILLIOHMS" 4 "27_MILLIOHMS" 3 "30_MILLIOHMS" 2 "35_MILLIOHMS" 1 "40_MILLIOHMS" 0 "OFF" ;
VAL_ 947 UI_tireSeason 1 "WINTER" 0 "NON_WINTER" ;
VAL_ 947 UI_saveTireConfigReq 1 "TRUE" 0 "FALSE" ;
VAL_ 628 UI_lightFlashRequest 3 "LIGHT_FLASH_SENTRY" 2 "LIGHT_FLASH_MOBILE_APP" 1 "LIGHT_FLASH_HOMELINK" 0 "LIGHT_FLASH_INACTIVE" ;
VAL_ 628 UI_drivingSideVEH 2 "UNKNOWN" 1 "RIGHT" 0 "LEFT" ;
VAL_ 628 UI_keyPairResponse 2 "DENIED" 1 "CONFIRMED" 0 "NONE" ;
VAL_ 628 UI_steeringWheelHeatLevelReq 3 "STEERING_WHEEL_HEAT_LEVEL3" 2 "STEERING_WHEEL_HEAT_LEVEL2" 1 "STEERING_WHEEL_HEAT_LEVEL1" 0 "STEERING_WHEEL_HEAT_OFF" ;
VAL_ 628 UI_packTempLoggingRequest 1 "TRUE" 0 "FALSE" ;
VAL_ 628 UI_leftRearSeatAdjustmentRequest 6 "UI_ADJUSTABLE_FOLD_FLAT_REQUEST_STOP" 5 "UI_ADJUSTABLE_FOLD_FLAT_REQUEST_TOGGLE_FOLD" 4 "UI_ADJUSTABLE_FOLD_FLAT_REQUEST_REARWARD_FAST" 3 "UI_ADJUSTABLE_FOLD_FLAT_REQUEST_REARWARD_COMFORT" 2 "UI_ADJUSTABLE_FOLD_FLAT_REQUEST_FORWARD_FAST" 1 "UI_ADJUSTABLE_FOLD_FLAT_REQUEST_FORWARD_COMFORT" 0 "UI_ADJUSTABLE_FOLD_FLAT_REQUEST_NONE" ;
VAL_ 628 UI_rightRearSeatAdjustmentReques 6 "UI_ADJUSTABLE_FOLD_FLAT_REQUEST_STOP" 5 "UI_ADJUSTABLE_FOLD_FLAT_REQUEST_TOGGLE_FOLD" 4 "UI_ADJUSTABLE_FOLD_FLAT_REQUEST_REARWARD_FAST" 3 "UI_ADJUSTABLE_FOLD_FLAT_REQUEST_REARWARD_COMFORT" 2 "UI_ADJUSTABLE_FOLD_FLAT_REQUEST_FORWARD_FAST" 1 "UI_ADJUSTABLE_FOLD_FLAT_REQUEST_FORWARD_COMFORT" 0 "UI_ADJUSTABLE_FOLD_FLAT_REQUEST_NONE" ;
VAL_ 628 UI_etcBluetoothControl 3 "RESERVED" 2 "ON" 1 "OFF" 0 "INACTIVE" ;
VAL_ 628 UI_rearSeatChildLock 3 "UI_ADJUSTABLE_FOLD_FLAT_CHILD_LOCK_BOTH" 2 "UI_ADJUSTABLE_FOLD_FLAT_CHILD_LOCK_RIGHT" 1 "UI_ADJUSTABLE_FOLD_FLAT_CHILD_LOCK_LEFT" 0 "UI_ADJUSTABLE_FOLD_FLAT_CHILD_LOCK_NONE" ;
VAL_ 628 UI_windowRequest 6 "WINDOW_REQUEST_GOTO_RELATIVE_PERCENT" 5 "WINDOW_REQUEST_GOTO_CLOSED_CARWASH" 4 "WINDOW_REQUEST_GOTO_OPEN" 3 "WINDOW_REQUEST_GOTO_CLOSED" 2 "WINDOW_REQUEST_GOTO_VENT" 1 "WINDOW_REQUEST_GOTO_PERCENT" 0 "WINDOW_REQUEST_IDLE" ;
VAL_ 1193 UI_firstRowLeftDomeLightRequest 1 "DOME_LIGHT_REQUEST_ACTIVE" 0 "DOME_LIGHT_REQUEST_NONE" ;
VAL_ 1193 UI_firstRowRightDomeLightRequest 1 "DOME_LIGHT_REQUEST_ACTIVE" 0 "DOME_LIGHT_REQUEST_NONE" ;
VAL_ 1193 UI_secondRowLeftDomeLightRequest 1 "DOME_LIGHT_REQUEST_ACTIVE" 0 "DOME_LIGHT_REQUEST_NONE" ;
VAL_ 1193 UI_secondRowCenterDomeLightReque 1 "DOME_LIGHT_REQUEST_ACTIVE" 0 "DOME_LIGHT_REQUEST_NONE" ;
VAL_ 1193 UI_secondRowRightDomeLightReques 1 "DOME_LIGHT_REQUEST_ACTIVE" 0 "DOME_LIGHT_REQUEST_NONE" ;
VAL_ 1193 UI_thirdRowLeftDomeLightRequest 1 "DOME_LIGHT_REQUEST_ACTIVE" 0 "DOME_LIGHT_REQUEST_NONE" ;
VAL_ 1193 UI_thirdRowRightDomeLightRequest 1 "DOME_LIGHT_REQUEST_ACTIVE" 0 "DOME_LIGHT_REQUEST_NONE" ;
VAL_ 853 UI_geofencedLiftgateHeight 255 "INVALID_SNA" 1 "USE_DEFAULT" 0 "PENDING_SAVE" ;
VAL_ 644 UI_factoryMode 1 "ENABLED" 0 "DISABLED" ;
VAL_ 644 UI_transportMode 1 "TRANSPORT_MODE_ENABLED" 0 "TRANSPORT_MODE_DISABLED" ;
VAL_ 644 UI_showroomMode 1 "SHOWROOM_MODE_ENABLED" 0 "SHOWROOM_MODE_DISABLED" ;
VAL_ 644 UI_serviceMode 1 "SERVICE_MODE_ENABLED" 0 "SERVICE_MODE_DISABLED" ;
VAL_ 644 UI_diagnosticsAllowed 1 "ALLOWED" 0 "NOT_ALLOWED" ;
VAL_ 644 UI_serviceModePlus 1 "SERVICE_MODE_PLUS_ENABLED" 0 "SERVICE_MODE_PLUS_DISABLED" ;
VAL_ 644 UI_signedCmdHardLocked 1 "ENABLED" 0 "DISABLED" ;
VAL_ 644 UI_signedCmdServiceMode 1 "ENABLED" 0 "DISABLED" ;
VAL_ 644 UI_closureEasterEggStatus 3 "PLAYING" 2 "PRIMED" 1 "PRIMED_REMOTE" 0 "IDLE" ;
VAL_ 644 UI_lightShowType 5 "LIGHT_SHOW_TYPE_STANDARD_CNY24" 4 "LIGHT_SHOW_TYPE_STANDARD_THE_ARRIVAL" 3 "LIGHT_SHOW_TYPE_STANDARD_CNY23" 2 "LIGHT_SHOW_TYPE_STANDARD_AULD_LANG_SYNE" 1 "LIGHT_SHOW_TYPE_STANDARD_CAROL_OF_THE_BELLS" 0 "LIGHT_SHOW_TYPE_CUSTOM_USB" ;
VAL_ 644 UI_upkeepMode 1 "UI_UPKEEPMODE_ENABLED" 0 "UI_UPKEEPMODE_DISABLED" ;
VAL_ 595 UI_ventPanelControlRequestIndex 1 "1" 0 "0" ;
VAL_ 595 UI_ventPanelLeftLateralMode 2 "SWING" 1 "SPLIT" 0 "SINGLE" ;
VAL_ 595 UI_ventPanelRightLateralMode 2 "SWING" 1 "SPLIT" 0 "SINGLE" ;
VAL_ 595 UI_hvacReqActiveVents 3 "OFF" 2 "RIGHT" 1 "LEFT" 0 "BOTH" ;
VAL_ 595 UI_hvacReqThirdRowState 2 "ON" 1 "OFF" 0 "AUTO" ;
VAL_ 1569 UI_weatherSvcTimeSinceLast 127 "SNA" ;
VAL_ 1569 UI_weatherSvcWindDir 255 "SNA" 240 "MAX" 0 "MIN" ;
VAL_ 1569 UI_weatherSvcTemperature 255 "SNA" 250 "MAX" 0 "MIN" ;
VAL_ 1569 UI_weatherSvcHumidity 63 "SNA" 62 "MAX" 0 "MIN" ;
VAL_ 1569 UI_weatherSvcDewPoint 255 "SNA" 250 "MAX" 0 "MIN" ;
VAL_ 1569 UI_weatherSvcCloudCover 63 "SNA" 62 "MAX" 0 "MIN" ;
VAL_ 1569 UI_weatherSvcPrecipProb 63 "SNA" 62 "MAX" 0 "MIN" ;
VAL_ 1569 UI_weatherSvcWindSpeed 63 "SNA" 60 "MAX" 0 "MIN" ;
VAL_ 1969 UI_weatherSvcForecastMuxIndex 4 "MUX4" 3 "MUX3" 2 "MUX2" 1 "MUX1" 0 "MUX0" ;
VAL_ 1969 UI_weatherSvcForecastTempC_hour1 255 "SNA" 250 "MAX" 0 "MIN" ;
VAL_ 1969 UI_weatherSvcForecastTempC_hour2 255 "SNA" 250 "MAX" 0 "MIN" ;
VAL_ 1969 UI_weatherSvcForecastTempC_hour3 255 "SNA" 250 "MAX" 0 "MIN" ;
VAL_ 1969 UI_weatherSvcForecastTempC_hour4 255 "SNA" 250 "MAX" 0 "MIN" ;
VAL_ 1969 UI_weatherSvcForecastTempC_hour5 255 "SNA" 250 "MAX" 0 "MIN" ;
VAL_ 1969 UI_weatherSvcForecastTempC_hour6 255 "SNA" 250 "MAX" 0 "MIN" ;
VAL_ 1969 UI_weatherSvcForecastTempC_hour7 255 "SNA" 250 "MAX" 0 "MIN" ;
VAL_ 1969 UI_weatherSvcForecastTempC_hour8 255 "SNA" 250 "MAX" 0 "MIN" ;
VAL_ 1969 UI_weatherSvcForecastTempC_hour9 255 "SNA" 250 "MAX" 0 "MIN" ;
VAL_ 1969 UI_weatherSvcForecastTempC__0001 255 "SNA" 250 "MAX" 0 "MIN" ;
VAL_ 1969 UI_weatherSvcForecastTempC__0002 255 "SNA" 250 "MAX" 0 "MIN" ;
VAL_ 1969 UI_weatherSvcForecastHumidity_ho 63 "SNA" 62 "MAX" 0 "MIN" ;
VAL_ 1969 UI_weatherSvcForecastHumidi_0003 63 "SNA" 62 "MAX" 0 "MIN" ;
VAL_ 1969 UI_weatherSvcForecastHumidi_0004 63 "SNA" 62 "MAX" 0 "MIN" ;
VAL_ 1969 UI_weatherSvcForecastHumidi_0005 63 "SNA" 62 "MAX" 0 "MIN" ;
VAL_ 1969 UI_weatherSvcForecastHumidi_0006 63 "SNA" 62 "MAX" 0 "MIN" ;
VAL_ 1969 UI_weatherSvcForecastHumidi_0007 63 "SNA" 62 "MAX" 0 "MIN" ;
VAL_ 1969 UI_weatherSvcForecastHumidi_0008 63 "SNA" 62 "MAX" 0 "MIN" ;
VAL_ 1969 UI_weatherSvcForecastHumidi_0009 63 "SNA" 62 "MAX" 0 "MIN" ;
VAL_ 1969 UI_weatherSvcForecastHumidi_0010 63 "SNA" 62 "MAX" 0 "MIN" ;
VAL_ 1969 UI_weatherSvcForecastHumidi_0001 63 "SNA" 62 "MAX" 0 "MIN" ;
VAL_ 1969 UI_weatherSvcForecastHumidi_0002 63 "SNA" 62 "MAX" 0 "MIN" ;
VAL_ 1969 UI_weatherSvcForecastWindSpeedKp 63 "SNA" 60 "MAX" 0 "MIN" ;
VAL_ 1969 UI_weatherSvcForecastWindSp_0003 63 "SNA" 60 "MAX" 0 "MIN" ;
VAL_ 1969 UI_weatherSvcForecastWindSp_0004 63 "SNA" 60 "MAX" 0 "MIN" ;
VAL_ 1969 UI_weatherSvcForecastWindSp_0005 63 "SNA" 60 "MAX" 0 "MIN" ;
VAL_ 1969 UI_weatherSvcForecastWindSp_0006 63 "SNA" 60 "MAX" 0 "MIN" ;
VAL_ 1969 UI_weatherSvcForecastWindSp_0007 63 "SNA" 60 "MAX" 0 "MIN" ;
VAL_ 1969 UI_weatherSvcForecastWindSp_0008 63 "SNA" 60 "MAX" 0 "MIN" ;
VAL_ 1969 UI_weatherSvcForecastWindSp_0009 63 "SNA" 60 "MAX" 0 "MIN" ;
VAL_ 1969 UI_weatherSvcForecastWindSp_0010 63 "SNA" 60 "MAX" 0 "MIN" ;
VAL_ 1969 UI_weatherSvcForecastWindSp_0001 63 "SNA" 60 "MAX" 0 "MIN" ;
VAL_ 1969 UI_weatherSvcForecastWindSp_0002 63 "SNA" 60 "MAX" 0 "MIN" ;
VAL_ 1533 UMC_alertID 42 "a042_GFCICalRelayDelta" 41 "a041_handleTempIrrational" 40 "a040_gndDisconnected" 39 "a039_inputOverCurrent" 38 "a038_chcVitalsFault" 37 "a037_GFCICalibration" 35 "a035_v2lHVACDetected" 34 "a034_v2lSAUnsupported" 33 "a033_chcUpdateFault" 32 "a032_chcVitalsRequestFailure" 31 "a031_relayCoilVIrrational" 30 "a030_acLostPllLock" 29 "a029_acPowerLoss" 28 "a028_processorBooted" 27 "a027_watchdogExpired" 26 "a026_vRefOutOfRange" 25 "a025_cntrOpenExpectedClose" 24 "a024_gndResistanceHigh" 23 "a023_adcSelfTest" 22 "a022_criticalRAM" 21 "a021_dataBus" 20 "a020_applicationCRC" 19 "a019_inputOTFoldback" 18 "a018_vehConnOTFoldback" 17 "a017_wallPlugOTFoldback" 16 "a016_pcbaOTFoldback" 15 "a015_SA_Connection" 14 "a014_SA_Genealogy" 13 "a013_SA_Temperature" 12 "a012_pilotFault" 11 "a011_proxDisconnected" 10 "a010_inputOT" 9 "a009_vehConnOT" 8 "a008_wallPlugOT" 7 "a007_pcbaOT" 6 "a006_contactorWelded" 5 "a005_inputUnderVoltage" 4 "a004_inputOverVoltage" 3 "a003_GFCISelfTestFault" 2 "a002_GFCITripped" 1 "a001_gndMonIntrptLineSide" 0 "ALERT_DO_NOT_USE_ZERO" ;
VAL_ 1533 UMC_alertType 1 "SET" 0 "CLEARED" ;
VAL_ 1533 UMC_a002_ccidFaultReason 4 "DC_PEAK" 3 "DC_LPF" 2 "AC_PEAK" 1 "AC_LPF" 0 "SNA" ;
VAL_ 1533 UMC_a003_faultType 1 "SELFTEST" 0 "POWERON" ;
VAL_ 1533 UMC_a006_faultType 1 "OPENED" 0 "WELDED" ;
VAL_ 1533 UMC_a018_vehConnTemp 215 "SHORTED" 214 "OPENED" ;
VAL_ 1533 UMC_a019_inputTerminalsTemp 215 "SHORTED" 214 "OPENED" ;
VAL_ 1285 SA_infoIndex 32 "Mux32" 31 "Mux31" 30 "Mux30" 29 "Mux29" 27 "Mux27" 26 "Mux26" 25 "Mux25" 11 "Mux11" 0 "Mux0" ;
VAL_ 1285 SA_region 6 "SA_REGION_INDIA" 5 "SA_REGION_SOUTH_KOREA" 4 "SA_REGION_AUSTRALIA" 3 "SA_REGION_JAPAN" 2 "SA_REGION_CHINA" 1 "SA_REGION_EU" 0 "SA_REGION_NA" ;
